VERSION "HNNBNNNYNNNNNNNNNNNNNNNNNNNNNNNNNNNNNNNNNN/4/%%%/4/'%**4NNN///"

NS_ :

BS_:

BU_: _4CL_C6 _6HP_C6 Airbag_C6 CVT_C6 DME_EDC16CP3000 DME_ME7_MED9_C6 DME_SIMOS6_C6 DME_Slave EPB_C6 ESP8_C6 Gateway_C6 LWR_AFS_C6 LWS_C6

BO_ 1160 Motor_6: 8 DME_EDC16CP3000
 SG_ CHK_Motor6 : 0|8@1+ (1.0,0.0) [0.0|255.0] ""  CVT_C6
 SG_ Sollmoment_Getriebe : 8|8@1+ (0.39,0.0) [0.0|99.06] "%MDI"  _6HP_C6,CVT_C6
 SG_ Istmoment_Getriebe : 16|8@1+ (0.39,0.0) [0.0|99.06] "%MDI"  _6HP_C6,CVT_C6
 SG_ Hoeheninfo : 24|8@1+ (0.00781,0.0) [0.0|1.99219] ""  _6HP_C6
 SG_ GRA_Sollbeschleunigung : 32|8@1+ (0.024,-3.984) [-3.984|2.112] "m/s2"  _6HP_C6
 SG_ Rueckmeldung_Momentenintegral : 40|8@1+ (0.3921,0.0) [0.0|99.9855] ""  Vector__XXX
 SG_ Calculated_Load_Value m0  : 48|8@1+ (0.4,0.0) [0.0|101.6] "%"  Vector__XXX
 SG_ Absolute_Throttle_Position m1  : 48|8@1+ (0.4,0.0) [0.0|101.6] "%"  Vector__XXX
 SG_ Engine_Coolant_Temperature m2  : 48|8@1+ (1.0,-40.0) [-40.0|215.0] "°C"  Vector__XXX
 SG_ Absolute_Load_Value m3  : 48|8@1+ (3.14,0.0) [0.0|800.7] "%"  Vector__XXX
 SG_ Accelerator_Pedal_Position m4  : 48|8@1+ (0.4,0.0) [0.0|101.6] "%"  Vector__XXX
 SG_ GRA_Bremseingrifffreigabe : 56|1@1+ (1.0,0.0) [0.0|1.0] ""  Vector__XXX
 SG_ Oeltemperaturschutz : 57|1@1+ (1.0,0.0) [0.0|1.0] ""  _6HP_C6
 SG_ Luftpfad_aktiv : 58|1@1+ (1.0,0.0) [0.0|1.0] ""  Vector__XXX
 SG_ Partikelfilter_Regeneration : 59|1@1+ (1.0,0.0) [0.0|1.0] ""  _6HP_C6
 SG_ BZ_Muxcode_Motor6 M  : 60|4@1+ (1.0,0.0) [0.0|15.0] ""  CVT_C6

BO_ 1416 Motor_7: 8 DME_EDC16CP3000
 SG_ RLS_Stufe1 : 0|1@1+ (1.0,0.0) [0.0|1.0] ""  Gateway_C6
 SG_ V_Begrenz_Aktivierbar : 1|1@1+ (1.0,0.0) [0.0|1.0] ""  Gateway_C6
 SG_ V_Begrenz_Aktiv : 2|1@1+ (1.0,0.0) [0.0|1.0] ""  Gateway_C6
 SG_ FSPE_Motor7 : 3|1@1+ (1.0,0.0) [0.0|1.0] ""  Gateway_C6
 SG_ FStatus_Oeltemp_Motor : 4|1@1+ (1.0,0.0) [0.0|1.0] ""  Gateway_C6
 SG_ PTC_Gluehstifte_ausgeschaltet : 5|3@1+ (1.0,0.0) [0.0|7.0] ""  Gateway_C6
 SG_ Klemme_DFM : 8|8@1+ (0.4,0.0) [0.0|101.6] "%"  Gateway_C6
 SG_ Hoeheninfo : 16|8@1+ (0.00781,0.0) [0.0|1.99219] ""  Gateway_C6
 SG_ MDG : 24|7@1+ (1.0,0.0) [0.0|126.0] "1/min"  Gateway_C6
 SG_ Signum_MDG : 31|1@1+ (1.0,0.0) [0.0|1.0] ""  Gateway_C6
 SG_ Ladedruck : 32|8@1+ (0.01,0.0) [0.0|2.54] "bar"  Gateway_C6
 SG_ GLR_Motor : 40|2@1+ (3.0,0.0) [0.0|9.0] "s"  Gateway_C6
 SG_ Bereitschaft_PTC_Heizung : 42|2@1+ (1.0,0.0) [0.0|3.0] ""  Gateway_C6
 SG_ Zusaetzliche_Kuehlung : 45|1@1+ (1.0,0.0) [0.0|1.0] ""  Gateway_C6
 SG_ SIB_Motor : 46|1@1+ (1.0,0.0) [0.0|1.0] ""  Gateway_C6
 SG_ RLS_Stufe2 : 47|1@1+ (1.0,0.0) [0.0|1.0] ""  Gateway_C6
 SG_ Lastabwurf : 48|2@1+ (1.0,0.0) [0.0|3.0] ""  Gateway_C6
 SG_ Einschalten_Generator : 50|1@1+ (1.0,0.0) [0.0|1.0] ""  Gateway_C6
 SG_ Lastabwurf_Heizsysteme : 51|1@1+ (1.0,0.0) [0.0|1.0] ""  Gateway_C6
 SG_ Gluehkerzen_Brennr : 52|4@1+ (8.0,0.0) [0.0|120.0] "%"  Gateway_C6
 SG_ Oeltemperatur : 56|8@1+ (1.0,-60.0) [-58.0|194.0] "°C"  Gateway_C6

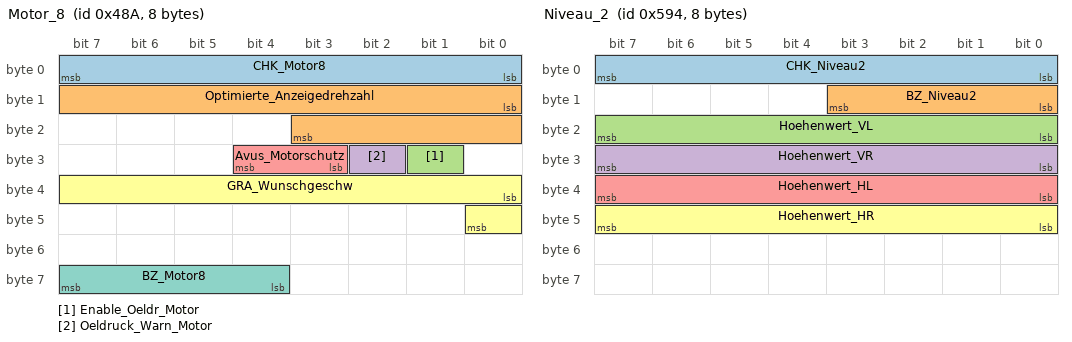
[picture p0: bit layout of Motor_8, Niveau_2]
BO_ 1162 Motor_8: 8 DME_EDC16CP3000
 SG_ CHK_Motor8 : 0|8@1+ (1.0,0.0) [0.0|255.0] ""  Gateway_C6
 SG_ Optimierte_Anzeigedrehzahl : 8|12@1+ (3.0,0.0) [0.0|12282.0] "1/min"  Gateway_C6
 SG_ Enable_Oeldr_Motor : 25|1@1+ (1.0,0.0) [0.0|1.0] ""  Gateway_C6
 SG_ Oeldruck_Warn_Motor : 26|1@1+ (1.0,0.0) [0.0|1.0] ""  Gateway_C6
 SG_ Avus_Motorschutz : 27|2@1+ (1.0,0.0) [0.0|3.0] ""  Gateway_C6
 SG_ GRA_Wunschgeschw : 32|9@1+ (1.0,0.0) [0.0|511.0] "km/h"  Gateway_C6
 SG_ BZ_Motor8 : 60|4@1+ (1.0,0.0) [0.0|15.0] ""  Gateway_C6

BO_ 1408 Motor_Flexia_Neu: 8 DME_EDC16CP3000
 SG_ Mux_Code_MFn M  : 0|2@1+ (1.0,0.0) [0.0|3.0] ""  Gateway_C6
 SG_ BZ_MFn_Rest : 2|2@1+ (1.0,0.0) [0.0|3.0] ""  Gateway_C6
 SG_ Driving_Cycle : 4|1@1+ (1.0,0.0) [0.0|1.0] ""  Gateway_C6
 SG_ Warm_Up_Cycle : 5|1@1+ (1.0,0.0) [0.0|1.0] ""  _6HP_C6,Gateway_C6
 SG_ Normed_Trip : 6|1@1+ (1.0,0.0) [0.0|1.0] ""  Gateway_C6
 SG_ Verbrennungsart : 7|1@1+ (1.0,0.0) [0.0|1.0] ""  ESP8_C6,Gateway_C6
 SG_ Russaequivalent m0  : 8|16@1+ (2.0E-8,0.0) [0.0|0.00131068] ""  Gateway_C6
 SG_ Verschleissequivalent m1  : 8|16@1+ (2.0E-8,0.0) [0.0|0.00131068] ""  Gateway_C6
 SG_ Russaequivalent m2  : 8|16@1+ (2.0E-8,0.0) [0.0|0.00131068] ""  Gateway_C6
 SG_ Verschleissequivalent m3  : 8|16@1+ (2.0E-8,0.0) [0.0|0.00131068] ""  Gateway_C6
 SG_ Drehzahl_MaxMom m0  : 24|8@1+ (100.0,0.0) [0.0|25500.0] "1/min"  Gateway_C6
 SG_ Kurzzeitmittelwert m1  : 24|8@1+ (15.0,-1905.0) [-1890.0|1905.0] "ml"  Gateway_C6
 SG_ Drehzahl_MaxMom m2  : 24|8@1+ (100.0,0.0) [0.0|25500.0] "1/min"  Gateway_C6
 SG_ Intervall_Wmin m3  : 24|7@1+ (1000.0,0.0) [0.0|127000.0] "km"  Gateway_C6
 SG_ Ueberfuellerkennung_aktiv m3  : 31|1@1+ (1.0,0.0) [0.0|1.0] ""  Gateway_C6
 SG_ Max_Drehmoment_2550Nm m0  : 32|8@1+ (10.0,0.0) [0.0|2550.0] "Nm"  Gateway_C6
 SG_ Oelstandszaehler m1  : 32|6@1+ (1.0,0.0) [0.0|63.0] ""  Gateway_C6
 SG_ Max_Drehmoment_2550Nm m2  : 32|8@1+ (10.0,0.0) [0.0|2550.0] "Nm"  Gateway_C6
 SG_ Intervall_Wmax m3  : 32|7@1+ (1000.0,0.0) [0.0|127000.0] "km"  Gateway_C6
 SG_ Oelwarnung m1  : 38|1@1+ (1.0,0.0) [0.0|1.0] ""  Gateway_C6
 SG_ Sensorwarnung m1  : 39|1@1+ (1.0,0.0) [0.0|1.0] ""  Gateway_C6
 SG_ Schwellwert_Max_Oelstand m3  : 39|5@1+ (100.0,0.0) [0.0|3100.0] "ml"  Gateway_C6
 SG_ Motorleistung m0  : 40|9@1+ (1.0,0.0) [0.0|511.0] "kW"  Gateway_C6
 SG_ Anzahl_Mittelung_sO m1  : 40|4@1+ (100.0,0.0) [0.0|1500.0] ""  Gateway_C6
 SG_ Motorleistung m2  : 40|9@1+ (1.0,0.0) [0.0|511.0] "kW"  ESP8_C6,Gateway_C6
 SG_ Maximum_Offset m1  : 44|4@1+ (50.0,0.0) [0.0|750.0] "ml"  Gateway_C6
 SG_ Anzahl_Mittelwert_gO m3  : 44|4@1+ (500.0,0.0) [0.0|7500.0] ""  Gateway_C6
 SG_ Ueberfuell_Hysterese m1  : 48|4@1+ (50.0,0.0) [0.0|750.0] "ml"  Gateway_C6
 SG_ Intervall_tmin m3  : 48|6@1+ (1.0,0.0) [0.0|63.0] "month"  Gateway_C6
 SG_ Anzahl_Ventile m0  : 49|3@1+ (1.0,0.0) [0.0|7.0] ""  Gateway_C6
 SG_ Anzahl_Ventile m2  : 49|3@1+ (1.0,0.0) [0.0|7.0] ""  Gateway_C6
 SG_ Anzahl_Zylinder m0  : 52|4@1+ (1.0,0.0) [0.0|15.0] ""  ESP8_C6,Gateway_C6
 SG_ Oelwarnschwellen_Offset m1  : 52|6@1+ (10.0,0.0) [0.0|630.0] "ml"  Gateway_C6
 SG_ Anzahl_Zylinder m2  : 52|4@1+ (1.0,0.0) [0.0|15.0] ""  Gateway_C6
 SG_ Intervall_tmax m3  : 54|6@1+ (1.0,0.0) [0.0|63.0] "month"  Gateway_C6
 SG_ Hubraum m0  : 56|7@1+ (0.1,0.0) [0.0|12.7] "l"  ESP8_C6,Gateway_C6
 SG_ Hubraum m2  : 56|7@1+ (0.1,0.0) [0.0|12.7] "l"  Gateway_C6
 SG_ Oelwarnschwellen_Toleranz m1  : 58|6@1+ (10.0,0.0) [0.0|630.0] "ml"  Gateway_C6
 SG_ Strecke_Mittelung m3  : 60|4@1+ (25.0,0.0) [0.0|375.0] "km"  Gateway_C6
 SG_ Ansaugsystem m0  : 63|1@1+ (1.0,0.0) [0.0|1.0] ""  ESP8_C6,Gateway_C6
 SG_ Ansaugsystem m2  : 63|1@1+ (1.0,0.0) [0.0|1.0] ""  Gateway_C6

BO_ 1823 Motorslave_Istverbau: 1 DME_Slave
 SG_ FSPE_Motorslave : 0|1@1+ (1.0,0.0) [0.0|1.0] ""  Gateway_C6

BO_ 1424 Niveau_1: 8 _4CL_C6
 SG_ CHK_Niveau1 : 0|8@1+ (1.0,0.0) [0.0|255.0] ""  ESP8_C6,Gateway_C6
 SG_ BZ_Niveau1 : 8|4@1+ (1.0,0.0) [0.0|15.0] ""  ESP8_C6,Gateway_C6
 SG_ Fehlerlampe_Niveau : 12|1@1+ (1.0,0.0) [0.0|1.0] ""  Gateway_C6
 SG_ Warnlampe : 13|1@1+ (1.0,0.0) [0.0|1.0] ""  Gateway_C6
 SG_ ESP_Beeinflussung : 14|1@1+ (1.0,0.0) [0.0|1.0] ""  ESP8_C6,Gateway_C6
 SG_ MSG_Einschraenkung : 15|1@1+ (1.0,0.0) [0.0|1.0] ""  Gateway_C6
 SG_ Niveaustati : 16|4@1+ (1.0,0.0) [0.0|15.0] ""  Gateway_C6
 SG_ Zwischenniveau : 20|1@1+ (1.0,0.0) [0.0|1.0] ""  Gateway_C6
 SG_ Parkniveau : 21|1@1+ (1.0,0.0) [0.0|1.0] ""  Gateway_C6
 SG_ Taster_Niveau : 22|1@1+ (1.0,0.0) [0.0|1.0] ""  Gateway_C6
 SG_ Verstellung_in_Kuerze : 23|1@1+ (1.0,0.0) [0.0|1.0] ""  Gateway_C6
 SG_ Kompressorlauf_in_Kuerze : 24|1@1+ (1.0,0.0) [0.0|1.0] ""  Gateway_C6
 SG_ Verstellung_aktiv : 25|1@1+ (1.0,0.0) [0.0|1.0] ""  Gateway_C6
 SG_ Anhebung_Fahrzeug : 26|1@1+ (1.0,0.0) [0.0|1.0] ""  Gateway_C6,LWR_AFS_C6
 SG_ Absenkung_Fahrzeug : 27|1@1+ (1.0,0.0) [0.0|1.0] ""  Gateway_C6,LWR_AFS_C6
 SG_ Verstellung_VR : 28|1@1+ (1.0,0.0) [0.0|1.0] ""  Gateway_C6
 SG_ Verstellung_VL : 29|1@1+ (1.0,0.0) [0.0|1.0] ""  Gateway_C6
 SG_ Verstellung_HR : 30|1@1+ (1.0,0.0) [0.0|1.0] ""  Gateway_C6
 SG_ Verstellung_HL : 31|1@1+ (1.0,0.0) [0.0|1.0] ""  Gateway_C6
 SG_ Textbits_Niveau : 32|4@1+ (1.0,0.0) [0.0|15.0] ""  Gateway_C6
 SG_ Fahrzeugart_Niveau : 36|1@1+ (1.0,0.0) [0.0|1.0] ""  Gateway_C6
 SG_ SIB_Niveau : 37|1@1+ (1.0,0.0) [0.0|1.0] ""  Gateway_C6
 SG_ Systemstatus : 38|1@1+ (1.0,0.0) [0.0|1.0] ""  Gateway_C6
 SG_ FSPE_Niveau1 : 39|1@1+ (1.0,0.0) [0.0|1.0] ""  Gateway_C6
 SG_ Beladungszustand : 40|8@1+ (1.0,0.0) [0.0|253.0] "%"  Gateway_C6
 SG_ Stromaufnahme : 48|8@1+ (1.0,0.0) [0.0|253.0] "A"  Gateway_C6
 SG_ Aufpruefbit_Warnlampe_Niveau : 56|1@1+ (1.0,0.0) [0.0|1.0] ""  Gateway_C6
 SG_ Tiefniveaulampe : 57|1@1+ (1.0,0.0) [0.0|1.0] ""  Gateway_C6
 SG_ Kompressor_laeuft : 58|1@1+ (1.0,0.0) [0.0|1.0] ""  Gateway_C6

BO_ 1428 Niveau_2: 8 _4CL_C6
 SG_ CHK_Niveau2 : 0|8@1+ (1.0,0.0) [0.0|255.0] ""  Vector__XXX
 SG_ BZ_Niveau2 : 8|4@1+ (1.0,0.0) [0.0|15.0] ""  Vector__XXX
 SG_ Hoehenwert_VL : 16|8@1+ (1.0,-127.0) [-127.0|126.0] "mm"  _6HP_C6,LWR_AFS_C6
 SG_ Hoehenwert_VR : 24|8@1+ (1.0,-127.0) [-127.0|126.0] "mm"  _6HP_C6,LWR_AFS_C6
 SG_ Hoehenwert_HL : 32|8@1+ (1.0,-127.0) [-127.0|126.0] "mm"  _6HP_C6,LWR_AFS_C6
 SG_ Hoehenwert_HR : 40|8@1+ (1.0,-127.0) [-127.0|126.0] "mm"  _6HP_C6,LWR_AFS_C6

BO_ 1434 Niveau_3: 6 _4CL_C6
 SG_ Textbit1 : 0|1@1+ (1.0,0.0) [0.0|1.0] ""  Gateway_C6
 SG_ Textbit2 : 1|1@1+ (1.0,0.0) [0.0|1.0] ""  Gateway_C6
 SG_ Textbit3 : 2|1@1+ (1.0,0.0) [0.0|1.0] ""  Gateway_C6
 SG_ Textbit4 : 3|1@1+ (1.0,0.0) [0.0|1.0] ""  Gateway_C6
 SG_ Verfuegbarkeit_FIS : 14|1@1+ (1.0,0.0) [0.0|1.0] ""  Gateway_C6
 SG_ Priorisierung_FIS : 15|1@1+ (1.0,0.0) [0.0|1.0] ""  Gateway_C6
 SG_ Anzeigebit9 : 16|1@1+ (1.0,0.0) [0.0|1.0] ""  Gateway_C6
 SG_ Anzeigebit10 : 17|1@1+ (1.0,0.0) [0.0|1.0] ""  Gateway_C6
 SG_ Anzeigebit17 : 24|1@1+ (1.0,0.0) [0.0|1.0] ""  Gateway_C6
 SG_ Anzeigebit18 : 25|1@1+ (1.0,0.0) [0.0|1.0] ""  Gateway_C6
 SG_ Anzeigebit19 : 26|1@1+ (1.0,0.0) [0.0|1.0] ""  Gateway_C6
 SG_ Anzeigebit20 : 27|1@1+ (1.0,0.0) [0.0|1.0] ""  Gateway_C6
 SG_ Anzeigebit21 : 28|1@1+ (1.0,0.0) [0.0|1.0] ""  Gateway_C6
 SG_ Anzeigebit22 : 29|1@1+ (1.0,0.0) [0.0|1.0] ""  Gateway_C6
 SG_ Anzeigebit23 : 30|1@1+ (1.0,0.0) [0.0|1.0] ""  Gateway_C6
 SG_ Anzeigebit24 : 31|1@1+ (1.0,0.0) [0.0|1.0] ""  Gateway_C6
 SG_ Anzeigebit25 : 32|1@1+ (1.0,0.0) [0.0|1.0] ""  Gateway_C6
 SG_ Anzeigebit26 : 33|1@1+ (1.0,0.0) [0.0|1.0] ""  Gateway_C6

BO_ 2004 PSD: 8 Gateway_C6
 SG_ Mux_Code_PSD M  : 0|2@1+ (1.0,0.0) [0.0|3.0] ""  Vector__XXX
 SG_ Geschwindigkeitsklasse_1 m0  : 2|4@1+ (1.0,0.0) [0.0|15.0] ""  Vector__XXX
 SG_ Geschwindigkeitsklasse_3 m1  : 2|4@1+ (1.0,0.0) [0.0|15.0] ""  Vector__XXX
 SG_ Geschwindigkeitsklasse_5 m2  : 2|4@1+ (1.0,0.0) [0.0|15.0] ""  Vector__XXX
 SG_ Strassenklasse_1 m0  : 6|2@1+ (1.0,0.0) [0.0|3.0] ""  Vector__XXX
 SG_ Strassenklasse_3 m1  : 6|2@1+ (1.0,0.0) [0.0|3.0] ""  Vector__XXX
 SG_ Strassenklasse_5 m2  : 6|2@1+ (1.0,0.0) [0.0|3.0] ""  Vector__XXX
 SG_ Segmentlaenge_1 m0  : 8|7@1+ (2.0,0.0) [0.0|254.0] "m"  Vector__XXX
 SG_ Segmentlaenge_3 m1  : 8|7@1+ (2.0,0.0) [0.0|254.0] "m"  Vector__XXX
 SG_ Segmentlaenge_5 m2  : 8|7@1+ (2.0,0.0) [0.0|254.0] "m"  Vector__XXX
 SG_ Signum_Endkruemmung_1 m0  : 15|1@1+ (1.0,0.0) [0.0|1.0] ""  Vector__XXX
 SG_ Signum_Endkruemmung_3 m1  : 15|1@1+ (1.0,0.0) [0.0|1.0] ""  Vector__XXX
 SG_ Signum_Endkruemmung_5 m2  : 15|1@1+ (1.0,0.0) [0.0|1.0] ""  Vector__XXX
 SG_ Endkruemmung_1 m0  : 16|8@1+ (1.0,0.0) [0.0|255.0] ""  Vector__XXX
 SG_ Endkruemmung_3 m1  : 16|8@1+ (1.0,0.0) [0.0|255.0] ""  Vector__XXX
 SG_ Endkruemmung_5 m2  : 16|8@1+ (1.0,0.0) [0.0|255.0] ""  Vector__XXX
 SG_ Bes_Geschw_klasse_1 m0  : 24|1@1+ (1.0,0.0) [0.0|1.0] ""  Vector__XXX
 SG_ Bes_Geschw_klasse_3 m1  : 24|1@1+ (1.0,0.0) [0.0|1.0] ""  Vector__XXX
 SG_ Bes_Geschw_klasse_5 m2  : 24|1@1+ (1.0,0.0) [0.0|1.0] ""  Vector__XXX
 SG_ Bes_Geschw_klasse_2 m0  : 25|1@1+ (1.0,0.0) [0.0|1.0] ""  Vector__XXX
 SG_ Bes_Geschw_klasse_4 m1  : 25|1@1+ (1.0,0.0) [0.0|1.0] ""  Vector__XXX
 SG_ Bes_Geschw_klasse_6 m2  : 25|1@1+ (1.0,0.0) [0.0|1.0] ""  Vector__XXX
 SG_ Geschwindigkeitsklasse_2 m0  : 26|4@1+ (1.0,0.0) [0.0|15.0] ""  Vector__XXX
 SG_ Geschwindigkeitsklasse_4 m1  : 26|4@1+ (1.0,0.0) [0.0|15.0] ""  Vector__XXX
 SG_ Geschwindigkeitsklasse_6 m2  : 26|4@1+ (1.0,0.0) [0.0|15.0] ""  Vector__XXX
 SG_ Strassenklasse_2 m0  : 30|2@1+ (1.0,0.0) [0.0|3.0] ""  Vector__XXX
 SG_ Strassenklasse_4 m1  : 30|2@1+ (1.0,0.0) [0.0|3.0] ""  Vector__XXX
 SG_ Strassenklasse_6 m2  : 30|2@1+ (1.0,0.0) [0.0|3.0] ""  Vector__XXX
 SG_ Segmentlaenge_2 m0  : 32|7@1+ (2.0,0.0) [0.0|127.0] "m"  Vector__XXX
 SG_ Segmentlaenge_4 m1  : 32|7@1+ (2.0,0.0) [0.0|127.0] "m"  Vector__XXX
 SG_ Segmentlaenge_6 m2  : 32|7@1+ (2.0,0.0) [0.0|127.0] "m"  Vector__XXX
 SG_ Signum_Endkruemmung_2 m0  : 39|1@1+ (1.0,0.0) [0.0|1.0] ""  Vector__XXX
 SG_ Signum_Endkruemmung_4 m1  : 39|1@1+ (1.0,0.0) [0.0|1.0] ""  Vector__XXX
 SG_ Signum_Endkruemmung_6 m2  : 39|1@1+ (1.0,0.0) [0.0|1.0] ""  Vector__XXX
 SG_ Endkruemmung_2 m0  : 40|8@1+ (1.0,0.0) [0.0|255.0] ""  Vector__XXX
 SG_ Endkruemmung_4 m1  : 40|8@1+ (1.0,0.0) [0.0|255.0] ""  Vector__XXX
 SG_ Endkruemmung_6 m2  : 40|8@1+ (1.0,0.0) [0.0|255.0] ""  Vector__XXX
 SG_ Alter_der_Daten m0  : 48|5@1+ (10.0,0.0) [0.0|310.0] "ms"  Vector__XXX
 SG_ Standort m1  : 48|2@1+ (1.0,0.0) [0.0|3.0] ""  Vector__XXX
 SG_ Status_Innerorts m2  : 48|1@1+ (1.0,0.0) [0.0|1.0] ""  Vector__XXX
 SG_ Status_Unterfuehrung m2  : 49|1@1+ (1.0,0.0) [0.0|1.0] ""  Vector__XXX
 SG_ Laengsfehler m1  : 50|3@1+ (1.0,0.0) [0.0|7.0] ""  Vector__XXX
 SG_ Aenderung_Innerorts m2  : 50|3@1+ (1.0,0.0) [0.0|7.0] ""  Vector__XXX
 SG_ Einheit_Geschw_klasse m0  : 53|1@1+ (1.0,0.0) [0.0|1.0] ""  Vector__XXX
 SG_ Digitalisierung m1  : 53|1@1+ (1.0,0.0) [0.0|1.0] ""  Vector__XXX
 SG_ Aenderung_Unterfuehrung m2  : 53|3@1+ (1.0,0.0) [0.0|7.0] ""  Vector__XXX
 SG_ Qualitaet m0  : 54|1@1+ (1.0,0.0) [0.0|1.0] ""  Vector__XXX
 SG_ Verkehrsrichtung m1  : 54|1@1+ (1.0,0.0) [0.0|1.0] ""  Vector__XXX
 SG_ Signum_Startkruemmung_1 m0  : 55|1@1+ (1.0,0.0) [0.0|1.0] ""  Vector__XXX
 SG_ Einbahnstrasse m1  : 55|1@1+ (1.0,0.0) [0.0|1.0] ""  Vector__XXX
 SG_ Startkruemmung_1 m0  : 56|8@1+ (1.0,0.0) [0.0|255.0] ""  Vector__XXX
 SG_ Fahrspuren_in_Fahrtrichtung m1  : 56|3@1+ (1.0,0.0) [0.0|7.0] ""  Vector__XXX
 SG_ Kreuzung m2  : 56|3@1+ (1.0,0.0) [0.0|7.0] ""  Vector__XXX
 SG_ Typ_besond_Geschw_klasse m1  : 59|3@1+ (1.0,0.0) [0.0|7.0] ""  Vector__XXX

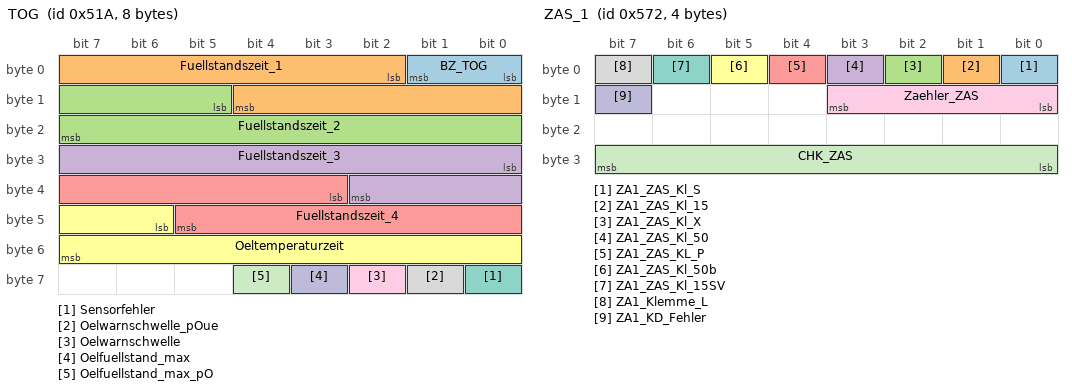
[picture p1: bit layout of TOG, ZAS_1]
BO_ 1306 TOG: 8 Gateway_C6
 SG_ BZ_TOG : 0|2@1+ (1.0,0.0) [0.0|3.0] ""  DME_EDC16CP3000,DME_ME7_MED9_C6,DME_SIMOS6_C6
 SG_ Fuellstandszeit_1 : 2|11@1+ (0.5,100.0) [101.0|1123.0] "ms"  DME_EDC16CP3000,DME_ME7_MED9_C6,DME_SIMOS6_C6
 SG_ Fuellstandszeit_2 : 13|11@1+ (0.5,100.0) [101.0|1123.0] "ms"  DME_EDC16CP3000,DME_ME7_MED9_C6,DME_SIMOS6_C6
 SG_ Fuellstandszeit_3 : 24|11@1+ (0.5,100.0) [101.0|1123.0] "ms"  DME_EDC16CP3000,DME_ME7_MED9_C6,DME_SIMOS6_C6
 SG_ Fuellstandszeit_4 : 35|11@1+ (0.5,100.0) [101.0|1123.0] "ms"  DME_EDC16CP3000,DME_ME7_MED9_C6,DME_SIMOS6_C6
 SG_ Oeltemperaturzeit : 46|10@1+ (0.125,0.0) [0.0|127.0] "ms"  DME_EDC16CP3000,DME_ME7_MED9_C6,DME_SIMOS6_C6
 SG_ Sensorfehler : 56|1@1+ (1.0,0.0) [0.0|1.0] ""  DME_EDC16CP3000,DME_ME7_MED9_C6,DME_SIMOS6_C6
 SG_ Oelwarnschwelle_pOue : 57|1@1+ (1.0,0.0) [0.0|1.0] ""  DME_EDC16CP3000,DME_ME7_MED9_C6,DME_SIMOS6_C6
 SG_ Oelwarnschwelle : 58|1@1+ (1.0,0.0) [0.0|1.0] ""  DME_EDC16CP3000,DME_ME7_MED9_C6,DME_SIMOS6_C6
 SG_ Oelfuellstand_max : 59|1@1+ (1.0,0.0) [0.0|1.0] ""  DME_EDC16CP3000,DME_SIMOS6_C6
 SG_ Oelfuellstand_max_pO : 60|1@1+ (1.0,0.0) [0.0|1.0] ""  DME_EDC16CP3000,DME_SIMOS6_C6

BO_ 1936 TP_dyn_ABS_1: 8 Vector__XXX
 SG_ TP_dyn_Data : 0|64@1+ (1.0,0.0) [0.0|1.8446744073709552E19] ""  Vector__XXX

BO_ 1937 TP_dyn_ABS_2: 8 Vector__XXX
 SG_ TP_dyn_Data : 0|64@1+ (1.0,0.0) [0.0|1.8446744073709552E19] ""  Vector__XXX

BO_ 1904 TP_dyn_ACC_1: 8 Vector__XXX
 SG_ TP_dyn_Data : 0|64@1+ (1.0,0.0) [0.0|1.8446744073709552E19] ""  Vector__XXX

BO_ 1905 TP_dyn_ACC_2: 8 Vector__XXX
 SG_ TP_dyn_Data : 0|64@1+ (1.0,0.0) [0.0|1.8446744073709552E19] ""  Vector__XXX

BO_ 1896 TP_dyn_Airbag_1: 8 Vector__XXX
 SG_ TP_dyn_Data : 0|64@1+ (1.0,0.0) [0.0|1.8446744073709552E19] ""  Airbag_C6

BO_ 1897 TP_dyn_Airbag_2: 8 Vector__XXX
 SG_ TP_dyn_Data : 0|64@1+ (1.0,0.0) [0.0|1.8446744073709552E19] ""  Airbag_C6

BO_ 822 TP_dyn_Anhaenger_1: 8 Vector__XXX
 SG_ TP_dyn_Data : 0|64@1+ (1.0,0.0) [0.0|1.8446744073709552E19] ""  Vector__XXX

BO_ 823 TP_dyn_Anhaenger_2: 8 Vector__XXX
 SG_ TP_dyn_Data : 0|64@1+ (1.0,0.0) [0.0|1.8446744073709552E19] ""  Vector__XXX

BO_ 812 TP_dyn_BEM_1: 8 Vector__XXX
 SG_ TP_dyn_Data : 0|64@1+ (1.0,0.0) [0.0|1.8446744073709552E19] ""  Vector__XXX

BO_ 813 TP_dyn_BEM_2: 8 Vector__XXX
 SG_ TP_dyn_Data : 0|64@1+ (1.0,0.0) [0.0|1.8446744073709552E19] ""  Vector__XXX

BO_ 1232 TP_dyn_Display_Info_1: 8 Vector__XXX
 SG_ TP_dyn_Data : 0|64@1+ (1.0,0.0) [0.0|1.8446744073709552E19] ""  Vector__XXX

BO_ 1233 TP_dyn_Display_Info_2: 8 Vector__XXX
 SG_ TP_dyn_Data : 0|64@1+ (1.0,0.0) [0.0|1.8446744073709552E19] ""  Vector__XXX

BO_ 1234 TP_dyn_Display_Info_3: 8 Vector__XXX
 SG_ TP_dyn_Data : 0|64@1+ (1.0,0.0) [0.0|1.8446744073709552E19] ""  Vector__XXX

BO_ 1235 TP_dyn_Display_Info_4: 8 Vector__XXX
 SG_ TP_dyn_Data : 0|64@1+ (1.0,0.0) [0.0|1.8446744073709552E19] ""  Vector__XXX

BO_ 1924 TP_dyn_Dyn_LWR_1: 8 Vector__XXX
 SG_ TP_dyn_Data : 0|64@1+ (1.0,0.0) [0.0|1.8446744073709552E19] ""  Vector__XXX

BO_ 1925 TP_dyn_Dyn_LWR_2: 8 Vector__XXX
 SG_ TP_dyn_Data : 0|64@1+ (1.0,0.0) [0.0|1.8446744073709552E19] ""  Vector__XXX

BO_ 818 TP_dyn_Einparkhilfe_1: 8 Vector__XXX
 SG_ TP_dyn_Data : 0|64@1+ (1.0,0.0) [0.0|1.8446744073709552E19] ""  Vector__XXX

BO_ 819 TP_dyn_Einparkhilfe_2: 8 Vector__XXX
 SG_ TP_dyn_Data : 0|64@1+ (1.0,0.0) [0.0|1.8446744073709552E19] ""  Vector__XXX

BO_ 1940 TP_dyn_EPB_1: 8 Vector__XXX
 SG_ TP_dyn_Data : 0|64@1+ (1.0,0.0) [0.0|1.8446744073709552E19] ""  Vector__XXX

BO_ 1941 TP_dyn_EPB_2: 8 Vector__XXX
 SG_ TP_dyn_Data : 0|64@1+ (1.0,0.0) [0.0|1.8446744073709552E19] ""  Vector__XXX

BO_ 816 TP_dyn_EZS_1: 8 Vector__XXX
 SG_ TP_dyn_Data : 0|64@1+ (1.0,0.0) [0.0|1.8446744073709552E19] ""  Vector__XXX

BO_ 817 TP_dyn_EZS_2: 8 Vector__XXX
 SG_ TP_dyn_Data : 0|64@1+ (1.0,0.0) [0.0|1.8446744073709552E19] ""  Vector__XXX

BO_ 762 TP_dyn_Fingerprint_1: 8 Vector__XXX
 SG_ TP_dyn_Data : 0|64@1+ (1.0,0.0) [0.0|1.8446744073709552E19] ""  Vector__XXX

BO_ 763 TP_dyn_Fingerprint_2: 8 Vector__XXX
 SG_ TP_dyn_Data : 0|64@1+ (1.0,0.0) [0.0|1.8446744073709552E19] ""  Vector__XXX

BO_ 814 TP_dyn_Gateway_1: 8 Vector__XXX
 SG_ TP_dyn_Data : 0|64@1+ (1.0,0.0) [0.0|1.8446744073709552E19] ""  Vector__XXX

BO_ 815 TP_dyn_Gateway_2: 8 Vector__XXX
 SG_ TP_dyn_Data : 0|64@1+ (1.0,0.0) [0.0|1.8446744073709552E19] ""  Vector__XXX

BO_ 1888 TP_dyn_Getriebe_1: 8 Vector__XXX
 SG_ TP_dyn_Data : 0|64@1+ (1.0,0.0) [0.0|1.8446744073709552E19] ""  _6HP_C6

BO_ 1889 TP_dyn_Getriebe_2: 8 Vector__XXX
 SG_ TP_dyn_Data : 0|64@1+ (1.0,0.0) [0.0|1.8446744073709552E19] ""  _6HP_C6

BO_ 756 TP_dyn_HDSG_1: 8 Vector__XXX
 SG_ TP_dyn_Data : 0|64@1+ (1.0,0.0) [0.0|1.8446744073709552E19] ""  Vector__XXX

BO_ 757 TP_dyn_HDSG_2: 8 Vector__XXX
 SG_ TP_dyn_Data : 0|64@1+ (1.0,0.0) [0.0|1.8446744073709552E19] ""  Vector__XXX

BO_ 808 TP_dyn_ILM_hinten_1: 8 Vector__XXX
 SG_ TP_dyn_Data : 0|64@1+ (1.0,0.0) [0.0|1.8446744073709552E19] ""  Vector__XXX

BO_ 809 TP_dyn_ILM_hinten_2: 8 Vector__XXX
 SG_ TP_dyn_Data : 0|64@1+ (1.0,0.0) [0.0|1.8446744073709552E19] ""  Vector__XXX

BO_ 824 TP_dyn_ILM_vl_1: 8 Vector__XXX
 SG_ TP_dyn_Data : 0|64@1+ (1.0,0.0) [0.0|1.8446744073709552E19] ""  Vector__XXX

BO_ 825 TP_dyn_ILM_vl_2: 8 Vector__XXX
 SG_ TP_dyn_Data : 0|64@1+ (1.0,0.0) [0.0|1.8446744073709552E19] ""  Vector__XXX

BO_ 760 TP_dyn_ILM_vr_1: 8 Vector__XXX
 SG_ TP_dyn_Data : 0|64@1+ (1.0,0.0) [0.0|1.8446744073709552E19] ""  Vector__XXX

BO_ 761 TP_dyn_ILM_vr_2: 8 Vector__XXX
 SG_ TP_dyn_Data : 0|64@1+ (1.0,0.0) [0.0|1.8446744073709552E19] ""  Vector__XXX

BO_ 828 TP_dyn_Klima_1: 8 Vector__XXX
 SG_ TP_dyn_Data : 0|64@1+ (1.0,0.0) [0.0|1.8446744073709552E19] ""  Vector__XXX

BO_ 829 TP_dyn_Klima_2: 8 Vector__XXX
 SG_ TP_dyn_Data : 0|64@1+ (1.0,0.0) [0.0|1.8446744073709552E19] ""  Vector__XXX

BO_ 830 TP_dyn_Klima_hl_1: 8 Vector__XXX
 SG_ TP_dyn_Data : 0|64@1+ (1.0,0.0) [0.0|1.8446744073709552E19] ""  Vector__XXX

BO_ 831 TP_dyn_Klima_hl_2: 8 Vector__XXX
 SG_ TP_dyn_Data : 0|64@1+ (1.0,0.0) [0.0|1.8446744073709552E19] ""  Vector__XXX

BO_ 1872 TP_dyn_Kombi_1: 8 Vector__XXX
 SG_ TP_dyn_Data : 0|64@1+ (1.0,0.0) [0.0|1.8446744073709552E19] ""  Vector__XXX

BO_ 1873 TP_dyn_Kombi_2: 8 Vector__XXX
 SG_ TP_dyn_Data : 0|64@1+ (1.0,0.0) [0.0|1.8446744073709552E19] ""  Vector__XXX

BO_ 1956 TP_dyn_LDW_1: 8 Vector__XXX
 SG_ TP_dyn_Data : 0|64@1+ (1.0,0.0) [0.0|1.8446744073709552E19] ""  Vector__XXX

BO_ 1957 TP_dyn_LDW_2: 8 Vector__XXX
 SG_ TP_dyn_Data : 0|64@1+ (1.0,0.0) [0.0|1.8446744073709552E19] ""  Vector__XXX

BO_ 794 TP_dyn_Mem_BFS_1: 8 Vector__XXX
 SG_ TP_dyn_Data : 0|64@1+ (1.0,0.0) [0.0|1.8446744073709552E19] ""  Vector__XXX

BO_ 795 TP_dyn_Mem_BFS_2: 8 Vector__XXX
 SG_ TP_dyn_Data : 0|64@1+ (1.0,0.0) [0.0|1.8446744073709552E19] ""  Vector__XXX

BO_ 792 TP_dyn_Mem_FS_1: 8 Vector__XXX
 SG_ TP_dyn_Data : 0|64@1+ (1.0,0.0) [0.0|1.8446744073709552E19] ""  Vector__XXX

BO_ 793 TP_dyn_Mem_FS_2: 8 Vector__XXX
 SG_ TP_dyn_Data : 0|64@1+ (1.0,0.0) [0.0|1.8446744073709552E19] ""  Vector__XXX

BO_ 766 TP_dyn_MFG_1: 8 Vector__XXX
 SG_ TP_dyn_Data : 0|64@1+ (1.0,0.0) [0.0|1.8446744073709552E19] ""  Vector__XXX

BO_ 767 TP_dyn_MFG_2: 8 Vector__XXX
 SG_ TP_dyn_Data : 0|64@1+ (1.0,0.0) [0.0|1.8446744073709552E19] ""  Vector__XXX

BO_ 1856 TP_dyn_Motor_1: 8 Vector__XXX
 SG_ TP_dyn_Data : 0|64@1+ (1.0,0.0) [0.0|1.8446744073709552E19] ""  DME_EDC16CP3000,DME_ME7_MED9_C6,DME_SIMOS6_C6

BO_ 1857 TP_dyn_Motor_2: 8 Vector__XXX
 SG_ TP_dyn_Data : 0|64@1+ (1.0,0.0) [0.0|1.8446744073709552E19] ""  DME_EDC16CP3000,DME_ME7_MED9_C6,DME_SIMOS6_C6

BO_ 1858 TP_dyn_Motor_3: 8 Vector__XXX
 SG_ TP_dyn_Data : 0|64@1+ (1.0,0.0) [0.0|1.8446744073709552E19] ""  DME_EDC16CP3000,DME_ME7_MED9_C6,DME_SIMOS6_C6

BO_ 1859 TP_dyn_Motor_4: 8 Vector__XXX
 SG_ TP_dyn_Data : 0|64@1+ (1.0,0.0) [0.0|1.8446744073709552E19] ""  DME_EDC16CP3000,DME_ME7_MED9_C6,DME_SIMOS6_C6

BO_ 1860 TP_dyn_Motor_Slave_1_1: 8 Vector__XXX
 SG_ TP_dyn_Data : 0|64@1+ (1.0,0.0) [0.0|1.8446744073709552E19] ""  DME_Slave

BO_ 1861 TP_dyn_Motor_Slave_1_2: 8 Vector__XXX
 SG_ TP_dyn_Data : 0|64@1+ (1.0,0.0) [0.0|1.8446744073709552E19] ""  DME_Slave

BO_ 1864 TP_dyn_Motor_Slave_2_1: 8 Vector__XXX
 SG_ TP_dyn_Data : 0|64@1+ (1.0,0.0) [0.0|1.8446744073709552E19] ""  Vector__XXX

BO_ 1865 TP_dyn_Motor_Slave_2_2: 8 Vector__XXX
 SG_ TP_dyn_Data : 0|64@1+ (1.0,0.0) [0.0|1.8446744073709552E19] ""  Vector__XXX

BO_ 1240 TP_dyn_Navigation_1: 8 Vector__XXX
 SG_ TP_dyn_Data : 0|64@1+ (1.0,0.0) [0.0|1.8446744073709552E19] ""  Vector__XXX

BO_ 1241 TP_dyn_Navigation_2: 8 Vector__XXX
 SG_ TP_dyn_Data : 0|64@1+ (1.0,0.0) [0.0|1.8446744073709552E19] ""  Vector__XXX

BO_ 1928 TP_dyn_Niveau_1: 8 Vector__XXX
 SG_ TP_dyn_Data : 0|64@1+ (1.0,0.0) [0.0|1.8446744073709552E19] ""  Vector__XXX

BO_ 1929 TP_dyn_Niveau_2: 8 Vector__XXX
 SG_ TP_dyn_Data : 0|64@1+ (1.0,0.0) [0.0|1.8446744073709552E19] ""  Vector__XXX

BO_ 802 TP_dyn_RDK_1: 8 Vector__XXX
 SG_ TP_dyn_Data : 0|64@1+ (1.0,0.0) [0.0|1.8446744073709552E19] ""  Vector__XXX

BO_ 803 TP_dyn_RDK_2: 8 Vector__XXX
 SG_ TP_dyn_Data : 0|64@1+ (1.0,0.0) [0.0|1.8446744073709552E19] ""  Vector__XXX

BO_ 764 TP_dyn_SMLS_1: 8 Vector__XXX
 SG_ TP_dyn_Data : 0|64@1+ (1.0,0.0) [0.0|1.8446744073709552E19] ""  Vector__XXX

BO_ 765 TP_dyn_SMLS_2: 8 Vector__XXX
 SG_ TP_dyn_Data : 0|64@1+ (1.0,0.0) [0.0|1.8446744073709552E19] ""  Vector__XXX

BO_ 804 TP_dyn_Standheizung_1: 8 Vector__XXX
 SG_ TP_dyn_Data : 0|64@1+ (1.0,0.0) [0.0|1.8446744073709552E19] ""  Vector__XXX

BO_ 805 TP_dyn_Standheizung_2: 8 Vector__XXX
 SG_ TP_dyn_Data : 0|64@1+ (1.0,0.0) [0.0|1.8446744073709552E19] ""  Vector__XXX

BO_ 1976 TP_dyn_SWA_1: 8 Vector__XXX
 SG_ TP_dyn_Data : 0|64@1+ (1.0,0.0) [0.0|1.8446744073709552E19] ""  Vector__XXX

BO_ 1977 TP_dyn_SWA_2: 8 Vector__XXX
 SG_ TP_dyn_Data : 0|64@1+ (1.0,0.0) [0.0|1.8446744073709552E19] ""  Vector__XXX

BO_ 1264 TP_dyn_Telefon_1: 8 Vector__XXX
 SG_ TP_dyn_Data : 0|64@1+ (1.0,0.0) [0.0|1.8446744073709552E19] ""  Vector__XXX

BO_ 1265 TP_dyn_Telefon_2: 8 Vector__XXX
 SG_ TP_dyn_Data : 0|64@1+ (1.0,0.0) [0.0|1.8446744073709552E19] ""  Vector__XXX

BO_ 1268 TP_dyn_Telematik_1: 8 Vector__XXX
 SG_ TP_dyn_Data : 0|64@1+ (1.0,0.0) [0.0|1.8446744073709552E19] ""  Vector__XXX

BO_ 1269 TP_dyn_Telematik_2: 8 Vector__XXX
 SG_ TP_dyn_Data : 0|64@1+ (1.0,0.0) [0.0|1.8446744073709552E19] ""  Vector__XXX

BO_ 768 TP_dyn_Tester_1_1: 8 Vector__XXX
 SG_ TP_dyn_Data : 0|64@1+ (1.0,0.0) [0.0|1.8446744073709552E19] ""  Vector__XXX

BO_ 769 TP_dyn_Tester_1_2: 8 Vector__XXX
 SG_ TP_dyn_Data : 0|64@1+ (1.0,0.0) [0.0|1.8446744073709552E19] ""  Vector__XXX

BO_ 786 TP_dyn_TSG_BT_1: 8 Vector__XXX
 SG_ TP_dyn_Data : 0|64@1+ (1.0,0.0) [0.0|1.8446744073709552E19] ""  Vector__XXX

BO_ 787 TP_dyn_TSG_BT_2: 8 Vector__XXX
 SG_ TP_dyn_Data : 0|64@1+ (1.0,0.0) [0.0|1.8446744073709552E19] ""  Vector__XXX

BO_ 784 TP_dyn_TSG_FT_1: 8 Vector__XXX
 SG_ TP_dyn_Data : 0|64@1+ (1.0,0.0) [0.0|1.8446744073709552E19] ""  Vector__XXX

BO_ 785 TP_dyn_TSG_FT_2: 8 Vector__XXX
 SG_ TP_dyn_Data : 0|64@1+ (1.0,0.0) [0.0|1.8446744073709552E19] ""  Vector__XXX

BO_ 788 TP_dyn_TSG_HL_1: 8 Vector__XXX
 SG_ TP_dyn_Data : 0|64@1+ (1.0,0.0) [0.0|1.8446744073709552E19] ""  Vector__XXX

BO_ 789 TP_dyn_TSG_HL_2: 8 Vector__XXX
 SG_ TP_dyn_Data : 0|64@1+ (1.0,0.0) [0.0|1.8446744073709552E19] ""  Vector__XXX

BO_ 790 TP_dyn_TSG_HR_1: 8 Vector__XXX
 SG_ TP_dyn_Data : 0|64@1+ (1.0,0.0) [0.0|1.8446744073709552E19] ""  Vector__XXX

BO_ 791 TP_dyn_TSG_HR_2: 8 Vector__XXX
 SG_ TP_dyn_Data : 0|64@1+ (1.0,0.0) [0.0|1.8446744073709552E19] ""  Vector__XXX

BO_ 515 TP_Er_ABS: 7 Vector__XXX
 SG_ TP_Er_Data : 0|56@1+ (1.0,0.0) [0.0|7.2057594037927936E16] ""  Vector__XXX

BO_ 523 TP_Er_ACC: 7 Vector__XXX
 SG_ TP_Er_Data : 0|56@1+ (1.0,0.0) [0.0|7.2057594037927936E16] ""  Vector__XXX

BO_ 517 TP_Er_Airbag: 7 Airbag_C6
 SG_ TP_Er_Data : 0|56@1+ (1.0,0.0) [0.0|7.2057594037927936E16] ""  Vector__XXX

BO_ 579 TP_Er_Anhaenger: 7 Vector__XXX
 SG_ TP_Er_Data : 0|56@1+ (1.0,0.0) [0.0|7.2057594037927936E16] ""  Vector__XXX

BO_ 563 TP_Er_BEM: 7 Vector__XXX
 SG_ TP_Er_Data : 0|56@1+ (1.0,0.0) [0.0|7.2057594037927936E16] ""  Vector__XXX

BO_ 591 TP_Er_DAB_Tuner: 7 Vector__XXX
 SG_ TP_Er_Data : 0|56@1+ (1.0,0.0) [0.0|7.2057594037927936E16] ""  Vector__XXX

BO_ 595 TP_Er_DSP: 7 Vector__XXX
 SG_ TP_Er_Data : 0|56@1+ (1.0,0.0) [0.0|7.2057594037927936E16] ""  Vector__XXX

BO_ 518 TP_Er_Dyn_LWR: 7 Vector__XXX
 SG_ TP_Er_Data : 0|56@1+ (1.0,0.0) [0.0|7.2057594037927936E16] ""  Vector__XXX

BO_ 557 TP_Er_Einparkhilfe: 7 Vector__XXX
 SG_ TP_Er_Data : 0|56@1+ (1.0,0.0) [0.0|7.2057594037927936E16] ""  Vector__XXX

BO_ 537 TP_Er_EPB: 7 Vector__XXX
 SG_ TP_Er_Data : 0|56@1+ (1.0,0.0) [0.0|7.2057594037927936E16] ""  Vector__XXX

BO_ 561 TP_Er_EZS: 7 Vector__XXX
 SG_ TP_Er_Data : 0|56@1+ (1.0,0.0) [0.0|7.2057594037927936E16] ""  Vector__XXX

BO_ 594 TP_Er_FM_Tuner_Radio: 7 Vector__XXX
 SG_ TP_Er_Data : 0|56@1+ (1.0,0.0) [0.0|7.2057594037927936E16] ""  Vector__XXX

BO_ 514 TP_Er_Getriebe: 7 _6HP_C6
 SG_ TP_Er_Data : 0|56@1+ (1.0,0.0) [0.0|7.2057594037927936E16] ""  Vector__XXX

BO_ 564 TP_Er_HDSG: 7 Vector__XXX
 SG_ TP_Er_Data : 0|56@1+ (1.0,0.0) [0.0|7.2057594037927936E16] ""  Vector__XXX

BO_ 606 TP_Er_Head_Unit_HL: 7 Vector__XXX
 SG_ TP_Er_Data : 0|56@1+ (1.0,0.0) [0.0|7.2057594037927936E16] ""  Vector__XXX

BO_ 605 TP_Er_Head_Unit_HR: 7 Vector__XXX
 SG_ TP_Er_Data : 0|56@1+ (1.0,0.0) [0.0|7.2057594037927936E16] ""  Vector__XXX

BO_ 545 TP_Er_ILM_hinten: 7 Vector__XXX
 SG_ TP_Er_Data : 0|56@1+ (1.0,0.0) [0.0|7.2057594037927936E16] ""  Vector__XXX

BO_ 544 TP_Er_ILM_vl: 7 Vector__XXX
 SG_ TP_Er_Data : 0|56@1+ (1.0,0.0) [0.0|7.2057594037927936E16] ""  Vector__XXX

BO_ 552 TP_Er_ILM_vr: 7 Vector__XXX
 SG_ TP_Er_Data : 0|56@1+ (1.0,0.0) [0.0|7.2057594037927936E16] ""  Vector__XXX

BO_ 556 TP_Er_Klima: 7 Vector__XXX
 SG_ TP_Er_Data : 0|56@1+ (1.0,0.0) [0.0|7.2057594037927936E16] ""  Vector__XXX

BO_ 581 TP_Er_Klimabed_hl: 7 Vector__XXX
 SG_ TP_Er_Data : 0|56@1+ (1.0,0.0) [0.0|7.2057594037927936E16] ""  Vector__XXX

BO_ 519 TP_Er_Kombi: 7 Vector__XXX
 SG_ TP_Er_Data : 0|56@1+ (1.0,0.0) [0.0|7.2057594037927936E16] ""  Vector__XXX

BO_ 584 TP_Er_Kombi_Grafik: 7 Vector__XXX
 SG_ TP_Er_Data : 0|56@1+ (1.0,0.0) [0.0|7.2057594037927936E16] ""  Vector__XXX

BO_ 538 TP_Er_LDW: 7 Vector__XXX
 SG_ TP_Er_Data : 0|56@1+ (1.0,0.0) [0.0|7.2057594037927936E16] ""  Vector__XXX

BO_ 531 TP_Er_LWS: 7 Vector__XXX
 SG_ TP_Er_Data : 0|56@1+ (1.0,0.0) [0.0|7.2057594037927936E16] ""  Vector__XXX

BO_ 600 TP_Er_Media_Player_1: 7 Vector__XXX
 SG_ TP_Er_Data : 0|56@1+ (1.0,0.0) [0.0|7.2057594037927936E16] ""  Vector__XXX

BO_ 592 TP_Er_Media_Player_2: 7 Vector__XXX
 SG_ TP_Er_Data : 0|56@1+ (1.0,0.0) [0.0|7.2057594037927936E16] ""  Vector__XXX

BO_ 596 TP_Er_Media_Player_3: 7 Vector__XXX
 SG_ TP_Er_Data : 0|56@1+ (1.0,0.0) [0.0|7.2057594037927936E16] ""  Vector__XXX

BO_ 610 TP_Er_Media_Player_4: 7 Vector__XXX
 SG_ TP_Er_Data : 0|56@1+ (1.0,0.0) [0.0|7.2057594037927936E16] ""  Vector__XXX

BO_ 565 TP_Er_Memory_BF: 7 Vector__XXX
 SG_ TP_Er_Data : 0|56@1+ (1.0,0.0) [0.0|7.2057594037927936E16] ""  Vector__XXX

BO_ 550 TP_Er_Memory_FS: 7 Vector__XXX
 SG_ TP_Er_Data : 0|56@1+ (1.0,0.0) [0.0|7.2057594037927936E16] ""  Vector__XXX

BO_ 570 TP_Er_MFG: 7 Vector__XXX
 SG_ TP_Er_Data : 0|56@1+ (1.0,0.0) [0.0|7.2057594037927936E16] ""  Vector__XXX

BO_ 575 TP_Er_MMI_Cockpit: 7 Vector__XXX
 SG_ TP_Er_Data : 0|56@1+ (1.0,0.0) [0.0|7.2057594037927936E16] ""  Vector__XXX

BO_ 574 TP_Er_MMI_Fond: 7 Vector__XXX
 SG_ TP_Er_Data : 0|56@1+ (1.0,0.0) [0.0|7.2057594037927936E16] ""  Vector__XXX

BO_ 513 TP_Er_Motor: 7 DME_EDC16CP3000
 SG_ TP_Er_Data : 0|56@1+ (1.0,0.0) [0.0|7.2057594037927936E16] ""  Vector__XXX

BO_ 533 TP_Er_Motor_Slave_1: 7 DME_Slave
 SG_ TP_Er_Data : 0|56@1+ (1.0,0.0) [0.0|7.2057594037927936E16] ""  Vector__XXX

BO_ 534 TP_Er_Motor_Slave_2: 7 Vector__XXX
 SG_ TP_Er_Data : 0|56@1+ (1.0,0.0) [0.0|7.2057594037927936E16] ""  Vector__XXX

BO_ 603 TP_Er_Navigation: 7 Vector__XXX
 SG_ TP_Er_Data : 0|56@1+ (1.0,0.0) [0.0|7.2057594037927936E16] ""  Vector__XXX

BO_ 516 TP_Er_Niveau: 7 Vector__XXX
 SG_ TP_Er_Data : 0|56@1+ (1.0,0.0) [0.0|7.2057594037927936E16] ""  Vector__XXX

BO_ 553 TP_Er_RDK: 7 Vector__XXX
 SG_ TP_Er_Data : 0|56@1+ (1.0,0.0) [0.0|7.2057594037927936E16] ""  Vector__XXX

BO_ 607 TP_Er_Satellite_Radio: 7 Vector__XXX
 SG_ TP_Er_Data : 0|56@1+ (1.0,0.0) [0.0|7.2057594037927936E16] ""  Vector__XXX

BO_ 604 TP_Er_SDS: 7 Vector__XXX
 SG_ TP_Er_Data : 0|56@1+ (1.0,0.0) [0.0|7.2057594037927936E16] ""  Vector__XXX

BO_ 554 TP_Er_SMLS: 7 Vector__XXX
 SG_ TP_Er_Data : 0|56@1+ (1.0,0.0) [0.0|7.2057594037927936E16] ""  Vector__XXX

BO_ 559 TP_Er_Standheizung: 7 Vector__XXX
 SG_ TP_Er_Data : 0|56@1+ (1.0,0.0) [0.0|7.2057594037927936E16] ""  Vector__XXX

BO_ 540 TP_Er_SWA: 7 Vector__XXX
 SG_ TP_Er_Data : 0|56@1+ (1.0,0.0) [0.0|7.2057594037927936E16] ""  Vector__XXX

BO_ 602 TP_Er_Telefon: 7 Vector__XXX
 SG_ TP_Er_Data : 0|56@1+ (1.0,0.0) [0.0|7.2057594037927936E16] ""  Vector__XXX

BO_ 597 TP_Er_Telematik: 7 Vector__XXX
 SG_ TP_Er_Data : 0|56@1+ (1.0,0.0) [0.0|7.2057594037927936E16] ""  Vector__XXX

BO_ 512 TP_Er_Tester_1: 7 Vector__XXX
 SG_ TP_Er_Data : 0|56@1+ (1.0,0.0) [0.0|7.2057594037927936E16] ""  Vector__XXX

BO_ 527 TP_Er_Tester_2: 7 Vector__XXX
 SG_ TP_Er_Data : 0|56@1+ (1.0,0.0) [0.0|7.2057594037927936E16] ""  Vector__XXX

BO_ 547 TP_Er_TSG_Beifahrer: 7 Vector__XXX
 SG_ TP_Er_Data : 0|56@1+ (1.0,0.0) [0.0|7.2057594037927936E16] ""  Vector__XXX

BO_ 546 TP_Er_TSG_Fahrer: 7 Vector__XXX
 SG_ TP_Er_Data : 0|56@1+ (1.0,0.0) [0.0|7.2057594037927936E16] ""  Vector__XXX

BO_ 548 TP_Er_TSG_hl: 7 Vector__XXX
 SG_ TP_Er_Data : 0|56@1+ (1.0,0.0) [0.0|7.2057594037927936E16] ""  Vector__XXX

BO_ 549 TP_Er_TSG_hr: 7 Vector__XXX
 SG_ TP_Er_Data : 0|56@1+ (1.0,0.0) [0.0|7.2057594037927936E16] ""  Vector__XXX

BO_ 599 TP_Er_TV_Tuner_analog: 7 Vector__XXX
 SG_ TP_Er_Data : 0|56@1+ (1.0,0.0) [0.0|7.2057594037927936E16] ""  Vector__XXX

BO_ 588 TP_Er_TV_Tuner_digital: 7 Vector__XXX
 SG_ TP_Er_Data : 0|56@1+ (1.0,0.0) [0.0|7.2057594037927936E16] ""  Vector__XXX

BO_ 1394 ZAS_1: 4 Gateway_C6
 SG_ ZA1_ZAS_Kl_S : 0|1@1+ (1.0,0.0) [0.0|1.0] ""  EPB_C6
 SG_ ZA1_ZAS_Kl_15 : 1|1@1+ (1.0,0.0) [0.0|1.0] ""  _4CL_C6,DME_SIMOS6_C6,EPB_C6
 SG_ ZA1_ZAS_Kl_X : 2|1@1+ (1.0,0.0) [0.0|1.0] ""  _4CL_C6,LWR_AFS_C6
 SG_ ZA1_ZAS_Kl_50 : 3|1@1+ (1.0,0.0) [0.0|1.0] ""  DME_SIMOS6_C6,EPB_C6,LWR_AFS_C6
 SG_ ZA1_ZAS_KL_P : 4|1@1+ (1.0,0.0) [0.0|1.0] ""  Vector__XXX
 SG_ ZA1_ZAS_Kl_50b : 5|1@1+ (1.0,0.0) [0.0|1.0] ""  Vector__XXX
 SG_ ZA1_ZAS_Kl_15SV : 6|1@1+ (1.0,0.0) [0.0|1.0] ""  Vector__XXX
 SG_ ZA1_Klemme_L : 7|1@1+ (1.0,0.0) [0.0|1.0] ""  Vector__XXX
 SG_ Zaehler_ZAS : 8|4@1+ (1.0,0.0) [0.0|15.0] ""  _4CL_C6,DME_SIMOS6_C6,EPB_C6
 SG_ ZA1_KD_Fehler : 15|1@1+ (1.0,0.0) [0.0|1.0] ""  Vector__XXX
 SG_ CHK_ZAS : 24|8@1+ (1.0,0.0) [0.0|255.0] ""  _4CL_C6,DME_SIMOS6_C6,EPB_C6

BO_TX_BU_ 1160 :DME_EDC16CP3000,DME_ME7_MED9_C6,DME_SIMOS6_C6;
BO_TX_BU_ 1416 :DME_EDC16CP3000,DME_ME7_MED9_C6,DME_SIMOS6_C6;
BO_TX_BU_ 1162 :DME_EDC16CP3000,DME_ME7_MED9_C6,DME_SIMOS6_C6;
BO_TX_BU_ 1408 :DME_EDC16CP3000,DME_ME7_MED9_C6,DME_SIMOS6_C6;
BO_TX_BU_ 513 :DME_EDC16CP3000,DME_ME7_MED9_C6,DME_SIMOS6_C6;
CM_ BO_ 822 "dynamischer Transportkanal";
CM_ BO_ 823 "dynamischer Transportkanal";
CM_ BO_ 812 "dynamischer Transportkanal";
CM_ BO_ 813 "dynamischer Transportkanal";
CM_ BO_ 1232 "dynamischer Transportkanal";
CM_ BO_ 1233 "dynamischer Transportkanal";
CM_ BO_ 1234 "dynamischer Transportkanal";
CM_ BO_ 1235 "dynamischer Transportkanal";
CM_ BO_ 818 "dynamischer Transportkanal";
CM_ BO_ 819 "dynamischer Transportkanal";
CM_ BO_ 816 "dynamischer Transportkanal";
CM_ BO_ 817 "dynamischer Transportkanal";
CM_ BO_ 762 "dynamischer Transportkanal";
CM_ BO_ 763 "dynamischer Transportkanal";
CM_ BO_ 814 "dynamischer Transportkanal";
CM_ BO_ 815 "dynamischer Transportkanal";
CM_ BO_ 756 "dynamischer Transportkanal";
CM_ BO_ 757 "dynamischer Transportkanal";
CM_ BO_ 808 "dynamischer Transportkanal";
CM_ BO_ 809 "dynamischer Transportkanal";
CM_ BO_ 824 "dynamischer Transportkanal";
CM_ BO_ 825 "dynamischer Transportkanal";
CM_ BO_ 760 "dynamischer Transportkanal";
CM_ BO_ 761 "dynamischer Transportkanal";
CM_ BO_ 828 "dynamischer Transportkanal";
CM_ BO_ 829 "dynamischer Transportkanal";
CM_ BO_ 830 "dynamischer Transportkanal";
CM_ BO_ 831 "dynamischer Transportkanal";
CM_ BO_ 1872 "dynamischer Transportkanal";
CM_ BO_ 1873 "dynamischer Transportkanal";
CM_ BO_ 1956 "dynamischer Transportkanal";
CM_ BO_ 1957 "dynamischer Transportkanal";
CM_ BO_ 794 "dynamischer Transportkanal";
CM_ BO_ 795 "dynamischer Transportkanal";
CM_ BO_ 792 "dynamischer Transportkanal";
CM_ BO_ 793 "dynamischer Transportkanal";
CM_ BO_ 766 "dynamischer Transportkanal";
CM_ BO_ 767 "dynamischer Transportkanal";
CM_ BO_ 1864 "dynamischer Transportkanal";
CM_ BO_ 1865 "dynamischer Transportkanal";
CM_ BO_ 1240 "dynamischer Transportkanal";
CM_ BO_ 1241 "dynamischer Transportkanal";
CM_ BO_ 802 "dynamischer Transportkanal";
CM_ BO_ 803 "dynamischer Transportkanal";
CM_ BO_ 764 "dynamischer Transportkanal";
CM_ BO_ 765 "dynamischer Transportkanal";
CM_ BO_ 804 "dynamischer Transportkanal";
CM_ BO_ 805 "dynamischer Transportkanal";
CM_ BO_ 1976 "dynamischer Transportkanal";
CM_ BO_ 1977 "dynamischer Transportkanal";
CM_ BO_ 1264 "dynamischer Transportkanal";
CM_ BO_ 1265 "dynamischer Transportkanal";
CM_ BO_ 786 "dynamischer Transportkanal";
CM_ BO_ 787 "dynamischer Transportkanal";
CM_ BO_ 784 "dynamischer Transportkanal";
CM_ BO_ 785 "dynamischer Transportkanal";
CM_ BO_ 788 "dynamischer Transportkanal";
CM_ BO_ 789 "dynamischer Transportkanal";
CM_ BO_ 790 "dynamischer Transportkanal";
CM_ BO_ 791 "dynamischer Transportkanal";
CM_ BO_ 579 "Transportkanal-Eröffnungskennungen";
CM_ BO_ 563 "Transportkanal-Eröffnungskennungen";
CM_ BO_ 591 "Transportkanal-Eröffnungskennungen";
CM_ BO_ 595 "Transportkanal-Eröffnungskennungen";
CM_ BO_ 557 "Transportkanal-Eröffnungskennungen";
CM_ BO_ 561 "Transportkanal-Eröffnungskennungen";
CM_ BO_ 594 "Transportkanal-Eröffnungskennungen";
CM_ BO_ 564 "Transportkanal-Eröffnungskennungen";
CM_ BO_ 606 "Transportkanal-Eröffnungskennungen";
CM_ BO_ 605 "Transportkanal-Eröffnungskennungen";
CM_ BO_ 545 "Transportkanal-Eröffnungskennungen";
CM_ BO_ 544 "Transportkanal-Eröffnungskennungen";
CM_ BO_ 552 "Transportkanal-Eröffnungskennungen";
CM_ BO_ 556 "Transportkanal-Eröffnungskennungen";
CM_ BO_ 581 "Transportkanal-Eröffnungskennungen";
CM_ BO_ 519 "Transportkanal-Eröffnungskennungen";
CM_ BO_ 584 "Transportkanal-Eröffnungskennungen";
CM_ BO_ 538 "Transportkanal-Eröffnungskennungen";
CM_ BO_ 600 "Transportkanal-Eröffnungskennungen";
CM_ BO_ 592 "Transportkanal-Eröffnungskennungen";
CM_ BO_ 596 "Transportkanal-Eröffnungskennungen";
CM_ BO_ 610 "Transportkanal-Eröffnungskennungen";
CM_ BO_ 565 "Transportkanal-Eröffnungskennungen";
CM_ BO_ 550 "Transportkanal-Eröffnungskennungen";
CM_ BO_ 570 "Transportkanal-Eröffnungskennungen";
CM_ BO_ 575 "Transportkanal-Eröffnungskennungen";
CM_ BO_ 574 "Transportkanal-Eröffnungskennungen";
CM_ BO_ 534 "Transportkanal-Eröffnungskennungen";
CM_ BO_ 603 "Transportkanal-Eröffnungskennungen";
CM_ BO_ 553 "Transportkanal-Eröffnungskennungen";
CM_ BO_ 607 "Transportkanal-Eröffnungskennungen";
CM_ BO_ 604 "Transportkanal-Eröffnungskennungen";
CM_ BO_ 554 "Transportkanal-Eröffnungskennungen";
CM_ BO_ 559 "Transportkanal-Eröffnungskennungen";
CM_ BO_ 540 "Transportkanal-Eröffnungskennungen";
CM_ BO_ 602 "Transportkanal-Eröffnungskennungen";
CM_ BO_ 597 "Transportkanal-Eröffnungskennungen";
CM_ BO_ 512 "Transportkanal-Eröffnungskennungen";
CM_ BO_ 527 "Transportkanal-Eröffnungskennungen";
CM_ BO_ 547 "Transportkanal-Eröffnungskennungen; Botschaft mMFS_BR mit dieser ID auf Infotainment-CAN vorhanden";
CM_ BO_ 546 "Transportkanal-Eröffnungskennungen";
CM_ BO_ 548 "Transportkanal-Eröffnungskennungen";
CM_ BO_ 549 "Transportkanal-Eröffnungskennungen";
CM_ BO_ 599 "Transportkanal-Eröffnungskennungen";
CM_ BO_ 588 "Transportkanal-Eröffnungskennungen";

CM_ SG_ 1160 Absolute_Load_Value "Beschreibung siehe Calculated Load Value";
CM_ SG_ 1160 Absolute_Throttle_Position "Beschreibung siehe Calculated Load Value";
CM_ SG_ 1160 BZ_Muxcode_Motor6 "Freilaufender 4Bit-Botschaftszähler; gleichzeitig Mux_Code";
CM_ SG_ 1160 Calculated_Load_Value "Übertragung von Meßgrößen an das Getriebesteuergerät für Freeze Frame Abspeicherung bei Getriebefehlern
siehe Tabelle Freeze Frame Data

0x0 = PID $04 Calculated Load Value; 0 .. 100% mit 100/255 %/bit		
0x1 = PID $11 Absolute Throttle Position; 0 .. ";
CM_ SG_ 1160 Engine_Coolant_Temperature "Beschreibung siehe Calculated Load Value";
CM_ SG_ 1160 GRA_Bremseingrifffreigabe "Sollbeschleunigung bzw. Bremseeingriff in Byte 5 freigegeben

0x0 = nicht freigegeben
0x1 = freigegeben
";
CM_ SG_ 1160 GRA_Sollbeschleunigung "Die im Motor-SG integrierte GRA gibt hier eine gesteuerte Soll-Beschleunigung aus (z. Zt. Nur bei Audi und im PQ46)

0xFF = nicht erlaubt";
CM_ SG_ 1160 Hoeheninfo "Korrekturfaktor Höhe (1 entspricht 1013 mbar)

0xFF = Fehler";
CM_ SG_ 1160 Istmoment_Getriebe "Istmoment ohne P und D Anteil des Leerlaufreglers, ohne Antiruckelfunktion und ohne Getriebeeingriff

0xFF = Fehler";
CM_ SG_ 1160 Luftpfad_aktiv "Getriebeeingriff wird zusätzlich zum Zündungspfad auch über den Luftpfad umgesetzt (nur im VW D1)

0x0 = kein Eingriff oder nur Eingriff über Zündpfad
0x1 = Eingriff über Luftpfad
";
CM_ SG_ 1160 Oeltemperaturschutz "Bei einer Töl > 150°C wird das Übertemperaturschutzbit gesetzt und das Getriebe schaltet vom 4.Gang in den 5.Gang bei Vmax. Bei einer Töl < 125°C wird dieses Bit zurück gesetzt und das Getriebe schaltet dann bei Vmax vom 5.Gang wieder in den 4.Gang zurück";
CM_ SG_ 1160 Partikelfilter_Regeneration "Für die Partikelfilterregeneration wird das Getriebe aufgefordert, ein drehzahlintensiveres Schaltprogramm zu aktivieren (Nur EDC16C Audi D3 / Audi C6!) / VW D1/Colorado)

0x0 = keine Beeinflussung
0x1 = Beeinflussung

";
CM_ SG_ 1160 Rueckmeldung_Momentenintegral "Nur für DQ-Getriebe mit alter Momentenschnittstelle: 100 %  entspricht volle Verfügbarkeit aktuell vorhanden. 0 % entspricht Integral bis Limit gefüllt, erhöhender Eingriff kann aktuell nicht berücksichtigt werden oder erhöhender Eingriff ist in diesem Pr";
CM_ SG_ 1160 Sollmoment_Getriebe "Sollmoment ohne P und D Anteil des Leerlaufreglers, ohne Antiruckelfunktion und ohne Getriebeeingriff

0xFF = Fehler";

CM_ SG_ 1416 Bereitschaft_PTC_Heizung "Bereitschaft dreistufiges PTC, z. Zt nur bei Audi geplant

00 = kein dreistufiges PTC verbaut
0x = 2x 300 W PTC-Stufe soll nicht eingeschaltet werden bzw. ist defekt (Diagnose)
1x = 2x 300 W PTC-Stufe soll eingeschaltet werden und ist bereit
x0 = 400";
CM_ SG_ 1416 Einschalten_Generator "Einschalten des Generators nach Motorstart. Einschalten evtl. mit Load-Response. Anmerkung: Solange der Generator ausgeschaltet ist, bleiben auch die Hochleistungsheizsysteme deaktiviert. Spätestens 5 sec nach Motorstart wird der Generator  zugeschaltet u";
CM_ SG_ 1416 FSPE_Motor7 "Bei gesetztem Bit ist mindestens ein Kundendienstfehler eingetragen

0x0 = kein KD_Fehler eingetragen
0x1 = KD_Fehler eingetragen
";
CM_ SG_ 1416 FStatus_Oeltemp_Motor "n.i.O. steht für Fehlerwert, außerhalb des Meßbereichs (ungenau), nicht verbaut oder noch kein aktueller Wert; Info aus Aufbereitung der TOG-Botschaft

0x0 = iO
0x1 = niO";
CM_ SG_ 1416 GLR_Motor "Dient der Vermeidung der vom Generator erzeugten, mechanischen Lastsprüngen und Leerlauf-schwankungen durch trägere Ausregelung. Diese Massnahme darf nur kurzfristig bzw. als Notlauf wirksam sein.";
CM_ SG_ 1416 Gluehkerzen_Brennr "Einschaltzustand der Gluehkerzenheizung in Prozent, Vorhaltung der Taktung zukuenftiger Keramik-Gluehkerzen

0xF = Fehler";
CM_ SG_ 1416 Hoeheninfo "Korrekturfaktor Höhe (1 entspricht 1013 mbar)

0xFF = Fehler";
CM_ SG_ 1416 Klemme_DFM "Meßwert Tastverhältnis DFM-Signal (Nicht Audi D3 / C6/ AU716)

0xFF = Fehler
";
CM_ SG_ 1416 Ladedruck "Zur Anzeige im Kombi, z.Zt. nur Porsche Colorado

0xFF = Fehler";
CM_ SG_ 1416 Lastabwurf "Anforderung eines Lastabwurfs (für Notlauf):
Stufe 0: Keine Reduktion der Generatorspannung
Stufe 1: Generatorspannung = 13,3V
Stufe 2: Generatorspannung = 12,6V
Stufe 3: Generatorspannung = 11,8V
Anmerkung: Stufe 3 nur für äußersten Notfall!
Schalt";
CM_ SG_ 1416 Lastabwurf_Heizsysteme "Lastabwurf der Hochleistungsheizsysteme, bspw. Abschaltung von Frontscheibenheizung, PTC-Heizung und Heckscheibenheizung nach Motorstart und im Notfall. Anmerkung: Der Lastabwurf der Hochleistungs-Heizsysteme wird auch bei reduzierter Generatorspannung du";
CM_ SG_ 1416 MDG "Differenz der Motordrehzahlen nt nt-20msec aus der CAN-Botschaft Motor 1. 0x7F ist >=127/min
";
CM_ SG_ 1416 Oeltemperatur "realer Meßbereich ca. -40..150 Grad; 0 für nicht verbaut; Info aus Aufbereitung der TOG-Botschaft

0xFF = Fehler
";
CM_ SG_ 1416 PTC_Gluehstifte_ausgeschaltet "Rückmeldung für das Lastmanagement, daß die PTC / Glühstifte ausgeschaltet wurden; z. Zt nur beim Diesel gefordert 

1xx = Stufe 1 ausgeschaltet
x1x = Stufe 2 ausgeschaltet
xx1 = Stufe 3 ausgeschaltet

";
CM_ SG_ 1416 RLS_Stufe1 "Rückmeldung Leerlaufsolldrehzahl für Lastmanagement - Erste Stufe
Leerlauf-Solldrehzahl wurde angehoben, weil BSG_Last, Byte 2, Bit 0 oder Energiemananager 1, Byte 1, Bit 0 gesetzt war oder eine Klimaanforderung vorlag

0x0 = keine Anforderung einer er";
CM_ SG_ 1416 RLS_Stufe2 "Rückmeldung Leerlaufsolldrehzahl für Lastmanagement - Zweite Stufe

Leerlauf-Solldrehzahl wurde aufgrund einer Lastmanagement-Anforderung (BSG_Last Byte 1, Bit 5 oder Energiemanager 1, Byte 1, Bit 1) auf die zweite Stufe angehoben.

0x0 = keine Anford";
CM_ SG_ 1416 SIB_Motor "Die Sleep-Bereitschaft wird nach Klemme 15 aus durch Setzen dieses Bits signalisiert

0x0 = CAN wird benötigt
0x1 = Sleep bereit
";
CM_ SG_ 1416 Signum_MDG "Positiv steht für steigende Drehzahl; Negativ für fallende Drehzahl

0x0 = MDG positiv
0x1 = MDG negativ
";
CM_ SG_ 1416 V_Begrenz_Aktiv "Motor begrenzt aktuell die Geschwindigkeit des Fahrzeugs; Reaktion auf externe oder interne Anforderung

0x0 = inaktiv
0x1 = aktiv
";
CM_ SG_ 1416 V_Begrenz_Aktivierbar "Fehlerbit wird vom Motor-SG gesetzt, wenn dieses nicht in dieGeschwindigkeits-begrenzung gehen kann, ein Fehler während der v-Begrenzung auftritt oder v > v_Begrenzung - v_Delta

0x0 = V-Begrenzung nicht möglich
0x1 = V-Begrenzung möglich
";
CM_ SG_ 1416 Zusaetzliche_Kuehlung "Zur Unterstützung der Motorkühlung fordert Motor von Klima oder Zusatzheizung die Schaltung des Heizwasserkreislauf-Bypasses an,
z.Zt nur im Colorado V10 TDI

0x0 = keine zusätzliche Kühlung notwendig
0x1 = zusätzliche Kühlung angefordert

";

CM_ SG_ 1162 Avus_Motorschutz "Warntextanzeigen zum Kombi für den Fall des AVUS-Notlauf. Priowarnung, kann parallel mit anderen Warnungen im Mittendisplay angezeigt werden.

0x0 = keine Warnung
0x1 = Drehzahlwarnung Stufe 1
0x2 = Drehzahlwarnung Stufe 2
0x3 = Drehzahlwarnung Stufe";
CM_ SG_ 1162 BZ_Motor8 "Freilaufender 4Bit-Botschaftszähler";
CM_ SG_ 1162 CHK_Motor8 "XOR über Summe aller Bytes siehe High-Speed-CAN-Lastenheft";
CM_ SG_ 1162 Enable_Oeldr_Motor "Schaltet die interne Öldruckauswertung im Kombiinstrument ab und aktiviert die Auswertung des Bits 'Oeldr_Warn_Motor'

0x0 = Öldruckauswertung Kombi
0x1 = Öldruckauswertung Motor";
CM_ SG_ 1162 GRA_Wunschgeschw "Wunschgeschwindigkeit GRA vom Motor an Kombi zur Anzeige im Mitteldisplay";
CM_ SG_ 1162 Oeldruck_Warn_Motor "Löst im Kombiinstrument die rote Prio1-Öldruckwarnung (inkl. 3xBeep) aus; die Warnauslösung erfolgt nur bei gleichzeitig gesetztem 'Enable_Oeldr_Motor'

0x0 = Lampe aus
0x1 = Lampe ein";
CM_ SG_ 1162 Optimierte_Anzeigedrehzahl "Optimierte Anzeigedrehzahl wegen sportlicherem Drehzahlmesser im Kombi. 

0xFFF = Fehler";

CM_ SG_ 1424 Absenkung_Fahrzeug "Nächstniedrigeres Niveau wird angefahren (Absenken). Dieses Bit wird immer gesetzt in Verbindung mit einer Auswahl aus den Bits 4..7.

0x0 = inaktiv
0x1 = aktiv
";
CM_ SG_ 1424 Anhebung_Fahrzeug "Nächsthöheres Niveau wird angefahren (Heben). Dieses Bit wird immer gesetzt in Verbindung mit einer Auswahl aus den Bits 4..7.

0x0 = inaktiv
0x1 = aktiv
";
CM_ SG_ 1424 ESP_Beeinflussung "Zwangsweise Aktivierung der ESP-Funktionalität wird angefordert auch bei Passivtastung

0x0 = keine ESP Beeinflussung
0x1 = ESP Zwangszuschaltung angefordert
";
CM_ SG_ 1424 Fahrzeugart_Niveau "Für automatische Fahrzeug-Erkennung zur Absicherung der Einschränkungen, Codierinformation bspw. für Motor. 

0x0 = beliebiges Fahrzeug
0x1 = Fahrzeug mit Niveauregelung, die v-Begrenzung anfordert";
CM_ SG_ 1424 Fehlerlampe_Niveau "Rote Warnlampe, wird im VW D1 bedient, nicht bei Audi D3, C6 und AU716

0x0 = Lampe aus
0x1 = Lampe ein";
CM_ SG_ 1424 FSPE_Niveau1 "Bei gesetztem Bit ist mindestens ein Kundendienstfehler eingetragen

0x0 = kein KD_Fehler eingetragen
0x1 = KD_Fehler eingetragen
";
CM_ SG_ 1424 Kompressorlauf_in_Kuerze "Kompressorlauf steht unmittelbar bevor bspw. Tasteneingabe. Das Bit wird immer gesetzt in Verbindung mit den Bits 2 oder 3.

0x0 = inaktiv
0x1 = aktiv
";
CM_ SG_ 1424 MSG_Einschraenkung "Eingriff im Motor-SG bspw. v-Begrenzung im Hochniveau nur im Colorado, wird mit dem AU716 auch bei Audi eingeführt

0x0 = keine Begrenzung
0x1 = Begrenzung angefordert
";
CM_ SG_ 1424 Niveaustati "Sollniveau, Tiefniveau 2 gilt als Beladungsniveau für Colorado (physikalisch zwischen TN 1 und Untertiefniveau)

0x0 = nicht definiert
0x1 = Untertiefniveau
0x2 = Tiefniveau 1
0x3 = Normalniveau
0x4 = Hochniveau 1
0x5 = Hochniveau 2
0x6 = Überhoch";
CM_ SG_ 1424 Parkniveau "Fahrzeug befindet sich im PN. Das PN ist keine weitere Fahrzeughöhe, sondern eines aus den vor genannten. Wird im Projekt Audi C6 nicht bedient.

0x0 = inaktiv
0x1 = aktiv
";
CM_ SG_ 1424 Systemstatus "Bit wird gesetzt, wenn interne Funktionsprüfung i.O. und System generell funktionsfähig ist.

0x0 = nicht funktionsfähig
0x1 = funktionsfähig";
CM_ SG_ 1424 Taster_Niveau "Nach Betätigung des Tasters wird das Fahrwerk-Menü im ZAB (D1) aktiviert. Das Bit wird nur solange gesetzt, wie der Taster gedrückt ist. Wird in den Projekten Audi D3 und C6 nicht bedient.

0x0 = Taster nicht betätigt
0x1 = Taster betätigt
";
CM_ SG_ 1424 Textbits_Niveau "Die Textbits werden verwendet, um im Kombi Texte oder Bilder für die Niveauregulierung/Luftfederung darzustellen. Bei Audi nicht bedient.";
CM_ SG_ 1424 Verstellung_aktiv "Verstellung ist aktiv. Das Bit wird immer gesetzt in Verbindung mit den Bits 2 oder 3.

0x0 = inaktiv
0x1 = aktiv
";
CM_ SG_ 1424 Verstellung_HL "Fahrzeug wird hinten links verstellt. Dieses Bit kann zusammen mit dem Bit 6 erscheinen, dann erfolgt ein Anheben oder Absenken achsweise (hinten).

0x0 = inaktiv
0x1 = aktiv
";
CM_ SG_ 1424 Verstellung_HR "Fahrzeug wird hinten rechts verstellt. Dieses Bit kann zusammen mit dem Bit 7 erscheinen, dann erfolgt ein Anheben oder Absenken Achsweise (hinten).

0x0 = inaktiv
0x1 = aktiv";
CM_ SG_ 1424 Verstellung_in_Kuerze "Dieses Bit wird gesetzt, wenn eine Verstellung unmittelbar bevorsteht (Nutzer: Leuchtweitenregulierung).

0x0 = keine Verstellung
0x1 = Verstellung erwartet";
CM_ SG_ 1424 Verstellung_VL "Fahrzeug wird vorn links verstellt. Dieses Bit kann zusammen mit dem Bit 4 erscheinen, dann erfolgt ein Anheben oder Absenken achsweise (vorn).

0x0 = inaktiv
0x1 = aktiv
";
CM_ SG_ 1424 Verstellung_VR "Fahrzeug wird vorn rechts verstellt. Dieses Bit kann zusammen mit dem Bit 5 erscheinen, dann erfolgt ein Anheben oder Absenken achsweise (vorn).

0x0 = inaktiv
0x1 = aktiv
";
CM_ SG_ 1424 Warnlampe "Bit wird gesetzt, wenn während des Betriebes ein Fehler erkannt wird. Niveauregulierungs-Warnlampe im Kombi wird dauerleuchtend oder blinkend (alternierend mit 1Hz an und aus) eingeschaltet. Gelbe Warnlampe im Audi D3, C6

0x0 = Warnlampe aus
0x1 = War";
CM_ SG_ 1424 Zwischenniveau "Dieses Bit wird gesetzt, wenn die Fahrzeughöhe zwischen 2 definierten Niveaus liegt bspw. während des Regelvorgangs.

0x0 = kein Zwischenniveau
0x1 = Zwischenniveau";

CM_ SG_ 1428 Hoehenwert_HL "Aktueller Höhenwert Hinten Links

0xFE = nicht initialisiert
0xFF = Fehler";
CM_ SG_ 1428 Hoehenwert_HR "Aktueller Höhenwert Hinten Rechts

0xFE = nicht initialisiert
0xFF = Fehler";
CM_ SG_ 1428 Hoehenwert_VL "Aktueller Höhenwert Vorne Links

0xFE = nicht initialisiert
0xFF = Fehler";
CM_ SG_ 1428 Hoehenwert_VR "Aktueller Höhenwert Vorne Rechts

0xFE = nicht initialisiert
0xFF = Fehler";

CM_ SG_ 1434 Anzeigebit10 "Anzeige = 'Fahrzeug senkt ab' in Verbindung mit aktivem Niveau; Abregelung = für Gesamtdauer des Regelvorgangs gesetzt

0x0 = keine Anzeige
0x1 = Anzeige 'Fahrzeug senkt ab'";
CM_ SG_ 1434 Anzeigebit17 "Anzeige Istniveau Hochniveau 2

0x0 = Grafikblock aus
0x1 = Grafikblock ein";
CM_ SG_ 1434 Anzeigebit18 "Marker Sollniveau Hochniveau 2

0x0 = Marker aus
0x1 = Marker ein";
CM_ SG_ 1434 Anzeigebit19 "Anzeige Istniveau Hochniveau 1

0x0 = Grafikblock aus
0x1 = Grafikblock ein";
CM_ SG_ 1434 Anzeigebit20 "Marker Sollniveau Hochniveau 1

0x0 = Marker aus
0x1 = Marker ein";
CM_ SG_ 1434 Anzeigebit21 "Anzeige Istniveau Normalniveau

0x0 = Grafikblock aus
0x1 = Grafikblock ein";
CM_ SG_ 1434 Anzeigebit22 "Marker Sollniveau Normalniveau

0x0 = Marker aus
0x1 = Marker ein";
CM_ SG_ 1434 Anzeigebit23 "Anzeige Istniveau Tiefniveau 1

0x0 = Grafikblock aus
0x1 = Grafikblock ein";
CM_ SG_ 1434 Anzeigebit24 "Marker Sollniveau Tiefniveau 1

0x0 = Marker aus
0x1 = Marker ein";
CM_ SG_ 1434 Anzeigebit25 "Anzeige Istniveau Tiefniveau 2

0x0 = Grafikblock aus
0x1 = Grafikblock ein";
CM_ SG_ 1434 Anzeigebit26 "Marker Sollniveau Tiefniveau 2

0x0 = Marker aus
0x1 = Marker ein";
CM_ SG_ 1434 Anzeigebit9 "Anzeige = 'Fahrzeug hebt an' in Verbindung mit aktivem Niveau; Aufregelung = für Gesamtdauer des Regelvorgangs gesetzt

0x0 = keine Anzeige
0x1 = Anzeige 'Fahrzeug hebt an'";
CM_ SG_ 1434 Priorisierung_FIS "FIS-Menü Luftfeder im Kombi auf oberste Ebene bringen

0x0 = inaktiv
0x1 = FIS oberste Ebene";
CM_ SG_ 1434 Textbit1 "AU716: Ausgabe Text 'LIMIT 40 km/h aktiviertt'

0x0 = kein Text
0x1 = 'LIMIT 40 km/h aktiviertt'
";
CM_ SG_ 1434 Textbit2 "AU716: Ausgabe Text 'Achtung! LIMIT 40 km/h erreicht'

0x0 = kein Text
0x1 = 'Achtung! LIMIT 40 km/h erreicht'
";
CM_ SG_ 1434 Textbit3 "AU716: Ausgabe Text 'Reifenbefüllung aktiviert'

0x0 = kein Text
0x1 = 'Reifenbefüllung aktiviert'
";
CM_ SG_ 1434 Textbit4 "AU716: Ausgabe Text 'Beladungsniveau nicht möglich'

0x0 = kein Text
0x1 = 'Beladungsniveau nicht möglich'
";
CM_ SG_ 1434 Verfuegbarkeit_FIS "FIS-Menü Luftfeder im Kombi abrufbar schalten

0x0 = nicht verfügbar
0x1 = FIS verfügbar";

CM_ SG_ 2004 Aenderung_Innerorts "Das Signal gibt an ab welchem Segment sich der Status Innerorts ändert. (Innerorts kann sich nur an Segmentgrenzen ändern.) Die Entfernung bis Innerorts/Ausserorts kann durch addieren der  Segmentlängen bis zur Änderung berechnet werden.

0x0 = keine Ve";
CM_ SG_ 2004 Aenderung_Unterfuehrung "Das Signal gibt an ab welchem Segment sich der Status Innerorts ändert. (Innerorts kann sich nur an Segmentgrenzen ändern.) Die Entfernung bis Unterführung/Keine Unterführung kann durch addieren der  Segmentlängen bis zur Änderung berechnet werden.

0x0";
CM_ SG_ 2004 Alter_der_Daten "Navi trägt beim Senden des 1. Paketes hier die Zeitdifferenz ein, die seit dem Berechnen der PSD-Daten vergangen ist. 

0x1F = Daten veraltet";
CM_ SG_ 2004 Bes_Geschw_klasse_1 "Die Art der Besonderen Geschwindigkeits-beschänkung für dieses Segment ist im Signal 'Typ der besonderen Geschwindigkeitsklasse' definiert.

0x0 = normale Geschwindigkeitsklasse
0x1 = besondere Geschwindigkeitsklasse";
CM_ SG_ 2004 Bes_Geschw_klasse_2 "Die Art der Besonderen Geschwindigkeits-beschänkung für dieses Segment ist im Signal 'Typ der besonderen Geschwindigkeitsklasse' definiert.

0x0 = normale Geschwindigkeitsklasse
0x1 = besondere Geschwindigkeitsklasse";
CM_ SG_ 2004 Bes_Geschw_klasse_3 "Die Art der Besonderen Geschwindigkeits-beschänkung für dieses Segment ist im Signal 'Typ der besonderen Geschwindigkeitsklasse' definiert.

0x0 = normale Geschwindigkeitsklasse
0x1 = besondere Geschwindigkeitsklasse";
CM_ SG_ 2004 Bes_Geschw_klasse_4 "Die Art der Besonderen Geschwindigkeits-beschänkung für dieses Segment ist im Signal 'Typ der besonderen Geschwindigkeitsklasse' definiert.

0x0 = normale Geschwindigkeitsklasse
0x1 = besondere Geschwindigkeitsklasse";
CM_ SG_ 2004 Bes_Geschw_klasse_5 "Die Art der Besonderen Geschwindigkeits-beschänkung für dieses Segment ist im Signal 'Typ der besonderen Geschwindigkeitsklasse' definiert.

0x0 = normale Geschwindigkeitsklasse
0x1 = besondere Geschwindigkeitsklasse";
CM_ SG_ 2004 Bes_Geschw_klasse_6 "Die Art der Besonderen Geschwindigkeits-beschänkung für dieses Segment ist im Signal 'Typ der besonderen Geschwindigkeitsklasse' definiert.

0x0 = normale Geschwindigkeitsklasse
0x1 = besondere Geschwindigkeitsklasse";
CM_ SG_ 2004 Digitalisierung "0x0 = Teildigitalisiert
0x1 = Volldigitalisiert";
CM_ SG_ 2004 Einbahnstrasse "Standort bezogen, wird bspw. auch bei Autobahnen gesetzt.

0x0 = keine Einbahnstraße
0x1 = Einbahnstraße";
CM_ SG_ 2004 Einheit_Geschw_klasse "0x0 = km/h
0x1 = mph";
CM_ SG_ 2004 Endkruemmung_1 "Achtung: besondere Umrechungsformel (nicht darstellbar in DBC-Format)

physikalischer Wert = inv( 1+0.155xHexWert²)  [1/m]

0xFF = Krümmung 0
";
CM_ SG_ 2004 Endkruemmung_2 "Achtung: besondere Umrechungsformel (nicht darstellbar in DBC-Format)

physikalischer Wert = inv( 1+0.155xHexWert²)  [1/m]

0xFF = Krümmung 0
";
CM_ SG_ 2004 Endkruemmung_3 "Achtung: besondere Umrechungsformel (nicht darstellbar in DBC-Format)

physikalischer Wert = inv( 1+0.155xHexWert²)  [1/m]

0xFF = Krümmung 0

";
CM_ SG_ 2004 Endkruemmung_4 "Achtung: besondere Umrechungsformel (nicht darstellbar in DBC-Format)

physikalischer Wert = inv( 1+0.155xHexWert²)  [1/m]

0xFF = Krümmung 0
";
CM_ SG_ 2004 Endkruemmung_5 "Achtung: besondere Umrechungsformel (nicht darstellbar in DBC-Format)

physikalischer Wert = inv( 1+0.155xHexWert²)  [1/m]

0xFF = Krümmung 0
";
CM_ SG_ 2004 Endkruemmung_6 "Achtung: besondere Umrechungsformel (nicht darstellbar in DBC-Format)

physikalischer Wert = inv( 1+0.155xHexWert²)  [1/m]

0xFF = Krümmung 0
";
CM_ SG_ 2004 Fahrspuren_in_Fahrtrichtung "Keine Fahrspur bedeutet bspw. falsch in der Einbahnstraße.

0x0 = keine Fahrspur
0x1 ... 0x7 = Anzahl der Fahrspuren";
CM_ SG_ 2004 Geschwindigkeitsklasse_1 "Das Signal ist abhängig von 'Einheit der Geschwindigkeitsklasse'und 'Qualität' (beide in Paket 1)

";
CM_ SG_ 2004 Geschwindigkeitsklasse_3 "Das Signal ist abhängig von 'Einheit der Geschwindigkeitsklasse'und 'Qualität' (beide in Paket 1)";
CM_ SG_ 2004 Geschwindigkeitsklasse_5 "Das Signal ist abhängig von 'Einheit der Geschwindigkeitsklasse'und 'Qualität' (beide in Paket 1)";
CM_ SG_ 2004 Kreuzung "Das Signal gibt an, nach welcher Segmentgrenze sich eine Kreuzung befindet. (Kreuzungen befinden sich nur an Segmentgrenzen.) Die Entfernung bis zur Kreuzung kann durch addieren der  Segmentlängen bis zum Kreuzungspunkt berechnet werden.

0x0 = keine Kr";
CM_ SG_ 2004 Laengsfehler "0x0 = keine Prädiktion(Offroad)
0x1 = <5m
0x2 = <10m
0x3 = <20m
0x4 = <50m
0x5 = >50m
0x6 = nicht erlaubt
0x7 = nicht erlaubt
";
CM_ SG_ 2004 Mux_Code_PSD "Multiplexer für die einzelnen Segmente, definiert die Paketnummer

0x0 = Paket 1
0x1 = Paket 2
0x2 = Paket 3
0x3 = Botschaft verwerfen

0x3 wird bei Naviüberlastung gesendet, Inhalt ist nicht zu verwenden";
CM_ SG_ 2004 Segmentlaenge_1 "0x0 = Segment nicht vorhanden";
CM_ SG_ 2004 Segmentlaenge_2 "0x0 = Segment nicht vorhanden";
CM_ SG_ 2004 Segmentlaenge_3 "0x0 = Segment nicht vorhanden";
CM_ SG_ 2004 Segmentlaenge_4 "0x0 = Segment nicht vorhanden";
CM_ SG_ 2004 Segmentlaenge_6 "0x0 = Segment nicht vorhanden";
CM_ SG_ 2004 Signum_Endkruemmung_1 "0x0 = Krümmung positiv
0x1 = Krümmung negativ";
CM_ SG_ 2004 Signum_Endkruemmung_2 "0x0 = Krümmung positiv
0x1 = Krümmung negativ";
CM_ SG_ 2004 Signum_Endkruemmung_3 "0x0 = Krümmung positiv
0x1 = Krümmung negativ";
CM_ SG_ 2004 Signum_Endkruemmung_4 "0x0 = Krümmung positiv
0x1 = Krümmung negativ";
CM_ SG_ 2004 Signum_Endkruemmung_5 "0x0 = Krümmung positiv
0x1 = Krümmung negativ";
CM_ SG_ 2004 Signum_Endkruemmung_6 "0x0 = Krümmung positiv
0x1 = Krümmung negativ";
CM_ SG_ 2004 Signum_Startkruemmung_1 "0x0 = Krümmung positiv
0x1 = Krümmung negativ";
CM_ SG_ 2004 Standort "0x0 = Mehrdeutiger Standort
0x1 = Eindeutiger Standort
0x2 = Route
0x3 = nicht erlaubt
";
CM_ SG_ 2004 Status_Innerorts "Das Signal bezieht sich auf den aktuellen Standort.

0x0 = Ausserorts
0x1 = Innerorts";
CM_ SG_ 2004 Status_Unterfuehrung "Das Signal bezieht sich auf den aktuellen Standort.

0x0 = keine Unterführung
0x1 = Unterführung";
CM_ SG_ 2004 Strassenklasse_1 "0x0 = Dorfstrasse (Rest)
0x1 = Bundes-,Landstrasse
0x2 = Autobahn
0x3 = Auf- oder Abfahrt, Rampe
";
CM_ SG_ 2004 Strassenklasse_2 "0x0 = Dorfstrasse (Rest)
0x1 = Bundes-,Landstrasse
0x2 = Autobahn
0x3 = Auf- oder Abfahrt, Rampe";
CM_ SG_ 2004 Strassenklasse_3 "0x0 = Dorfstrasse (Rest)
0x1 = Bundes-,Landstrasse
0x2 = Autobahn
0x3 = Auf- oder Abfahrt, Rampe";
CM_ SG_ 2004 Strassenklasse_4 "0x0 = Dorfstrasse (Rest)
0x1 = Bundes-,Landstrasse
0x2 = Autobahn
0x3 = Auf- oder Abfahrt, Rampe";
CM_ SG_ 2004 Strassenklasse_5 "0x0 = Dorfstrasse (Rest)
0x1 = Bundes-,Landstrasse
0x2 = Autobahn
0x3 = Auf- oder Abfahrt, Rampe";
CM_ SG_ 2004 Strassenklasse_6 "0x0 = Dorfstrasse (Rest)
0x1 = Bundes-,Landstrasse
0x2 = Autobahn
0x3 = Auf- oder Abfahrt, Rampe";
CM_ SG_ 2004 Typ_besond_Geschw_klasse "*n bedeutet, daß hier nicht zwingend die Geschwindigkeit eingehalten werden muß, Navi gibt in diesen Fällen die *normale Geschwindigkeitsklasse aus.

*s bedeutet, daß die Geschwindigkeitsklasse wegen der *speziellen Situation einen niedrigeren Wert als ";
CM_ SG_ 2004 Verkehrsrichtung "0x0 = Rechtsverkehr
0x1 = Linksverkehr";

CM_ SG_ 1306 BZ_TOG "Freilaufender 2Bit-Botschaftszähler";
CM_ SG_ 1306 Fuellstandszeit_1 "Füllstand im ersten Zeitfenster

0x0 = kein Wert
0x7FF = ungültiger Wert oder Bereichsüberlauf";
CM_ SG_ 1306 Fuellstandszeit_2 "Füllstand im zweiten Zeitfenster

0x0 = kein Wert
0x7FF = ungültiger Wert oder Bereichsüberlauf";
CM_ SG_ 1306 Fuellstandszeit_3 "Füllstand im dritten Zeitfenster

0x0 = kein Wert
0x7FF = ungültiger Wert oder Bereichsüberlauf";
CM_ SG_ 1306 Fuellstandszeit_4 "Füllstand im vierten Zeitfenster

0x0 = kein Wert
0x7FF = ungültiger Wert oder Bereichsüberlauf";
CM_ SG_ 1306 Oelfuellstand_max "Maximum-Ölfüllstand überschritten. Nur für WIV 3.1 im Audi C6

0x0 = Schwelle nicht überschritten
0x1 = Schwelle überschritten";
CM_ SG_ 1306 Oelfuellstand_max_pO "Maximum-Ölfüllstand plus Offset überschritten. Nur für WIV 3.1 im Audi C6

0x0 = Schwelle nicht überschritten
0x1 = Schwelle überschritten
";
CM_ SG_ 1306 Oeltemperaturzeit "Öltemperaturzeit aus maximal 4 Zeitfenstern

0x0 = kein Wert
0x3FF = Bereichsüberlauf";
CM_ SG_ 1306 Oelwarnschwelle "Nur für WIV 3.1 im Audi C6

0x0 = Schwelle nicht überschritten
0x1 = Schwelle überschritten

";
CM_ SG_ 1306 Oelwarnschwelle_pOue "Ölwarnschwelle plus Offset überschritten (s. TOG1, Byte 8, Bit 1)

0x0 = nein
0x1 = ja

";
CM_ SG_ 1306 Sensorfehler "Fehler kann Kurzschluß nach Plus, Masse oder Unterbrechung sein

0x0 = Sensor iO
0x1 = Fehler";

CM_ SG_ 1394 CHK_ZAS "XOR über Summe aller Bytes
siehe High-Speed-CAN-Lastenheft";
CM_ SG_ 1394 ZA1_ZAS_Kl_15SV "Bei Audi: Zustand der Klemme 15 CAN";
CM_ SG_ 1394 Zaehler_ZAS "Umlaufender Botschaftszaehler";
BA_DEF_ BO_  "GenMsgAutoGenDsp" ENUM "No", "Yes";
BA_DEF_ BO_  "GenMsgAutoGenSnd" ENUM "No", "Yes";
BA_DEF_ BO_  "GenMsgCycleTime" INT 0 65535;
BA_DEF_ BO_  "GenMsgCycleTimeFast" INT 0 65535;
BA_DEF_ BO_  "GenMsgDelayTime" INT 0 100000;
BA_DEF_ BO_  "GenMsgILSupport" ENUM "No", "Yes";
BA_DEF_ BO_  "GenMsgSendType" ENUM "cyclicX", "spontanX", "cyclicIfActiveX", "spontanWithDelay", "cyclicAndSpontanX", "cyclicAndSpontanWithDelay", "spontanWithRepetition", "cyclicIfActiveAndSpontanWD", "cyclicIfActiveFast", "cyclicWithRepeatOnDemand";
BA_DEF_ BO_  "GenMsgStartDelayTime" INT 0 100000;
BA_DEF_ BO_  "NmMessage" ENUM "No", "Yes";
BA_DEF_ BO_  "NWM-Botschaft" ENUM "No", "Yes";
BA_DEF_ BO_  "VAGTP20_API" HEX 0 255;
BA_DEF_ BO_  "VAGTP20_DynConnection" ENUM "No", "Yes";
BA_DEF_ BO_  "VAGTP20_DynSetup" ENUM "No", "Yes";
BA_DEF_ BO_  "VAGTP20_StatConnection" ENUM "No", "Yes";
BA_DEF_ SG_  "GenSigAltSetting" STRING;
BA_DEF_ SG_  "GenSigAssignSetting" STRING;
BA_DEF_ SG_  "GenSigAutoGenDsp" ENUM "No", "Yes";
BA_DEF_ SG_  "GenSigAutoGenSnd" ENUM "No", "Yes";
BA_DEF_ SG_  "GenSigConditionalSend" STRING;
BA_DEF_ SG_  "GenSigEnvVarType" ENUM "int", "float", "undef";
BA_DEF_ SG_  "GenSigEVName" STRING;
BA_DEF_ SG_  "GenSigInactiveValue" INT -2147483648 2147483647;
BA_DEF_ SG_  "GenSigPostIfSetting" STRING;
BA_DEF_ SG_  "GenSigPostSetting" STRING;
BA_DEF_ SG_  "GenSigPreIfSetting" STRING;
BA_DEF_ SG_  "GenSigPreSetting" STRING;
BA_DEF_ SG_  "GenSigSendType" ENUM "Cyclic", "OnWrite", "OnWriteWithRepetition", "OnChange", "OnChangeWithRepetition", "IfActive", "IfActiveWithRepetition", "NoSigSendType";
BA_DEF_ SG_  "GenSigStartValue" INT -2147483648 2147483647;
BA_DEF_ SG_  "NWM-WakeupAllowed" ENUM "No", "Yes";
BA_DEF_ SG_  "GenSigTimeoutMsg_ESP8_C6" HEX 0 2047;
BA_DEF_ SG_  "GenSigTimeoutMsg_DME_EDC16CP3000" HEX 0 2047;
BA_DEF_ SG_  "GenSigTimeoutMsg_DME_ME7_MED9_C6" HEX 0 2047;
BA_DEF_ SG_  "GenSigTimeoutMsg_DME_SIMOS6_C6" HEX 0 2047;
BA_DEF_ SG_  "GenSigTimeoutMsg__6HP_C6" HEX 0 2047;
BA_DEF_ SG_  "GenSigTimeoutMsg_Gateway_C6" HEX 0 2047;
BA_DEF_ SG_  "GenSigTimeoutMsg_EPB_C6" HEX 0 2047;
BA_DEF_ SG_  "GenSigTimeoutMsg__4CL_C6" HEX 0 2047;
BA_DEF_ SG_  "GenSigTimeoutMsg_Airbag_C6" HEX 0 2047;
BA_DEF_ SG_  "GenSigTimeoutMsg_LWR_AFS_C6" HEX 0 2047;
BA_DEF_ SG_  "GenSigTimeoutMsg_LWS_C6" HEX 0 2047;
BA_DEF_ SG_  "GenSigTimeoutMsg_CVT_C6" HEX 0 2047;
BA_DEF_ SG_  "GenSigTimeoutMsg_DME_Slave" HEX 0 2047;
BA_DEF_DEF_  "GenMsgAutoGenDsp" "Yes";
BA_DEF_DEF_  "GenMsgAutoGenSnd" "Yes";
BA_DEF_DEF_  "GenMsgCycleTime" 0;
BA_DEF_DEF_  "GenMsgCycleTimeFast" 0;
BA_DEF_DEF_  "GenMsgDelayTime" 0;
BA_DEF_DEF_  "GenMsgILSupport" "";
BA_DEF_DEF_  "GenMsgSendType" "cyclicX";
BA_DEF_DEF_  "GenMsgStartDelayTime" 0;
BA_DEF_DEF_  "NmMessage" "No";
BA_DEF_DEF_  "NWM-Botschaft" "No";
BA_DEF_DEF_  "VAGTP20_API" 0;
BA_DEF_DEF_  "VAGTP20_DynConnection" "No";
BA_DEF_DEF_  "VAGTP20_DynSetup" "No";
BA_DEF_DEF_  "VAGTP20_StatConnection" "No";
BA_DEF_DEF_  "GenSigAltSetting" "";
BA_DEF_DEF_  "GenSigAssignSetting" "";
BA_DEF_DEF_  "GenSigAutoGenDsp" "";
BA_DEF_DEF_  "GenSigAutoGenSnd" "";
BA_DEF_DEF_  "GenSigConditionalSend" "";
BA_DEF_DEF_  "GenSigEnvVarType" "undef";
BA_DEF_DEF_  "GenSigEVName" "";
BA_DEF_DEF_  "GenSigInactiveValue" 0;
BA_DEF_DEF_  "GenSigPostIfSetting" "";
BA_DEF_DEF_  "GenSigPostSetting" "";
BA_DEF_DEF_  "GenSigPreIfSetting" "";
BA_DEF_DEF_  "GenSigPreSetting" "";
BA_DEF_DEF_  "GenSigSendType" "Cyclic";
BA_DEF_DEF_  "GenSigStartValue" 0;
BA_DEF_DEF_  "NWM-WakeupAllowed" "";
BA_DEF_DEF_  "GenSigTimeoutMsg_ESP8_C6" 0;
BA_DEF_DEF_  "GenSigTimeoutMsg_DME_EDC16CP3000" 0;
BA_DEF_DEF_  "GenSigTimeoutMsg_DME_ME7_MED9_C6" 0;
BA_DEF_DEF_  "GenSigTimeoutMsg_DME_SIMOS6_C6" 0;
BA_DEF_DEF_  "GenSigTimeoutMsg__6HP_C6" 0;
BA_DEF_DEF_  "GenSigTimeoutMsg_Gateway_C6" 0;
BA_DEF_DEF_  "GenSigTimeoutMsg_EPB_C6" 0;
BA_DEF_DEF_  "GenSigTimeoutMsg__4CL_C6" 0;
BA_DEF_DEF_  "GenSigTimeoutMsg_Airbag_C6" 0;
BA_DEF_DEF_  "GenSigTimeoutMsg_LWR_AFS_C6" 0;
BA_DEF_DEF_  "GenSigTimeoutMsg_LWS_C6" 0;
BA_DEF_DEF_  "GenSigTimeoutMsg_CVT_C6" 0;
BA_DEF_DEF_  "GenSigTimeoutMsg_DME_Slave" 0;
BA_ "GenMsgAutoGenSnd" BO_ 1160 0;
BA_ "GenMsgCycleTime" BO_ 1160 20;
BA_ "GenMsgCycleTimeFast" BO_ 1160 10;
BA_ "GenMsgILSupport" BO_ 1160 0;
BA_ "GenMsgAutoGenSnd" BO_ 1416 0;
BA_ "GenMsgCycleTime" BO_ 1416 20;
BA_ "GenMsgILSupport" BO_ 1416 0;
BA_ "GenMsgCycleTime" BO_ 1162 20;
BA_ "GenMsgILSupport" BO_ 1162 0;
BA_ "GenMsgAutoGenSnd" BO_ 1408 0;
BA_ "GenMsgCycleTime" BO_ 1408 1000;
BA_ "GenMsgILSupport" BO_ 1408 0;
BA_ "GenMsgAutoGenSnd" BO_ 1823 0;
BA_ "GenMsgCycleTime" BO_ 1823 100;
BA_ "GenMsgILSupport" BO_ 1823 0;
BA_ "GenMsgAutoGenSnd" BO_ 1424 0;
BA_ "GenMsgCycleTime" BO_ 1424 48;
BA_ "GenMsgILSupport" BO_ 1424 0;
BA_ "GenMsgAutoGenSnd" BO_ 1428 0;
BA_ "GenMsgCycleTime" BO_ 1428 24;
BA_ "GenMsgILSupport" BO_ 1428 0;
BA_ "GenMsgCycleTime" BO_ 1434 48;
BA_ "GenMsgILSupport" BO_ 1434 0;
BA_ "GenMsgAutoGenSnd" BO_ 2004 0;
BA_ "GenMsgCycleTime" BO_ 2004 150;
BA_ "GenMsgILSupport" BO_ 2004 0;
BA_ "GenMsgAutoGenSnd" BO_ 1306 0;
BA_ "GenMsgCycleTime" BO_ 1306 500;
BA_ "GenMsgILSupport" BO_ 1306 0;
BA_ "GenMsgAutoGenSnd" BO_ 1936 0;
BA_ "GenMsgCycleTime" BO_ 1936 1;
BA_ "GenMsgILSupport" BO_ 1936 0;
BA_ "GenMsgSendType" BO_ 1936 2;
BA_ "VAGTP20_DynConnection" BO_ 1936 1;
BA_ "GenMsgAutoGenSnd" BO_ 1937 0;
BA_ "GenMsgCycleTime" BO_ 1937 1;
BA_ "GenMsgILSupport" BO_ 1937 0;
BA_ "GenMsgSendType" BO_ 1937 2;
BA_ "VAGTP20_DynConnection" BO_ 1937 1;
BA_ "GenMsgAutoGenSnd" BO_ 1904 0;
BA_ "GenMsgCycleTime" BO_ 1904 1;
BA_ "GenMsgILSupport" BO_ 1904 0;
BA_ "GenMsgSendType" BO_ 1904 2;
BA_ "VAGTP20_DynConnection" BO_ 1904 1;
BA_ "GenMsgAutoGenSnd" BO_ 1905 0;
BA_ "GenMsgCycleTime" BO_ 1905 1;
BA_ "GenMsgILSupport" BO_ 1905 0;
BA_ "GenMsgSendType" BO_ 1905 2;
BA_ "VAGTP20_DynConnection" BO_ 1905 1;
BA_ "GenMsgAutoGenSnd" BO_ 1896 0;
BA_ "GenMsgCycleTime" BO_ 1896 1;
BA_ "GenMsgILSupport" BO_ 1896 0;
BA_ "GenMsgSendType" BO_ 1896 2;
BA_ "VAGTP20_DynConnection" BO_ 1896 1;
BA_ "GenMsgAutoGenSnd" BO_ 1897 0;
BA_ "GenMsgCycleTime" BO_ 1897 1;
BA_ "GenMsgILSupport" BO_ 1897 0;
BA_ "GenMsgSendType" BO_ 1897 2;
BA_ "VAGTP20_DynConnection" BO_ 1897 1;
BA_ "GenMsgAutoGenSnd" BO_ 822 0;
BA_ "GenMsgCycleTime" BO_ 822 1;
BA_ "GenMsgILSupport" BO_ 822 0;
BA_ "GenMsgSendType" BO_ 822 2;
BA_ "VAGTP20_DynConnection" BO_ 822 1;
BA_ "GenMsgAutoGenSnd" BO_ 823 0;
BA_ "GenMsgCycleTime" BO_ 823 1;
BA_ "GenMsgILSupport" BO_ 823 0;
BA_ "GenMsgSendType" BO_ 823 2;
BA_ "VAGTP20_DynConnection" BO_ 823 1;
BA_ "GenMsgAutoGenSnd" BO_ 812 0;
BA_ "GenMsgCycleTime" BO_ 812 1;
BA_ "GenMsgILSupport" BO_ 812 0;
BA_ "GenMsgSendType" BO_ 812 2;
BA_ "VAGTP20_DynConnection" BO_ 812 1;
BA_ "GenMsgAutoGenSnd" BO_ 813 0;
BA_ "GenMsgCycleTime" BO_ 813 1;
BA_ "GenMsgILSupport" BO_ 813 0;
BA_ "GenMsgSendType" BO_ 813 2;
BA_ "VAGTP20_DynConnection" BO_ 813 1;
BA_ "GenMsgAutoGenSnd" BO_ 1232 0;
BA_ "GenMsgCycleTime" BO_ 1232 1;
BA_ "GenMsgILSupport" BO_ 1232 0;
BA_ "GenMsgSendType" BO_ 1232 2;
BA_ "VAGTP20_DynConnection" BO_ 1232 1;
BA_ "GenMsgAutoGenSnd" BO_ 1233 0;
BA_ "GenMsgCycleTime" BO_ 1233 1;
BA_ "GenMsgILSupport" BO_ 1233 0;
BA_ "GenMsgSendType" BO_ 1233 2;
BA_ "VAGTP20_DynConnection" BO_ 1233 1;
BA_ "GenMsgAutoGenSnd" BO_ 1234 0;
BA_ "GenMsgCycleTime" BO_ 1234 1;
BA_ "GenMsgILSupport" BO_ 1234 0;
BA_ "GenMsgSendType" BO_ 1234 2;
BA_ "VAGTP20_DynConnection" BO_ 1234 1;
BA_ "GenMsgAutoGenSnd" BO_ 1235 0;
BA_ "GenMsgCycleTime" BO_ 1235 1;
BA_ "GenMsgILSupport" BO_ 1235 0;
BA_ "GenMsgSendType" BO_ 1235 2;
BA_ "VAGTP20_DynConnection" BO_ 1235 1;
BA_ "GenMsgAutoGenSnd" BO_ 1924 0;
BA_ "GenMsgCycleTime" BO_ 1924 1;
BA_ "GenMsgILSupport" BO_ 1924 0;
BA_ "GenMsgSendType" BO_ 1924 2;
BA_ "VAGTP20_DynConnection" BO_ 1924 1;
BA_ "GenMsgAutoGenSnd" BO_ 1925 0;
BA_ "GenMsgCycleTime" BO_ 1925 1;
BA_ "GenMsgILSupport" BO_ 1925 0;
BA_ "GenMsgSendType" BO_ 1925 2;
BA_ "VAGTP20_DynConnection" BO_ 1925 1;
BA_ "GenMsgAutoGenSnd" BO_ 818 0;
BA_ "GenMsgCycleTime" BO_ 818 1;
BA_ "GenMsgILSupport" BO_ 818 0;
BA_ "GenMsgSendType" BO_ 818 2;
BA_ "VAGTP20_DynConnection" BO_ 818 1;
BA_ "GenMsgAutoGenSnd" BO_ 819 0;
BA_ "GenMsgCycleTime" BO_ 819 1;
BA_ "GenMsgILSupport" BO_ 819 0;
BA_ "GenMsgSendType" BO_ 819 2;
BA_ "VAGTP20_DynConnection" BO_ 819 1;
BA_ "GenMsgAutoGenSnd" BO_ 1940 0;
BA_ "GenMsgCycleTime" BO_ 1940 1;
BA_ "GenMsgILSupport" BO_ 1940 0;
BA_ "GenMsgSendType" BO_ 1940 2;
BA_ "VAGTP20_DynConnection" BO_ 1940 1;
BA_ "GenMsgAutoGenSnd" BO_ 1941 0;
BA_ "GenMsgCycleTime" BO_ 1941 1;
BA_ "GenMsgILSupport" BO_ 1941 0;
BA_ "GenMsgSendType" BO_ 1941 2;
BA_ "VAGTP20_DynConnection" BO_ 1941 1;
BA_ "GenMsgAutoGenSnd" BO_ 816 0;
BA_ "GenMsgCycleTime" BO_ 816 1;
BA_ "GenMsgILSupport" BO_ 816 0;
BA_ "GenMsgSendType" BO_ 816 2;
BA_ "VAGTP20_DynConnection" BO_ 816 1;
BA_ "GenMsgAutoGenSnd" BO_ 817 0;
BA_ "GenMsgCycleTime" BO_ 817 1;
BA_ "GenMsgILSupport" BO_ 817 0;
BA_ "GenMsgSendType" BO_ 817 2;
BA_ "VAGTP20_DynConnection" BO_ 817 1;
BA_ "GenMsgAutoGenSnd" BO_ 762 0;
BA_ "GenMsgCycleTime" BO_ 762 1;
BA_ "GenMsgILSupport" BO_ 762 0;
BA_ "GenMsgSendType" BO_ 762 2;
BA_ "VAGTP20_DynConnection" BO_ 762 1;
BA_ "GenMsgAutoGenSnd" BO_ 763 0;
BA_ "GenMsgCycleTime" BO_ 763 1;
BA_ "GenMsgILSupport" BO_ 763 0;
BA_ "GenMsgSendType" BO_ 763 2;
BA_ "VAGTP20_DynConnection" BO_ 763 1;
BA_ "GenMsgAutoGenSnd" BO_ 814 0;
BA_ "GenMsgCycleTime" BO_ 814 1;
BA_ "GenMsgILSupport" BO_ 814 0;
BA_ "GenMsgSendType" BO_ 814 2;
BA_ "VAGTP20_DynConnection" BO_ 814 1;
BA_ "GenMsgAutoGenSnd" BO_ 815 0;
BA_ "GenMsgCycleTime" BO_ 815 1;
BA_ "GenMsgILSupport" BO_ 815 0;
BA_ "GenMsgSendType" BO_ 815 2;
BA_ "VAGTP20_DynConnection" BO_ 815 1;
BA_ "GenMsgAutoGenSnd" BO_ 1888 0;
BA_ "GenMsgCycleTime" BO_ 1888 1;
BA_ "GenMsgILSupport" BO_ 1888 0;
BA_ "GenMsgSendType" BO_ 1888 2;
BA_ "VAGTP20_DynConnection" BO_ 1888 1;
BA_ "GenMsgAutoGenSnd" BO_ 1889 0;
BA_ "GenMsgCycleTime" BO_ 1889 1;
BA_ "GenMsgILSupport" BO_ 1889 0;
BA_ "GenMsgSendType" BO_ 1889 2;
BA_ "VAGTP20_DynConnection" BO_ 1889 1;
BA_ "GenMsgAutoGenSnd" BO_ 756 0;
BA_ "GenMsgCycleTime" BO_ 756 1;
BA_ "GenMsgILSupport" BO_ 756 0;
BA_ "GenMsgSendType" BO_ 756 2;
BA_ "VAGTP20_DynConnection" BO_ 756 1;
BA_ "GenMsgAutoGenSnd" BO_ 757 0;
BA_ "GenMsgCycleTime" BO_ 757 1;
BA_ "GenMsgILSupport" BO_ 757 0;
BA_ "GenMsgSendType" BO_ 757 2;
BA_ "VAGTP20_DynConnection" BO_ 757 1;
BA_ "GenMsgAutoGenSnd" BO_ 808 0;
BA_ "GenMsgCycleTime" BO_ 808 1;
BA_ "GenMsgILSupport" BO_ 808 0;
BA_ "GenMsgSendType" BO_ 808 2;
BA_ "VAGTP20_DynConnection" BO_ 808 1;
BA_ "GenMsgAutoGenSnd" BO_ 809 0;
BA_ "GenMsgCycleTime" BO_ 809 1;
BA_ "GenMsgILSupport" BO_ 809 0;
BA_ "GenMsgSendType" BO_ 809 2;
BA_ "VAGTP20_DynConnection" BO_ 809 1;
BA_ "GenMsgAutoGenSnd" BO_ 824 0;
BA_ "GenMsgCycleTime" BO_ 824 1;
BA_ "GenMsgILSupport" BO_ 824 0;
BA_ "GenMsgSendType" BO_ 824 2;
BA_ "VAGTP20_DynConnection" BO_ 824 1;
BA_ "GenMsgAutoGenSnd" BO_ 825 0;
BA_ "GenMsgCycleTime" BO_ 825 1;
BA_ "GenMsgILSupport" BO_ 825 0;
BA_ "GenMsgSendType" BO_ 825 2;
BA_ "VAGTP20_DynConnection" BO_ 825 1;
BA_ "GenMsgAutoGenSnd" BO_ 760 0;
BA_ "GenMsgCycleTime" BO_ 760 1;
BA_ "GenMsgILSupport" BO_ 760 0;
BA_ "GenMsgSendType" BO_ 760 2;
BA_ "VAGTP20_DynConnection" BO_ 760 1;
BA_ "GenMsgAutoGenSnd" BO_ 761 0;
BA_ "GenMsgCycleTime" BO_ 761 1;
BA_ "GenMsgILSupport" BO_ 761 0;
BA_ "GenMsgSendType" BO_ 761 2;
BA_ "VAGTP20_DynConnection" BO_ 761 1;
BA_ "GenMsgAutoGenSnd" BO_ 828 0;
BA_ "GenMsgCycleTime" BO_ 828 1;
BA_ "GenMsgILSupport" BO_ 828 0;
BA_ "GenMsgSendType" BO_ 828 2;
BA_ "VAGTP20_DynConnection" BO_ 828 1;
BA_ "GenMsgAutoGenSnd" BO_ 829 0;
BA_ "GenMsgCycleTime" BO_ 829 1;
BA_ "GenMsgILSupport" BO_ 829 0;
BA_ "GenMsgSendType" BO_ 829 2;
BA_ "VAGTP20_DynConnection" BO_ 829 1;
BA_ "GenMsgAutoGenSnd" BO_ 830 0;
BA_ "GenMsgCycleTime" BO_ 830 1;
BA_ "GenMsgILSupport" BO_ 830 0;
BA_ "GenMsgSendType" BO_ 830 2;
BA_ "VAGTP20_DynConnection" BO_ 830 1;
BA_ "GenMsgAutoGenSnd" BO_ 831 0;
BA_ "GenMsgCycleTime" BO_ 831 1;
BA_ "GenMsgILSupport" BO_ 831 0;
BA_ "GenMsgSendType" BO_ 831 2;
BA_ "VAGTP20_DynConnection" BO_ 831 1;
BA_ "GenMsgAutoGenSnd" BO_ 1872 0;
BA_ "GenMsgCycleTime" BO_ 1872 1;
BA_ "GenMsgILSupport" BO_ 1872 0;
BA_ "GenMsgSendType" BO_ 1872 2;
BA_ "VAGTP20_DynConnection" BO_ 1872 1;
BA_ "GenMsgAutoGenSnd" BO_ 1873 0;
BA_ "GenMsgCycleTime" BO_ 1873 1;
BA_ "GenMsgILSupport" BO_ 1873 0;
BA_ "GenMsgSendType" BO_ 1873 2;
BA_ "VAGTP20_DynConnection" BO_ 1873 1;
BA_ "GenMsgAutoGenSnd" BO_ 1956 0;
BA_ "GenMsgCycleTime" BO_ 1956 1;
BA_ "GenMsgILSupport" BO_ 1956 0;
BA_ "GenMsgSendType" BO_ 1956 2;
BA_ "VAGTP20_DynConnection" BO_ 1956 1;
BA_ "GenMsgAutoGenSnd" BO_ 1957 0;
BA_ "GenMsgCycleTime" BO_ 1957 1;
BA_ "GenMsgILSupport" BO_ 1957 0;
BA_ "GenMsgSendType" BO_ 1957 2;
BA_ "VAGTP20_DynConnection" BO_ 1957 1;
BA_ "GenMsgAutoGenSnd" BO_ 794 0;
BA_ "GenMsgCycleTime" BO_ 794 1;
BA_ "GenMsgILSupport" BO_ 794 0;
BA_ "GenMsgSendType" BO_ 794 2;
BA_ "VAGTP20_DynConnection" BO_ 794 1;
BA_ "GenMsgAutoGenSnd" BO_ 795 0;
BA_ "GenMsgCycleTime" BO_ 795 1;
BA_ "GenMsgILSupport" BO_ 795 0;
BA_ "GenMsgSendType" BO_ 795 2;
BA_ "VAGTP20_DynConnection" BO_ 795 1;
BA_ "GenMsgAutoGenSnd" BO_ 792 0;
BA_ "GenMsgCycleTime" BO_ 792 1;
BA_ "GenMsgILSupport" BO_ 792 0;
BA_ "GenMsgSendType" BO_ 792 2;
BA_ "VAGTP20_DynConnection" BO_ 792 1;
BA_ "GenMsgAutoGenSnd" BO_ 793 0;
BA_ "GenMsgCycleTime" BO_ 793 1;
BA_ "GenMsgILSupport" BO_ 793 0;
BA_ "GenMsgSendType" BO_ 793 2;
BA_ "VAGTP20_DynConnection" BO_ 793 1;
BA_ "GenMsgAutoGenSnd" BO_ 766 0;
BA_ "GenMsgCycleTime" BO_ 766 1;
BA_ "GenMsgILSupport" BO_ 766 0;
BA_ "GenMsgSendType" BO_ 766 2;
BA_ "VAGTP20_DynConnection" BO_ 766 1;
BA_ "GenMsgAutoGenSnd" BO_ 767 0;
BA_ "GenMsgCycleTime" BO_ 767 1;
BA_ "GenMsgILSupport" BO_ 767 0;
BA_ "GenMsgSendType" BO_ 767 2;
BA_ "VAGTP20_DynConnection" BO_ 767 1;
BA_ "GenMsgAutoGenSnd" BO_ 1856 0;
BA_ "GenMsgCycleTime" BO_ 1856 1;
BA_ "GenMsgILSupport" BO_ 1856 0;
BA_ "GenMsgSendType" BO_ 1856 2;
BA_ "VAGTP20_DynConnection" BO_ 1856 1;
BA_ "GenMsgAutoGenSnd" BO_ 1857 0;
BA_ "GenMsgCycleTime" BO_ 1857 1;
BA_ "GenMsgILSupport" BO_ 1857 0;
BA_ "GenMsgSendType" BO_ 1857 2;
BA_ "VAGTP20_DynConnection" BO_ 1857 1;
BA_ "GenMsgAutoGenSnd" BO_ 1858 0;
BA_ "GenMsgCycleTime" BO_ 1858 1;
BA_ "GenMsgILSupport" BO_ 1858 0;
BA_ "GenMsgSendType" BO_ 1858 2;
BA_ "VAGTP20_DynConnection" BO_ 1858 1;
BA_ "GenMsgAutoGenSnd" BO_ 1859 0;
BA_ "GenMsgCycleTime" BO_ 1859 1;
BA_ "GenMsgILSupport" BO_ 1859 0;
BA_ "GenMsgSendType" BO_ 1859 2;
BA_ "VAGTP20_DynConnection" BO_ 1859 1;
BA_ "GenMsgAutoGenSnd" BO_ 1860 0;
BA_ "GenMsgCycleTime" BO_ 1860 1;
BA_ "GenMsgILSupport" BO_ 1860 0;
BA_ "GenMsgSendType" BO_ 1860 2;
BA_ "VAGTP20_DynConnection" BO_ 1860 1;
BA_ "GenMsgAutoGenSnd" BO_ 1861 0;
BA_ "GenMsgCycleTime" BO_ 1861 1;
BA_ "GenMsgILSupport" BO_ 1861 0;
BA_ "GenMsgSendType" BO_ 1861 2;
BA_ "VAGTP20_DynConnection" BO_ 1861 1;
BA_ "GenMsgAutoGenSnd" BO_ 1864 0;
BA_ "GenMsgCycleTime" BO_ 1864 1;
BA_ "GenMsgILSupport" BO_ 1864 0;
BA_ "GenMsgSendType" BO_ 1864 2;
BA_ "VAGTP20_DynConnection" BO_ 1864 1;
BA_ "GenMsgAutoGenSnd" BO_ 1865 0;
BA_ "GenMsgCycleTime" BO_ 1865 1;
BA_ "GenMsgILSupport" BO_ 1865 0;
BA_ "GenMsgSendType" BO_ 1865 2;
BA_ "VAGTP20_DynConnection" BO_ 1865 1;
BA_ "GenMsgAutoGenSnd" BO_ 1240 0;
BA_ "GenMsgCycleTime" BO_ 1240 1;
BA_ "GenMsgILSupport" BO_ 1240 0;
BA_ "GenMsgSendType" BO_ 1240 2;
BA_ "VAGTP20_DynConnection" BO_ 1240 1;
BA_ "GenMsgAutoGenSnd" BO_ 1241 0;
BA_ "GenMsgCycleTime" BO_ 1241 1;
BA_ "GenMsgILSupport" BO_ 1241 0;
BA_ "GenMsgSendType" BO_ 1241 2;
BA_ "VAGTP20_DynConnection" BO_ 1241 1;
BA_ "GenMsgAutoGenSnd" BO_ 1928 0;
BA_ "GenMsgCycleTime" BO_ 1928 1;
BA_ "GenMsgILSupport" BO_ 1928 0;
BA_ "GenMsgSendType" BO_ 1928 2;
BA_ "VAGTP20_DynConnection" BO_ 1928 1;
BA_ "GenMsgAutoGenSnd" BO_ 1929 0;
BA_ "GenMsgCycleTime" BO_ 1929 1;
BA_ "GenMsgILSupport" BO_ 1929 0;
BA_ "GenMsgSendType" BO_ 1929 2;
BA_ "VAGTP20_DynConnection" BO_ 1929 1;
BA_ "GenMsgAutoGenSnd" BO_ 802 0;
BA_ "GenMsgCycleTime" BO_ 802 1;
BA_ "GenMsgILSupport" BO_ 802 0;
BA_ "GenMsgSendType" BO_ 802 2;
BA_ "VAGTP20_DynConnection" BO_ 802 1;
BA_ "GenMsgAutoGenSnd" BO_ 803 0;
BA_ "GenMsgCycleTime" BO_ 803 1;
BA_ "GenMsgILSupport" BO_ 803 0;
BA_ "GenMsgSendType" BO_ 803 2;
BA_ "VAGTP20_DynConnection" BO_ 803 1;
BA_ "GenMsgAutoGenSnd" BO_ 764 0;
BA_ "GenMsgCycleTime" BO_ 764 1;
BA_ "GenMsgILSupport" BO_ 764 0;
BA_ "GenMsgSendType" BO_ 764 2;
BA_ "VAGTP20_DynConnection" BO_ 764 1;
BA_ "GenMsgAutoGenSnd" BO_ 765 0;
BA_ "GenMsgCycleTime" BO_ 765 1;
BA_ "GenMsgILSupport" BO_ 765 0;
BA_ "GenMsgSendType" BO_ 765 2;
BA_ "VAGTP20_DynConnection" BO_ 765 1;
BA_ "GenMsgAutoGenSnd" BO_ 804 0;
BA_ "GenMsgCycleTime" BO_ 804 1;
BA_ "GenMsgILSupport" BO_ 804 0;
BA_ "GenMsgSendType" BO_ 804 2;
BA_ "VAGTP20_DynConnection" BO_ 804 1;
BA_ "GenMsgAutoGenSnd" BO_ 805 0;
BA_ "GenMsgCycleTime" BO_ 805 1;
BA_ "GenMsgILSupport" BO_ 805 0;
BA_ "GenMsgSendType" BO_ 805 2;
BA_ "VAGTP20_DynConnection" BO_ 805 1;
BA_ "GenMsgCycleTime" BO_ 1976 1;
BA_ "GenMsgILSupport" BO_ 1976 0;
BA_ "GenMsgSendType" BO_ 1976 2;
BA_ "VAGTP20_DynConnection" BO_ 1976 1;
BA_ "GenMsgCycleTime" BO_ 1977 1;
BA_ "GenMsgILSupport" BO_ 1977 0;
BA_ "GenMsgSendType" BO_ 1977 2;
BA_ "VAGTP20_DynConnection" BO_ 1977 1;
BA_ "GenMsgAutoGenSnd" BO_ 1264 0;
BA_ "GenMsgCycleTime" BO_ 1264 1;
BA_ "GenMsgILSupport" BO_ 1264 0;
BA_ "GenMsgSendType" BO_ 1264 2;
BA_ "VAGTP20_DynConnection" BO_ 1264 1;
BA_ "GenMsgAutoGenSnd" BO_ 1265 0;
BA_ "GenMsgCycleTime" BO_ 1265 1;
BA_ "GenMsgILSupport" BO_ 1265 0;
BA_ "GenMsgSendType" BO_ 1265 2;
BA_ "VAGTP20_DynConnection" BO_ 1265 1;
BA_ "GenMsgAutoGenSnd" BO_ 1268 0;
BA_ "GenMsgCycleTime" BO_ 1268 1;
BA_ "GenMsgILSupport" BO_ 1268 0;
BA_ "GenMsgSendType" BO_ 1268 2;
BA_ "VAGTP20_DynConnection" BO_ 1268 1;
BA_ "GenMsgAutoGenSnd" BO_ 1269 0;
BA_ "GenMsgCycleTime" BO_ 1269 1;
BA_ "GenMsgILSupport" BO_ 1269 0;
BA_ "GenMsgSendType" BO_ 1269 2;
BA_ "VAGTP20_DynConnection" BO_ 1269 1;
BA_ "GenMsgCycleTime" BO_ 768 1;
BA_ "GenMsgILSupport" BO_ 768 0;
BA_ "GenMsgSendType" BO_ 768 2;
BA_ "VAGTP20_DynConnection" BO_ 768 1;
BA_ "GenMsgCycleTime" BO_ 769 1;
BA_ "GenMsgILSupport" BO_ 769 0;
BA_ "GenMsgSendType" BO_ 769 2;
BA_ "VAGTP20_DynConnection" BO_ 769 1;
BA_ "GenMsgAutoGenSnd" BO_ 786 0;
BA_ "GenMsgCycleTime" BO_ 786 1;
BA_ "GenMsgILSupport" BO_ 786 0;
BA_ "GenMsgSendType" BO_ 786 2;
BA_ "VAGTP20_DynConnection" BO_ 786 1;
BA_ "GenMsgAutoGenSnd" BO_ 787 0;
BA_ "GenMsgCycleTime" BO_ 787 1;
BA_ "GenMsgILSupport" BO_ 787 0;
BA_ "GenMsgSendType" BO_ 787 2;
BA_ "VAGTP20_DynConnection" BO_ 787 1;
BA_ "GenMsgAutoGenSnd" BO_ 784 0;
BA_ "GenMsgCycleTime" BO_ 784 1;
BA_ "GenMsgILSupport" BO_ 784 0;
BA_ "GenMsgSendType" BO_ 784 2;
BA_ "VAGTP20_DynConnection" BO_ 784 1;
BA_ "GenMsgAutoGenSnd" BO_ 785 0;
BA_ "GenMsgCycleTime" BO_ 785 1;
BA_ "GenMsgILSupport" BO_ 785 0;
BA_ "GenMsgSendType" BO_ 785 2;
BA_ "VAGTP20_DynConnection" BO_ 785 1;
BA_ "GenMsgAutoGenSnd" BO_ 788 0;
BA_ "GenMsgCycleTime" BO_ 788 1;
BA_ "GenMsgILSupport" BO_ 788 0;
BA_ "GenMsgSendType" BO_ 788 2;
BA_ "VAGTP20_DynConnection" BO_ 788 1;
BA_ "GenMsgAutoGenSnd" BO_ 789 0;
BA_ "GenMsgCycleTime" BO_ 789 1;
BA_ "GenMsgILSupport" BO_ 789 0;
BA_ "GenMsgSendType" BO_ 789 2;
BA_ "VAGTP20_DynConnection" BO_ 789 1;
BA_ "GenMsgAutoGenSnd" BO_ 790 0;
BA_ "GenMsgCycleTime" BO_ 790 1;
BA_ "GenMsgILSupport" BO_ 790 0;
BA_ "GenMsgSendType" BO_ 790 2;
BA_ "VAGTP20_DynConnection" BO_ 790 1;
BA_ "GenMsgAutoGenSnd" BO_ 791 0;
BA_ "GenMsgCycleTime" BO_ 791 1;
BA_ "GenMsgILSupport" BO_ 791 0;
BA_ "GenMsgSendType" BO_ 791 2;
BA_ "VAGTP20_DynConnection" BO_ 791 1;
BA_ "GenMsgAutoGenSnd" BO_ 515 0;
BA_ "GenMsgILSupport" BO_ 515 0;
BA_ "GenMsgSendType" BO_ 515 7;
BA_ "VAGTP20_DynSetup" BO_ 515 1;
BA_ "GenMsgAutoGenSnd" BO_ 523 0;
BA_ "GenMsgILSupport" BO_ 523 0;
BA_ "GenMsgSendType" BO_ 523 7;
BA_ "VAGTP20_DynSetup" BO_ 523 1;
BA_ "GenMsgAutoGenSnd" BO_ 517 0;
BA_ "GenMsgILSupport" BO_ 517 0;
BA_ "GenMsgSendType" BO_ 517 7;
BA_ "VAGTP20_DynSetup" BO_ 517 1;
BA_ "GenMsgAutoGenSnd" BO_ 579 0;
BA_ "GenMsgILSupport" BO_ 579 0;
BA_ "GenMsgSendType" BO_ 579 7;
BA_ "VAGTP20_DynSetup" BO_ 579 1;
BA_ "GenMsgAutoGenSnd" BO_ 563 0;
BA_ "GenMsgILSupport" BO_ 563 0;
BA_ "GenMsgSendType" BO_ 563 7;
BA_ "VAGTP20_DynSetup" BO_ 563 1;
BA_ "GenMsgAutoGenSnd" BO_ 591 0;
BA_ "GenMsgILSupport" BO_ 591 0;
BA_ "GenMsgSendType" BO_ 591 7;
BA_ "VAGTP20_DynSetup" BO_ 591 1;
BA_ "GenMsgAutoGenSnd" BO_ 595 0;
BA_ "GenMsgILSupport" BO_ 595 0;
BA_ "GenMsgSendType" BO_ 595 7;
BA_ "VAGTP20_DynSetup" BO_ 595 1;
BA_ "GenMsgAutoGenSnd" BO_ 518 0;
BA_ "GenMsgILSupport" BO_ 518 0;
BA_ "GenMsgSendType" BO_ 518 7;
BA_ "VAGTP20_DynSetup" BO_ 518 1;
BA_ "GenMsgAutoGenSnd" BO_ 557 0;
BA_ "GenMsgILSupport" BO_ 557 0;
BA_ "GenMsgSendType" BO_ 557 7;
BA_ "VAGTP20_DynSetup" BO_ 557 1;
BA_ "GenMsgAutoGenSnd" BO_ 537 0;
BA_ "GenMsgILSupport" BO_ 537 0;
BA_ "GenMsgSendType" BO_ 537 7;
BA_ "VAGTP20_DynSetup" BO_ 537 1;
BA_ "GenMsgAutoGenSnd" BO_ 561 0;
BA_ "GenMsgILSupport" BO_ 561 0;
BA_ "GenMsgSendType" BO_ 561 7;
BA_ "VAGTP20_DynSetup" BO_ 561 1;
BA_ "GenMsgAutoGenSnd" BO_ 594 0;
BA_ "GenMsgILSupport" BO_ 594 0;
BA_ "GenMsgSendType" BO_ 594 7;
BA_ "VAGTP20_DynSetup" BO_ 594 1;
BA_ "GenMsgAutoGenSnd" BO_ 514 0;
BA_ "GenMsgILSupport" BO_ 514 0;
BA_ "GenMsgSendType" BO_ 514 7;
BA_ "VAGTP20_DynSetup" BO_ 514 1;
BA_ "GenMsgAutoGenSnd" BO_ 564 0;
BA_ "GenMsgILSupport" BO_ 564 0;
BA_ "GenMsgSendType" BO_ 564 7;
BA_ "VAGTP20_DynSetup" BO_ 564 1;
BA_ "GenMsgAutoGenSnd" BO_ 606 0;
BA_ "GenMsgILSupport" BO_ 606 0;
BA_ "GenMsgSendType" BO_ 606 7;
BA_ "VAGTP20_DynSetup" BO_ 606 1;
BA_ "GenMsgAutoGenSnd" BO_ 605 0;
BA_ "GenMsgILSupport" BO_ 605 0;
BA_ "GenMsgSendType" BO_ 605 7;
BA_ "VAGTP20_DynSetup" BO_ 605 1;
BA_ "GenMsgAutoGenSnd" BO_ 545 0;
BA_ "GenMsgILSupport" BO_ 545 0;
BA_ "GenMsgSendType" BO_ 545 7;
BA_ "VAGTP20_DynSetup" BO_ 545 1;
BA_ "GenMsgAutoGenSnd" BO_ 544 0;
BA_ "GenMsgILSupport" BO_ 544 0;
BA_ "GenMsgSendType" BO_ 544 7;
BA_ "VAGTP20_DynSetup" BO_ 544 1;
BA_ "GenMsgAutoGenSnd" BO_ 552 0;
BA_ "GenMsgILSupport" BO_ 552 0;
BA_ "GenMsgSendType" BO_ 552 7;
BA_ "VAGTP20_DynSetup" BO_ 552 1;
BA_ "GenMsgAutoGenSnd" BO_ 556 0;
BA_ "GenMsgILSupport" BO_ 556 0;
BA_ "GenMsgSendType" BO_ 556 7;
BA_ "VAGTP20_DynSetup" BO_ 556 1;
BA_ "GenMsgAutoGenSnd" BO_ 581 0;
BA_ "GenMsgILSupport" BO_ 581 0;
BA_ "GenMsgSendType" BO_ 581 7;
BA_ "VAGTP20_DynSetup" BO_ 581 1;
BA_ "GenMsgAutoGenSnd" BO_ 519 0;
BA_ "GenMsgILSupport" BO_ 519 0;
BA_ "GenMsgSendType" BO_ 519 7;
BA_ "VAGTP20_DynSetup" BO_ 519 1;
BA_ "GenMsgAutoGenSnd" BO_ 584 0;
BA_ "GenMsgILSupport" BO_ 584 0;
BA_ "GenMsgSendType" BO_ 584 7;
BA_ "VAGTP20_DynSetup" BO_ 584 1;
BA_ "GenMsgAutoGenSnd" BO_ 538 0;
BA_ "GenMsgILSupport" BO_ 538 0;
BA_ "GenMsgSendType" BO_ 538 7;
BA_ "VAGTP20_DynSetup" BO_ 538 1;
BA_ "GenMsgAutoGenSnd" BO_ 531 0;
BA_ "GenMsgILSupport" BO_ 531 0;
BA_ "GenMsgSendType" BO_ 531 7;
BA_ "VAGTP20_DynSetup" BO_ 531 1;
BA_ "GenMsgAutoGenSnd" BO_ 600 0;
BA_ "GenMsgILSupport" BO_ 600 0;
BA_ "GenMsgSendType" BO_ 600 7;
BA_ "VAGTP20_DynSetup" BO_ 600 1;
BA_ "GenMsgAutoGenSnd" BO_ 592 0;
BA_ "GenMsgILSupport" BO_ 592 0;
BA_ "GenMsgSendType" BO_ 592 7;
BA_ "VAGTP20_DynSetup" BO_ 592 1;
BA_ "GenMsgAutoGenSnd" BO_ 596 0;
BA_ "GenMsgILSupport" BO_ 596 0;
BA_ "GenMsgSendType" BO_ 596 7;
BA_ "VAGTP20_DynSetup" BO_ 596 1;
BA_ "GenMsgAutoGenSnd" BO_ 610 0;
BA_ "GenMsgILSupport" BO_ 610 0;
BA_ "GenMsgSendType" BO_ 610 7;
BA_ "VAGTP20_DynSetup" BO_ 610 1;
BA_ "GenMsgAutoGenSnd" BO_ 565 0;
BA_ "GenMsgILSupport" BO_ 565 0;
BA_ "GenMsgSendType" BO_ 565 7;
BA_ "VAGTP20_DynSetup" BO_ 565 1;
BA_ "GenMsgAutoGenSnd" BO_ 550 0;
BA_ "GenMsgILSupport" BO_ 550 0;
BA_ "GenMsgSendType" BO_ 550 7;
BA_ "VAGTP20_DynSetup" BO_ 550 1;
BA_ "GenMsgAutoGenSnd" BO_ 570 0;
BA_ "GenMsgILSupport" BO_ 570 0;
BA_ "GenMsgSendType" BO_ 570 7;
BA_ "VAGTP20_DynSetup" BO_ 570 1;
BA_ "GenMsgAutoGenSnd" BO_ 575 0;
BA_ "GenMsgILSupport" BO_ 575 0;
BA_ "GenMsgSendType" BO_ 575 7;
BA_ "VAGTP20_DynSetup" BO_ 575 1;
BA_ "GenMsgAutoGenSnd" BO_ 574 0;
BA_ "GenMsgILSupport" BO_ 574 0;
BA_ "GenMsgSendType" BO_ 574 7;
BA_ "VAGTP20_DynSetup" BO_ 574 1;
BA_ "GenMsgAutoGenSnd" BO_ 513 0;
BA_ "GenMsgILSupport" BO_ 513 0;
BA_ "GenMsgSendType" BO_ 513 7;
BA_ "VAGTP20_DynSetup" BO_ 513 1;
BA_ "GenMsgAutoGenSnd" BO_ 533 0;
BA_ "GenMsgILSupport" BO_ 533 0;
BA_ "GenMsgSendType" BO_ 533 7;
BA_ "VAGTP20_DynSetup" BO_ 533 1;
BA_ "GenMsgAutoGenSnd" BO_ 534 0;
BA_ "GenMsgILSupport" BO_ 534 0;
BA_ "GenMsgSendType" BO_ 534 7;
BA_ "VAGTP20_DynSetup" BO_ 534 1;
BA_ "GenMsgAutoGenSnd" BO_ 603 0;
BA_ "GenMsgILSupport" BO_ 603 0;
BA_ "GenMsgSendType" BO_ 603 7;
BA_ "VAGTP20_DynSetup" BO_ 603 1;
BA_ "GenMsgAutoGenSnd" BO_ 516 0;
BA_ "GenMsgILSupport" BO_ 516 0;
BA_ "GenMsgSendType" BO_ 516 7;
BA_ "VAGTP20_DynSetup" BO_ 516 1;
BA_ "GenMsgAutoGenSnd" BO_ 553 0;
BA_ "GenMsgILSupport" BO_ 553 0;
BA_ "GenMsgSendType" BO_ 553 7;
BA_ "VAGTP20_DynSetup" BO_ 553 1;
BA_ "GenMsgAutoGenSnd" BO_ 607 0;
BA_ "GenMsgILSupport" BO_ 607 0;
BA_ "GenMsgSendType" BO_ 607 7;
BA_ "VAGTP20_DynSetup" BO_ 607 1;
BA_ "GenMsgAutoGenSnd" BO_ 604 0;
BA_ "GenMsgILSupport" BO_ 604 0;
BA_ "GenMsgSendType" BO_ 604 7;
BA_ "VAGTP20_DynSetup" BO_ 604 1;
BA_ "GenMsgAutoGenSnd" BO_ 554 0;
BA_ "GenMsgILSupport" BO_ 554 0;
BA_ "GenMsgSendType" BO_ 554 7;
BA_ "VAGTP20_DynSetup" BO_ 554 1;
BA_ "GenMsgAutoGenSnd" BO_ 559 0;
BA_ "GenMsgILSupport" BO_ 559 0;
BA_ "GenMsgSendType" BO_ 559 7;
BA_ "VAGTP20_DynSetup" BO_ 559 1;
BA_ "GenMsgAutoGenSnd" BO_ 540 0;
BA_ "GenMsgILSupport" BO_ 540 0;
BA_ "GenMsgSendType" BO_ 540 7;
BA_ "VAGTP20_DynSetup" BO_ 540 1;
BA_ "GenMsgAutoGenSnd" BO_ 602 0;
BA_ "GenMsgILSupport" BO_ 602 0;
BA_ "GenMsgSendType" BO_ 602 7;
BA_ "VAGTP20_DynSetup" BO_ 602 1;
BA_ "GenMsgAutoGenSnd" BO_ 597 0;
BA_ "GenMsgILSupport" BO_ 597 0;
BA_ "GenMsgSendType" BO_ 597 7;
BA_ "VAGTP20_DynSetup" BO_ 597 1;
BA_ "GenMsgAutoGenSnd" BO_ 512 0;
BA_ "GenMsgILSupport" BO_ 512 0;
BA_ "GenMsgSendType" BO_ 512 7;
BA_ "VAGTP20_DynSetup" BO_ 512 1;
BA_ "GenMsgAutoGenSnd" BO_ 527 0;
BA_ "GenMsgILSupport" BO_ 527 0;
BA_ "GenMsgSendType" BO_ 527 7;
BA_ "VAGTP20_DynSetup" BO_ 527 1;
BA_ "GenMsgAutoGenSnd" BO_ 547 0;
BA_ "GenMsgILSupport" BO_ 547 0;
BA_ "GenMsgSendType" BO_ 547 7;
BA_ "VAGTP20_DynSetup" BO_ 547 1;
BA_ "GenMsgAutoGenSnd" BO_ 546 0;
BA_ "GenMsgILSupport" BO_ 546 0;
BA_ "GenMsgSendType" BO_ 546 7;
BA_ "VAGTP20_DynSetup" BO_ 546 1;
BA_ "GenMsgAutoGenSnd" BO_ 548 0;
BA_ "GenMsgILSupport" BO_ 548 0;
BA_ "GenMsgSendType" BO_ 548 7;
BA_ "VAGTP20_DynSetup" BO_ 548 1;
BA_ "GenMsgAutoGenSnd" BO_ 549 0;
BA_ "GenMsgILSupport" BO_ 549 0;
BA_ "GenMsgSendType" BO_ 549 7;
BA_ "VAGTP20_DynSetup" BO_ 549 1;
BA_ "GenMsgAutoGenSnd" BO_ 599 0;
BA_ "GenMsgILSupport" BO_ 599 0;
BA_ "GenMsgSendType" BO_ 599 7;
BA_ "VAGTP20_DynSetup" BO_ 599 1;
BA_ "GenMsgAutoGenSnd" BO_ 588 0;
BA_ "GenMsgILSupport" BO_ 588 0;
BA_ "GenMsgSendType" BO_ 588 7;
BA_ "VAGTP20_DynSetup" BO_ 588 1;
BA_ "GenMsgAutoGenSnd" BO_ 1394 0;
BA_ "GenMsgCycleTime" BO_ 1394 100;
BA_ "GenMsgILSupport" BO_ 1394 0;
BA_ "GenMsgSendType" BO_ 1394 5;
BA_ "GenSigAutoGenDsp" SG_ 1160 Absolute_Load_Value 1;
BA_ "GenSigAutoGenSnd" SG_ 1160 Absolute_Load_Value 1;
BA_ "GenSigSendType" SG_ 1160 Absolute_Load_Value 7;
BA_ "NWM-WakeupAllowed" SG_ 1160 Absolute_Load_Value 0;
BA_ "GenSigAutoGenDsp" SG_ 1160 Absolute_Throttle_Position 1;
BA_ "GenSigAutoGenSnd" SG_ 1160 Absolute_Throttle_Position 1;
BA_ "GenSigSendType" SG_ 1160 Absolute_Throttle_Position 7;
BA_ "NWM-WakeupAllowed" SG_ 1160 Absolute_Throttle_Position 0;
BA_ "GenSigAutoGenDsp" SG_ 1160 Accelerator_Pedal_Position 1;
BA_ "GenSigAutoGenSnd" SG_ 1160 Accelerator_Pedal_Position 1;
BA_ "GenSigSendType" SG_ 1160 Accelerator_Pedal_Position 7;
BA_ "NWM-WakeupAllowed" SG_ 1160 Accelerator_Pedal_Position 0;
BA_ "GenSigAutoGenDsp" SG_ 1160 BZ_Muxcode_Motor6 0;
BA_ "GenSigAutoGenSnd" SG_ 1160 BZ_Muxcode_Motor6 0;
BA_ "GenSigSendType" SG_ 1160 BZ_Muxcode_Motor6 7;
BA_ "NWM-WakeupAllowed" SG_ 1160 BZ_Muxcode_Motor6 0;
BA_ "GenSigTimeoutMsg_CVT_C6" SG_ 1160 BZ_Muxcode_Motor6 1160;
BA_ "GenSigAutoGenDsp" SG_ 1160 Calculated_Load_Value 1;
BA_ "GenSigAutoGenSnd" SG_ 1160 Calculated_Load_Value 1;
BA_ "GenSigSendType" SG_ 1160 Calculated_Load_Value 7;
BA_ "NWM-WakeupAllowed" SG_ 1160 Calculated_Load_Value 0;
BA_ "GenSigAutoGenDsp" SG_ 1160 CHK_Motor6 0;
BA_ "GenSigAutoGenSnd" SG_ 1160 CHK_Motor6 0;
BA_ "GenSigSendType" SG_ 1160 CHK_Motor6 7;
BA_ "NWM-WakeupAllowed" SG_ 1160 CHK_Motor6 0;
BA_ "GenSigTimeoutMsg_CVT_C6" SG_ 1160 CHK_Motor6 1160;
BA_ "GenSigAutoGenDsp" SG_ 1160 Engine_Coolant_Temperature 1;
BA_ "GenSigAutoGenSnd" SG_ 1160 Engine_Coolant_Temperature 1;
BA_ "GenSigSendType" SG_ 1160 Engine_Coolant_Temperature 7;
BA_ "NWM-WakeupAllowed" SG_ 1160 Engine_Coolant_Temperature 0;
BA_ "GenSigAutoGenDsp" SG_ 1160 GRA_Bremseingrifffreigabe 0;
BA_ "GenSigAutoGenSnd" SG_ 1160 GRA_Bremseingrifffreigabe 0;
BA_ "GenSigSendType" SG_ 1160 GRA_Bremseingrifffreigabe 7;
BA_ "NWM-WakeupAllowed" SG_ 1160 GRA_Bremseingrifffreigabe 0;
BA_ "GenSigAutoGenDsp" SG_ 1160 GRA_Sollbeschleunigung 0;
BA_ "GenSigAutoGenSnd" SG_ 1160 GRA_Sollbeschleunigung 0;
BA_ "GenSigSendType" SG_ 1160 GRA_Sollbeschleunigung 7;
BA_ "GenSigStartValue" SG_ 1160 GRA_Sollbeschleunigung 166;
BA_ "NWM-WakeupAllowed" SG_ 1160 GRA_Sollbeschleunigung 0;
BA_ "GenSigTimeoutMsg__6HP_C6" SG_ 1160 GRA_Sollbeschleunigung 1160;
BA_ "GenSigAutoGenDsp" SG_ 1160 Hoeheninfo 0;
BA_ "GenSigAutoGenSnd" SG_ 1160 Hoeheninfo 0;
BA_ "GenSigSendType" SG_ 1160 Hoeheninfo 7;
BA_ "NWM-WakeupAllowed" SG_ 1160 Hoeheninfo 0;
BA_ "GenSigTimeoutMsg__6HP_C6" SG_ 1160 Hoeheninfo 1160;
BA_ "GenSigAutoGenDsp" SG_ 1160 Istmoment_Getriebe 0;
BA_ "GenSigAutoGenSnd" SG_ 1160 Istmoment_Getriebe 0;
BA_ "GenSigSendType" SG_ 1160 Istmoment_Getriebe 7;
BA_ "NWM-WakeupAllowed" SG_ 1160 Istmoment_Getriebe 0;
BA_ "GenSigTimeoutMsg__6HP_C6" SG_ 1160 Istmoment_Getriebe 1160;
BA_ "GenSigTimeoutMsg_CVT_C6" SG_ 1160 Istmoment_Getriebe 1160;
BA_ "GenSigAutoGenDsp" SG_ 1160 Luftpfad_aktiv 1;
BA_ "GenSigAutoGenSnd" SG_ 1160 Luftpfad_aktiv 1;
BA_ "GenSigSendType" SG_ 1160 Luftpfad_aktiv 7;
BA_ "NWM-WakeupAllowed" SG_ 1160 Luftpfad_aktiv 0;
BA_ "GenSigAutoGenDsp" SG_ 1160 Oeltemperaturschutz 0;
BA_ "GenSigAutoGenSnd" SG_ 1160 Oeltemperaturschutz 0;
BA_ "GenSigSendType" SG_ 1160 Oeltemperaturschutz 7;
BA_ "NWM-WakeupAllowed" SG_ 1160 Oeltemperaturschutz 0;
BA_ "GenSigTimeoutMsg__6HP_C6" SG_ 1160 Oeltemperaturschutz 1160;
BA_ "GenSigAutoGenDsp" SG_ 1160 Partikelfilter_Regeneration 0;
BA_ "GenSigAutoGenSnd" SG_ 1160 Partikelfilter_Regeneration 0;
BA_ "GenSigSendType" SG_ 1160 Partikelfilter_Regeneration 7;
BA_ "NWM-WakeupAllowed" SG_ 1160 Partikelfilter_Regeneration 0;
BA_ "GenSigTimeoutMsg__6HP_C6" SG_ 1160 Partikelfilter_Regeneration 1160;
BA_ "GenSigAutoGenDsp" SG_ 1160 Rueckmeldung_Momentenintegral 0;
BA_ "GenSigAutoGenSnd" SG_ 1160 Rueckmeldung_Momentenintegral 0;
BA_ "GenSigSendType" SG_ 1160 Rueckmeldung_Momentenintegral 7;
BA_ "NWM-WakeupAllowed" SG_ 1160 Rueckmeldung_Momentenintegral 0;
BA_ "GenSigAutoGenDsp" SG_ 1160 Sollmoment_Getriebe 0;
BA_ "GenSigAutoGenSnd" SG_ 1160 Sollmoment_Getriebe 0;
BA_ "GenSigSendType" SG_ 1160 Sollmoment_Getriebe 7;
BA_ "NWM-WakeupAllowed" SG_ 1160 Sollmoment_Getriebe 0;
BA_ "GenSigTimeoutMsg__6HP_C6" SG_ 1160 Sollmoment_Getriebe 1160;
BA_ "GenSigTimeoutMsg_CVT_C6" SG_ 1160 Sollmoment_Getriebe 1160;
BA_ "GenSigAutoGenDsp" SG_ 1416 Bereitschaft_PTC_Heizung 0;
BA_ "GenSigAutoGenSnd" SG_ 1416 Bereitschaft_PTC_Heizung 0;
BA_ "GenSigSendType" SG_ 1416 Bereitschaft_PTC_Heizung 7;
BA_ "NWM-WakeupAllowed" SG_ 1416 Bereitschaft_PTC_Heizung 0;
BA_ "GenSigTimeoutMsg_Gateway_C6" SG_ 1416 Bereitschaft_PTC_Heizung 1416;
BA_ "GenSigAutoGenDsp" SG_ 1416 Einschalten_Generator 0;
BA_ "GenSigAutoGenSnd" SG_ 1416 Einschalten_Generator 0;
BA_ "GenSigSendType" SG_ 1416 Einschalten_Generator 7;
BA_ "NWM-WakeupAllowed" SG_ 1416 Einschalten_Generator 0;
BA_ "GenSigTimeoutMsg_Gateway_C6" SG_ 1416 Einschalten_Generator 1416;
BA_ "GenSigAutoGenDsp" SG_ 1416 FSPE_Motor7 0;
BA_ "GenSigAutoGenSnd" SG_ 1416 FSPE_Motor7 0;
BA_ "GenSigSendType" SG_ 1416 FSPE_Motor7 7;
BA_ "NWM-WakeupAllowed" SG_ 1416 FSPE_Motor7 0;
BA_ "GenSigTimeoutMsg_Gateway_C6" SG_ 1416 FSPE_Motor7 1416;
BA_ "GenSigAutoGenDsp" SG_ 1416 FStatus_Oeltemp_Motor 0;
BA_ "GenSigAutoGenSnd" SG_ 1416 FStatus_Oeltemp_Motor 0;
BA_ "GenSigSendType" SG_ 1416 FStatus_Oeltemp_Motor 7;
BA_ "NWM-WakeupAllowed" SG_ 1416 FStatus_Oeltemp_Motor 0;
BA_ "GenSigTimeoutMsg_Gateway_C6" SG_ 1416 FStatus_Oeltemp_Motor 1416;
BA_ "GenSigAutoGenDsp" SG_ 1416 GLR_Motor 0;
BA_ "GenSigAutoGenSnd" SG_ 1416 GLR_Motor 0;
BA_ "GenSigSendType" SG_ 1416 GLR_Motor 7;
BA_ "NWM-WakeupAllowed" SG_ 1416 GLR_Motor 0;
BA_ "GenSigTimeoutMsg_Gateway_C6" SG_ 1416 GLR_Motor 1416;
BA_ "GenSigAutoGenDsp" SG_ 1416 Gluehkerzen_Brennr 0;
BA_ "GenSigAutoGenSnd" SG_ 1416 Gluehkerzen_Brennr 0;
BA_ "GenSigSendType" SG_ 1416 Gluehkerzen_Brennr 7;
BA_ "NWM-WakeupAllowed" SG_ 1416 Gluehkerzen_Brennr 0;
BA_ "GenSigTimeoutMsg_Gateway_C6" SG_ 1416 Gluehkerzen_Brennr 1416;
BA_ "GenSigAutoGenDsp" SG_ 1416 Hoeheninfo 0;
BA_ "GenSigAutoGenSnd" SG_ 1416 Hoeheninfo 0;
BA_ "GenSigSendType" SG_ 1416 Hoeheninfo 7;
BA_ "NWM-WakeupAllowed" SG_ 1416 Hoeheninfo 0;
BA_ "GenSigTimeoutMsg_Gateway_C6" SG_ 1416 Hoeheninfo 1416;
BA_ "GenSigAutoGenDsp" SG_ 1416 Klemme_DFM 0;
BA_ "GenSigAutoGenSnd" SG_ 1416 Klemme_DFM 0;
BA_ "GenSigSendType" SG_ 1416 Klemme_DFM 7;
BA_ "NWM-WakeupAllowed" SG_ 1416 Klemme_DFM 0;
BA_ "GenSigTimeoutMsg_Gateway_C6" SG_ 1416 Klemme_DFM 1416;
BA_ "GenSigAutoGenDsp" SG_ 1416 Ladedruck 0;
BA_ "GenSigAutoGenSnd" SG_ 1416 Ladedruck 0;
BA_ "GenSigSendType" SG_ 1416 Ladedruck 7;
BA_ "NWM-WakeupAllowed" SG_ 1416 Ladedruck 0;
BA_ "GenSigTimeoutMsg_Gateway_C6" SG_ 1416 Ladedruck 1416;
BA_ "GenSigAutoGenDsp" SG_ 1416 Lastabwurf 0;
BA_ "GenSigAutoGenSnd" SG_ 1416 Lastabwurf 0;
BA_ "GenSigSendType" SG_ 1416 Lastabwurf 7;
BA_ "NWM-WakeupAllowed" SG_ 1416 Lastabwurf 0;
BA_ "GenSigTimeoutMsg_Gateway_C6" SG_ 1416 Lastabwurf 1416;
BA_ "GenSigAutoGenDsp" SG_ 1416 Lastabwurf_Heizsysteme 0;
BA_ "GenSigAutoGenSnd" SG_ 1416 Lastabwurf_Heizsysteme 0;
BA_ "GenSigSendType" SG_ 1416 Lastabwurf_Heizsysteme 7;
BA_ "NWM-WakeupAllowed" SG_ 1416 Lastabwurf_Heizsysteme 0;
BA_ "GenSigTimeoutMsg_Gateway_C6" SG_ 1416 Lastabwurf_Heizsysteme 1416;
BA_ "GenSigAutoGenDsp" SG_ 1416 MDG 0;
BA_ "GenSigAutoGenSnd" SG_ 1416 MDG 0;
BA_ "GenSigSendType" SG_ 1416 MDG 7;
BA_ "NWM-WakeupAllowed" SG_ 1416 MDG 0;
BA_ "GenSigTimeoutMsg_Gateway_C6" SG_ 1416 MDG 1416;
BA_ "GenSigAutoGenDsp" SG_ 1416 Oeltemperatur 0;
BA_ "GenSigAutoGenSnd" SG_ 1416 Oeltemperatur 0;
BA_ "GenSigSendType" SG_ 1416 Oeltemperatur 7;
BA_ "GenSigStartValue" SG_ 1416 Oeltemperatur 1;
BA_ "NWM-WakeupAllowed" SG_ 1416 Oeltemperatur 0;
BA_ "GenSigTimeoutMsg_Gateway_C6" SG_ 1416 Oeltemperatur 1416;
BA_ "GenSigAutoGenDsp" SG_ 1416 PTC_Gluehstifte_ausgeschaltet 0;
BA_ "GenSigAutoGenSnd" SG_ 1416 PTC_Gluehstifte_ausgeschaltet 0;
BA_ "GenSigSendType" SG_ 1416 PTC_Gluehstifte_ausgeschaltet 7;
BA_ "GenSigStartValue" SG_ 1416 PTC_Gluehstifte_ausgeschaltet 7;
BA_ "NWM-WakeupAllowed" SG_ 1416 PTC_Gluehstifte_ausgeschaltet 0;
BA_ "GenSigTimeoutMsg_Gateway_C6" SG_ 1416 PTC_Gluehstifte_ausgeschaltet 1416;
BA_ "GenSigAutoGenDsp" SG_ 1416 RLS_Stufe1 0;
BA_ "GenSigAutoGenSnd" SG_ 1416 RLS_Stufe1 0;
BA_ "GenSigSendType" SG_ 1416 RLS_Stufe1 7;
BA_ "NWM-WakeupAllowed" SG_ 1416 RLS_Stufe1 0;
BA_ "GenSigTimeoutMsg_Gateway_C6" SG_ 1416 RLS_Stufe1 1416;
BA_ "GenSigAutoGenDsp" SG_ 1416 RLS_Stufe2 0;
BA_ "GenSigAutoGenSnd" SG_ 1416 RLS_Stufe2 0;
BA_ "GenSigSendType" SG_ 1416 RLS_Stufe2 7;
BA_ "NWM-WakeupAllowed" SG_ 1416 RLS_Stufe2 0;
BA_ "GenSigTimeoutMsg_Gateway_C6" SG_ 1416 RLS_Stufe2 1416;
BA_ "GenSigAutoGenDsp" SG_ 1416 SIB_Motor 0;
BA_ "GenSigAutoGenSnd" SG_ 1416 SIB_Motor 0;
BA_ "GenSigSendType" SG_ 1416 SIB_Motor 7;
BA_ "NWM-WakeupAllowed" SG_ 1416 SIB_Motor 0;
BA_ "GenSigTimeoutMsg_Gateway_C6" SG_ 1416 SIB_Motor 1416;
BA_ "GenSigAutoGenDsp" SG_ 1416 Signum_MDG 0;
BA_ "GenSigAutoGenSnd" SG_ 1416 Signum_MDG 0;
BA_ "GenSigSendType" SG_ 1416 Signum_MDG 7;
BA_ "NWM-WakeupAllowed" SG_ 1416 Signum_MDG 0;
BA_ "GenSigTimeoutMsg_Gateway_C6" SG_ 1416 Signum_MDG 1416;
BA_ "GenSigAutoGenDsp" SG_ 1416 V_Begrenz_Aktiv 0;
BA_ "GenSigAutoGenSnd" SG_ 1416 V_Begrenz_Aktiv 0;
BA_ "GenSigSendType" SG_ 1416 V_Begrenz_Aktiv 7;
BA_ "NWM-WakeupAllowed" SG_ 1416 V_Begrenz_Aktiv 0;
BA_ "GenSigTimeoutMsg_Gateway_C6" SG_ 1416 V_Begrenz_Aktiv 1416;
BA_ "GenSigAutoGenDsp" SG_ 1416 V_Begrenz_Aktivierbar 0;
BA_ "GenSigAutoGenSnd" SG_ 1416 V_Begrenz_Aktivierbar 0;
BA_ "GenSigSendType" SG_ 1416 V_Begrenz_Aktivierbar 7;
BA_ "NWM-WakeupAllowed" SG_ 1416 V_Begrenz_Aktivierbar 0;
BA_ "GenSigTimeoutMsg_Gateway_C6" SG_ 1416 V_Begrenz_Aktivierbar 1416;
BA_ "GenSigAutoGenDsp" SG_ 1416 Zusaetzliche_Kuehlung 0;
BA_ "GenSigAutoGenSnd" SG_ 1416 Zusaetzliche_Kuehlung 0;
BA_ "GenSigSendType" SG_ 1416 Zusaetzliche_Kuehlung 7;
BA_ "NWM-WakeupAllowed" SG_ 1416 Zusaetzliche_Kuehlung 0;
BA_ "GenSigTimeoutMsg_Gateway_C6" SG_ 1416 Zusaetzliche_Kuehlung 1416;
BA_ "GenSigAutoGenDsp" SG_ 1162 Avus_Motorschutz 1;
BA_ "GenSigAutoGenSnd" SG_ 1162 Avus_Motorschutz 1;
BA_ "GenSigSendType" SG_ 1162 Avus_Motorschutz 7;
BA_ "NWM-WakeupAllowed" SG_ 1162 Avus_Motorschutz 0;
BA_ "GenSigTimeoutMsg_Gateway_C6" SG_ 1162 Avus_Motorschutz 1162;
BA_ "GenSigAutoGenDsp" SG_ 1162 BZ_Motor8 0;
BA_ "GenSigAutoGenSnd" SG_ 1162 BZ_Motor8 0;
BA_ "GenSigSendType" SG_ 1162 BZ_Motor8 7;
BA_ "NWM-WakeupAllowed" SG_ 1162 BZ_Motor8 0;
BA_ "GenSigTimeoutMsg_Gateway_C6" SG_ 1162 BZ_Motor8 1162;
BA_ "GenSigAutoGenDsp" SG_ 1162 CHK_Motor8 0;
BA_ "GenSigAutoGenSnd" SG_ 1162 CHK_Motor8 0;
BA_ "GenSigSendType" SG_ 1162 CHK_Motor8 7;
BA_ "NWM-WakeupAllowed" SG_ 1162 CHK_Motor8 0;
BA_ "GenSigTimeoutMsg_Gateway_C6" SG_ 1162 CHK_Motor8 1162;
BA_ "GenSigAutoGenDsp" SG_ 1162 Enable_Oeldr_Motor 1;
BA_ "GenSigAutoGenSnd" SG_ 1162 Enable_Oeldr_Motor 1;
BA_ "GenSigSendType" SG_ 1162 Enable_Oeldr_Motor 7;
BA_ "NWM-WakeupAllowed" SG_ 1162 Enable_Oeldr_Motor 0;
BA_ "GenSigTimeoutMsg_Gateway_C6" SG_ 1162 Enable_Oeldr_Motor 1162;
BA_ "GenSigAutoGenDsp" SG_ 1162 GRA_Wunschgeschw 1;
BA_ "GenSigAutoGenSnd" SG_ 1162 GRA_Wunschgeschw 1;
BA_ "GenSigSendType" SG_ 1162 GRA_Wunschgeschw 7;
BA_ "NWM-WakeupAllowed" SG_ 1162 GRA_Wunschgeschw 0;
BA_ "GenSigTimeoutMsg_Gateway_C6" SG_ 1162 GRA_Wunschgeschw 1162;
BA_ "GenSigAutoGenDsp" SG_ 1162 Oeldruck_Warn_Motor 1;
BA_ "GenSigAutoGenSnd" SG_ 1162 Oeldruck_Warn_Motor 1;
BA_ "GenSigSendType" SG_ 1162 Oeldruck_Warn_Motor 7;
BA_ "NWM-WakeupAllowed" SG_ 1162 Oeldruck_Warn_Motor 0;
BA_ "GenSigTimeoutMsg_Gateway_C6" SG_ 1162 Oeldruck_Warn_Motor 1162;
BA_ "GenSigAutoGenDsp" SG_ 1162 Optimierte_Anzeigedrehzahl 1;
BA_ "GenSigAutoGenSnd" SG_ 1162 Optimierte_Anzeigedrehzahl 1;
BA_ "GenSigSendType" SG_ 1162 Optimierte_Anzeigedrehzahl 7;
BA_ "NWM-WakeupAllowed" SG_ 1162 Optimierte_Anzeigedrehzahl 0;
BA_ "GenSigTimeoutMsg_Gateway_C6" SG_ 1162 Optimierte_Anzeigedrehzahl 1162;
BA_ "GenSigAutoGenDsp" SG_ 1408 Ansaugsystem 0;
BA_ "GenSigAutoGenSnd" SG_ 1408 Ansaugsystem 0;
BA_ "GenSigSendType" SG_ 1408 Ansaugsystem 7;
BA_ "NWM-WakeupAllowed" SG_ 1408 Ansaugsystem 0;
BA_ "GenSigTimeoutMsg_ESP8_C6" SG_ 1408 Ansaugsystem 1408;
BA_ "GenSigTimeoutMsg_Gateway_C6" SG_ 1408 Ansaugsystem 1408;
BA_ "GenSigTimeoutMsg_Gateway_C6" SG_ 1408 Ansaugsystem 1408;
BA_ "GenSigAutoGenDsp" SG_ 1408 Anzahl_Mittelung_sO 0;
BA_ "GenSigAutoGenSnd" SG_ 1408 Anzahl_Mittelung_sO 0;
BA_ "GenSigSendType" SG_ 1408 Anzahl_Mittelung_sO 7;
BA_ "NWM-WakeupAllowed" SG_ 1408 Anzahl_Mittelung_sO 0;
BA_ "GenSigTimeoutMsg_Gateway_C6" SG_ 1408 Anzahl_Mittelung_sO 1408;
BA_ "GenSigAutoGenDsp" SG_ 1408 Anzahl_Mittelwert_gO 0;
BA_ "GenSigAutoGenSnd" SG_ 1408 Anzahl_Mittelwert_gO 0;
BA_ "GenSigSendType" SG_ 1408 Anzahl_Mittelwert_gO 7;
BA_ "NWM-WakeupAllowed" SG_ 1408 Anzahl_Mittelwert_gO 0;
BA_ "GenSigTimeoutMsg_Gateway_C6" SG_ 1408 Anzahl_Mittelwert_gO 1408;
BA_ "GenSigAutoGenDsp" SG_ 1408 Anzahl_Ventile 0;
BA_ "GenSigAutoGenSnd" SG_ 1408 Anzahl_Ventile 0;
BA_ "GenSigSendType" SG_ 1408 Anzahl_Ventile 7;
BA_ "NWM-WakeupAllowed" SG_ 1408 Anzahl_Ventile 0;
BA_ "GenSigTimeoutMsg_Gateway_C6" SG_ 1408 Anzahl_Ventile 1408;
BA_ "GenSigTimeoutMsg_Gateway_C6" SG_ 1408 Anzahl_Ventile 1408;
BA_ "GenSigAutoGenDsp" SG_ 1408 Anzahl_Zylinder 0;
BA_ "GenSigAutoGenSnd" SG_ 1408 Anzahl_Zylinder 0;
BA_ "GenSigSendType" SG_ 1408 Anzahl_Zylinder 7;
BA_ "NWM-WakeupAllowed" SG_ 1408 Anzahl_Zylinder 0;
BA_ "GenSigTimeoutMsg_Gateway_C6" SG_ 1408 Anzahl_Zylinder 1408;
BA_ "GenSigTimeoutMsg_ESP8_C6" SG_ 1408 Anzahl_Zylinder 1408;
BA_ "GenSigTimeoutMsg_Gateway_C6" SG_ 1408 Anzahl_Zylinder 1408;
BA_ "GenSigAutoGenDsp" SG_ 1408 BZ_MFn_Rest 0;
BA_ "GenSigAutoGenSnd" SG_ 1408 BZ_MFn_Rest 0;
BA_ "GenSigSendType" SG_ 1408 BZ_MFn_Rest 7;
BA_ "NWM-WakeupAllowed" SG_ 1408 BZ_MFn_Rest 0;
BA_ "GenSigTimeoutMsg_Gateway_C6" SG_ 1408 BZ_MFn_Rest 1408;
BA_ "GenSigAutoGenDsp" SG_ 1408 Drehzahl_MaxMom 0;
BA_ "GenSigAutoGenSnd" SG_ 1408 Drehzahl_MaxMom 0;
BA_ "GenSigSendType" SG_ 1408 Drehzahl_MaxMom 7;
BA_ "NWM-WakeupAllowed" SG_ 1408 Drehzahl_MaxMom 0;
BA_ "GenSigTimeoutMsg_Gateway_C6" SG_ 1408 Drehzahl_MaxMom 1408;
BA_ "GenSigTimeoutMsg_Gateway_C6" SG_ 1408 Drehzahl_MaxMom 1408;
BA_ "GenSigAutoGenDsp" SG_ 1408 Driving_Cycle 0;
BA_ "GenSigAutoGenSnd" SG_ 1408 Driving_Cycle 0;
BA_ "GenSigSendType" SG_ 1408 Driving_Cycle 7;
BA_ "NWM-WakeupAllowed" SG_ 1408 Driving_Cycle 0;
BA_ "GenSigTimeoutMsg_Gateway_C6" SG_ 1408 Driving_Cycle 1408;
BA_ "GenSigAutoGenDsp" SG_ 1408 Hubraum 0;
BA_ "GenSigAutoGenSnd" SG_ 1408 Hubraum 0;
BA_ "GenSigSendType" SG_ 1408 Hubraum 7;
BA_ "NWM-WakeupAllowed" SG_ 1408 Hubraum 0;
BA_ "GenSigTimeoutMsg_ESP8_C6" SG_ 1408 Hubraum 1408;
BA_ "GenSigTimeoutMsg_Gateway_C6" SG_ 1408 Hubraum 1408;
BA_ "GenSigTimeoutMsg_Gateway_C6" SG_ 1408 Hubraum 1408;
BA_ "GenSigAutoGenDsp" SG_ 1408 Intervall_tmax 0;
BA_ "GenSigAutoGenSnd" SG_ 1408 Intervall_tmax 0;
BA_ "GenSigSendType" SG_ 1408 Intervall_tmax 7;
BA_ "NWM-WakeupAllowed" SG_ 1408 Intervall_tmax 0;
BA_ "GenSigTimeoutMsg_Gateway_C6" SG_ 1408 Intervall_tmax 1408;
BA_ "GenSigAutoGenDsp" SG_ 1408 Intervall_tmin 0;
BA_ "GenSigAutoGenSnd" SG_ 1408 Intervall_tmin 0;
BA_ "GenSigSendType" SG_ 1408 Intervall_tmin 7;
BA_ "NWM-WakeupAllowed" SG_ 1408 Intervall_tmin 0;
BA_ "GenSigTimeoutMsg_Gateway_C6" SG_ 1408 Intervall_tmin 1408;
BA_ "GenSigAutoGenDsp" SG_ 1408 Intervall_Wmax 0;
BA_ "GenSigAutoGenSnd" SG_ 1408 Intervall_Wmax 0;
BA_ "GenSigSendType" SG_ 1408 Intervall_Wmax 7;
BA_ "NWM-WakeupAllowed" SG_ 1408 Intervall_Wmax 0;
BA_ "GenSigTimeoutMsg_Gateway_C6" SG_ 1408 Intervall_Wmax 1408;
BA_ "GenSigAutoGenDsp" SG_ 1408 Intervall_Wmin 0;
BA_ "GenSigAutoGenSnd" SG_ 1408 Intervall_Wmin 0;
BA_ "GenSigSendType" SG_ 1408 Intervall_Wmin 7;
BA_ "NWM-WakeupAllowed" SG_ 1408 Intervall_Wmin 0;
BA_ "GenSigTimeoutMsg_Gateway_C6" SG_ 1408 Intervall_Wmin 1408;
BA_ "GenSigAutoGenDsp" SG_ 1408 Kurzzeitmittelwert 0;
BA_ "GenSigAutoGenSnd" SG_ 1408 Kurzzeitmittelwert 0;
BA_ "GenSigSendType" SG_ 1408 Kurzzeitmittelwert 7;
BA_ "NWM-WakeupAllowed" SG_ 1408 Kurzzeitmittelwert 0;
BA_ "GenSigTimeoutMsg_Gateway_C6" SG_ 1408 Kurzzeitmittelwert 1408;
BA_ "GenSigAutoGenDsp" SG_ 1408 Max_Drehmoment_2550Nm 0;
BA_ "GenSigAutoGenSnd" SG_ 1408 Max_Drehmoment_2550Nm 0;
BA_ "GenSigSendType" SG_ 1408 Max_Drehmoment_2550Nm 7;
BA_ "NWM-WakeupAllowed" SG_ 1408 Max_Drehmoment_2550Nm 0;
BA_ "GenSigTimeoutMsg_Gateway_C6" SG_ 1408 Max_Drehmoment_2550Nm 1408;
BA_ "GenSigTimeoutMsg_Gateway_C6" SG_ 1408 Max_Drehmoment_2550Nm 1408;
BA_ "GenSigAutoGenDsp" SG_ 1408 Maximum_Offset 0;
BA_ "GenSigAutoGenSnd" SG_ 1408 Maximum_Offset 0;
BA_ "GenSigSendType" SG_ 1408 Maximum_Offset 7;
BA_ "NWM-WakeupAllowed" SG_ 1408 Maximum_Offset 0;
BA_ "GenSigTimeoutMsg_Gateway_C6" SG_ 1408 Maximum_Offset 1408;
BA_ "GenSigAutoGenDsp" SG_ 1408 Motorleistung 0;
BA_ "GenSigAutoGenSnd" SG_ 1408 Motorleistung 0;
BA_ "GenSigSendType" SG_ 1408 Motorleistung 7;
BA_ "NWM-WakeupAllowed" SG_ 1408 Motorleistung 0;
BA_ "GenSigTimeoutMsg_ESP8_C6" SG_ 1408 Motorleistung 1408;
BA_ "GenSigTimeoutMsg_Gateway_C6" SG_ 1408 Motorleistung 1408;
BA_ "GenSigTimeoutMsg_Gateway_C6" SG_ 1408 Motorleistung 1408;
BA_ "GenSigAutoGenDsp" SG_ 1408 Mux_Code_MFn 0;
BA_ "GenSigAutoGenSnd" SG_ 1408 Mux_Code_MFn 0;
BA_ "GenSigSendType" SG_ 1408 Mux_Code_MFn 7;
BA_ "NWM-WakeupAllowed" SG_ 1408 Mux_Code_MFn 0;
BA_ "GenSigTimeoutMsg_Gateway_C6" SG_ 1408 Mux_Code_MFn 1408;
BA_ "GenSigAutoGenDsp" SG_ 1408 Normed_Trip 1;
BA_ "GenSigAutoGenSnd" SG_ 1408 Normed_Trip 1;
BA_ "GenSigSendType" SG_ 1408 Normed_Trip 7;
BA_ "NWM-WakeupAllowed" SG_ 1408 Normed_Trip 0;
BA_ "GenSigTimeoutMsg_Gateway_C6" SG_ 1408 Normed_Trip 1408;
BA_ "GenSigAutoGenDsp" SG_ 1408 Oelstandszaehler 0;
BA_ "GenSigAutoGenSnd" SG_ 1408 Oelstandszaehler 0;
BA_ "GenSigSendType" SG_ 1408 Oelstandszaehler 7;
BA_ "NWM-WakeupAllowed" SG_ 1408 Oelstandszaehler 0;
BA_ "GenSigTimeoutMsg_Gateway_C6" SG_ 1408 Oelstandszaehler 1408;
BA_ "GenSigAutoGenDsp" SG_ 1408 Oelwarnschwellen_Offset 0;
BA_ "GenSigAutoGenSnd" SG_ 1408 Oelwarnschwellen_Offset 0;
BA_ "GenSigSendType" SG_ 1408 Oelwarnschwellen_Offset 7;
BA_ "NWM-WakeupAllowed" SG_ 1408 Oelwarnschwellen_Offset 0;
BA_ "GenSigTimeoutMsg_Gateway_C6" SG_ 1408 Oelwarnschwellen_Offset 1408;
BA_ "GenSigAutoGenDsp" SG_ 1408 Oelwarnschwellen_Toleranz 0;
BA_ "GenSigAutoGenSnd" SG_ 1408 Oelwarnschwellen_Toleranz 0;
BA_ "GenSigSendType" SG_ 1408 Oelwarnschwellen_Toleranz 7;
BA_ "NWM-WakeupAllowed" SG_ 1408 Oelwarnschwellen_Toleranz 0;
BA_ "GenSigTimeoutMsg_Gateway_C6" SG_ 1408 Oelwarnschwellen_Toleranz 1408;
BA_ "GenSigAutoGenDsp" SG_ 1408 Oelwarnung 0;
BA_ "GenSigAutoGenSnd" SG_ 1408 Oelwarnung 0;
BA_ "GenSigSendType" SG_ 1408 Oelwarnung 7;
BA_ "NWM-WakeupAllowed" SG_ 1408 Oelwarnung 0;
BA_ "GenSigTimeoutMsg_Gateway_C6" SG_ 1408 Oelwarnung 1408;
BA_ "GenSigAutoGenDsp" SG_ 1408 Russaequivalent 0;
BA_ "GenSigAutoGenSnd" SG_ 1408 Russaequivalent 0;
BA_ "GenSigSendType" SG_ 1408 Russaequivalent 7;
BA_ "NWM-WakeupAllowed" SG_ 1408 Russaequivalent 0;
BA_ "GenSigTimeoutMsg_Gateway_C6" SG_ 1408 Russaequivalent 1408;
BA_ "GenSigTimeoutMsg_Gateway_C6" SG_ 1408 Russaequivalent 1408;
BA_ "GenSigAutoGenDsp" SG_ 1408 Schwellwert_Max_Oelstand 0;
BA_ "GenSigAutoGenSnd" SG_ 1408 Schwellwert_Max_Oelstand 0;
BA_ "GenSigSendType" SG_ 1408 Schwellwert_Max_Oelstand 7;
BA_ "NWM-WakeupAllowed" SG_ 1408 Schwellwert_Max_Oelstand 0;
BA_ "GenSigTimeoutMsg_Gateway_C6" SG_ 1408 Schwellwert_Max_Oelstand 1408;
BA_ "GenSigAutoGenDsp" SG_ 1408 Sensorwarnung 0;
BA_ "GenSigAutoGenSnd" SG_ 1408 Sensorwarnung 0;
BA_ "GenSigSendType" SG_ 1408 Sensorwarnung 7;
BA_ "NWM-WakeupAllowed" SG_ 1408 Sensorwarnung 0;
BA_ "GenSigTimeoutMsg_Gateway_C6" SG_ 1408 Sensorwarnung 1408;
BA_ "GenSigAutoGenDsp" SG_ 1408 Strecke_Mittelung 0;
BA_ "GenSigAutoGenSnd" SG_ 1408 Strecke_Mittelung 0;
BA_ "GenSigSendType" SG_ 1408 Strecke_Mittelung 7;
BA_ "NWM-WakeupAllowed" SG_ 1408 Strecke_Mittelung 0;
BA_ "GenSigTimeoutMsg_Gateway_C6" SG_ 1408 Strecke_Mittelung 1408;
BA_ "GenSigAutoGenDsp" SG_ 1408 Ueberfuell_Hysterese 0;
BA_ "GenSigAutoGenSnd" SG_ 1408 Ueberfuell_Hysterese 0;
BA_ "GenSigSendType" SG_ 1408 Ueberfuell_Hysterese 7;
BA_ "NWM-WakeupAllowed" SG_ 1408 Ueberfuell_Hysterese 0;
BA_ "GenSigTimeoutMsg_Gateway_C6" SG_ 1408 Ueberfuell_Hysterese 1408;
BA_ "GenSigAutoGenDsp" SG_ 1408 Ueberfuellerkennung_aktiv 0;
BA_ "GenSigAutoGenSnd" SG_ 1408 Ueberfuellerkennung_aktiv 0;
BA_ "GenSigSendType" SG_ 1408 Ueberfuellerkennung_aktiv 7;
BA_ "NWM-WakeupAllowed" SG_ 1408 Ueberfuellerkennung_aktiv 0;
BA_ "GenSigTimeoutMsg_Gateway_C6" SG_ 1408 Ueberfuellerkennung_aktiv 1408;
BA_ "GenSigAutoGenDsp" SG_ 1408 Verbrennungsart 0;
BA_ "GenSigAutoGenSnd" SG_ 1408 Verbrennungsart 0;
BA_ "GenSigSendType" SG_ 1408 Verbrennungsart 7;
BA_ "NWM-WakeupAllowed" SG_ 1408 Verbrennungsart 0;
BA_ "GenSigTimeoutMsg_ESP8_C6" SG_ 1408 Verbrennungsart 1408;
BA_ "GenSigTimeoutMsg_Gateway_C6" SG_ 1408 Verbrennungsart 1408;
BA_ "GenSigAutoGenDsp" SG_ 1408 Verschleissequivalent 0;
BA_ "GenSigAutoGenSnd" SG_ 1408 Verschleissequivalent 0;
BA_ "GenSigSendType" SG_ 1408 Verschleissequivalent 7;
BA_ "NWM-WakeupAllowed" SG_ 1408 Verschleissequivalent 0;
BA_ "GenSigTimeoutMsg_Gateway_C6" SG_ 1408 Verschleissequivalent 1408;
BA_ "GenSigTimeoutMsg_Gateway_C6" SG_ 1408 Verschleissequivalent 1408;
BA_ "GenSigAutoGenDsp" SG_ 1408 Warm_Up_Cycle 0;
BA_ "GenSigAutoGenSnd" SG_ 1408 Warm_Up_Cycle 0;
BA_ "GenSigSendType" SG_ 1408 Warm_Up_Cycle 7;
BA_ "NWM-WakeupAllowed" SG_ 1408 Warm_Up_Cycle 0;
BA_ "GenSigTimeoutMsg__6HP_C6" SG_ 1408 Warm_Up_Cycle 1408;
BA_ "GenSigTimeoutMsg_Gateway_C6" SG_ 1408 Warm_Up_Cycle 1408;
BA_ "GenSigAutoGenDsp" SG_ 1823 FSPE_Motorslave 0;
BA_ "GenSigAutoGenSnd" SG_ 1823 FSPE_Motorslave 0;
BA_ "GenSigSendType" SG_ 1823 FSPE_Motorslave 7;
BA_ "NWM-WakeupAllowed" SG_ 1823 FSPE_Motorslave 0;
BA_ "GenSigTimeoutMsg_Gateway_C6" SG_ 1823 FSPE_Motorslave 1823;
BA_ "GenSigAutoGenDsp" SG_ 1424 Absenkung_Fahrzeug 0;
BA_ "GenSigAutoGenSnd" SG_ 1424 Absenkung_Fahrzeug 0;
BA_ "GenSigSendType" SG_ 1424 Absenkung_Fahrzeug 7;
BA_ "NWM-WakeupAllowed" SG_ 1424 Absenkung_Fahrzeug 0;
BA_ "GenSigTimeoutMsg_Gateway_C6" SG_ 1424 Absenkung_Fahrzeug 1424;
BA_ "GenSigTimeoutMsg_LWR_AFS_C6" SG_ 1424 Absenkung_Fahrzeug 1424;
BA_ "GenSigAutoGenDsp" SG_ 1424 Anhebung_Fahrzeug 0;
BA_ "GenSigAutoGenSnd" SG_ 1424 Anhebung_Fahrzeug 0;
BA_ "GenSigSendType" SG_ 1424 Anhebung_Fahrzeug 7;
BA_ "NWM-WakeupAllowed" SG_ 1424 Anhebung_Fahrzeug 0;
BA_ "GenSigTimeoutMsg_Gateway_C6" SG_ 1424 Anhebung_Fahrzeug 1424;
BA_ "GenSigTimeoutMsg_LWR_AFS_C6" SG_ 1424 Anhebung_Fahrzeug 1424;
BA_ "GenSigAutoGenDsp" SG_ 1424 Aufpruefbit_Warnlampe_Niveau 0;
BA_ "GenSigAutoGenSnd" SG_ 1424 Aufpruefbit_Warnlampe_Niveau 0;
BA_ "GenSigSendType" SG_ 1424 Aufpruefbit_Warnlampe_Niveau 7;
BA_ "NWM-WakeupAllowed" SG_ 1424 Aufpruefbit_Warnlampe_Niveau 0;
BA_ "GenSigTimeoutMsg_Gateway_C6" SG_ 1424 Aufpruefbit_Warnlampe_Niveau 1424;
BA_ "GenSigAutoGenDsp" SG_ 1424 Beladungszustand 0;
BA_ "GenSigAutoGenSnd" SG_ 1424 Beladungszustand 0;
BA_ "GenSigSendType" SG_ 1424 Beladungszustand 7;
BA_ "GenSigStartValue" SG_ 1424 Beladungszustand 254;
BA_ "NWM-WakeupAllowed" SG_ 1424 Beladungszustand 0;
BA_ "GenSigTimeoutMsg_Gateway_C6" SG_ 1424 Beladungszustand 1424;
BA_ "GenSigAutoGenDsp" SG_ 1424 BZ_Niveau1 0;
BA_ "GenSigAutoGenSnd" SG_ 1424 BZ_Niveau1 0;
BA_ "GenSigSendType" SG_ 1424 BZ_Niveau1 7;
BA_ "NWM-WakeupAllowed" SG_ 1424 BZ_Niveau1 0;
BA_ "GenSigTimeoutMsg_ESP8_C6" SG_ 1424 BZ_Niveau1 1424;
BA_ "GenSigTimeoutMsg_Gateway_C6" SG_ 1424 BZ_Niveau1 1424;
BA_ "GenSigAutoGenDsp" SG_ 1424 CHK_Niveau1 0;
BA_ "GenSigAutoGenSnd" SG_ 1424 CHK_Niveau1 0;
BA_ "GenSigSendType" SG_ 1424 CHK_Niveau1 7;
BA_ "NWM-WakeupAllowed" SG_ 1424 CHK_Niveau1 0;
BA_ "GenSigTimeoutMsg_ESP8_C6" SG_ 1424 CHK_Niveau1 1424;
BA_ "GenSigTimeoutMsg_Gateway_C6" SG_ 1424 CHK_Niveau1 1424;
BA_ "GenSigAutoGenDsp" SG_ 1424 ESP_Beeinflussung 0;
BA_ "GenSigAutoGenSnd" SG_ 1424 ESP_Beeinflussung 0;
BA_ "GenSigSendType" SG_ 1424 ESP_Beeinflussung 7;
BA_ "NWM-WakeupAllowed" SG_ 1424 ESP_Beeinflussung 0;
BA_ "GenSigTimeoutMsg_ESP8_C6" SG_ 1424 ESP_Beeinflussung 1424;
BA_ "GenSigTimeoutMsg_Gateway_C6" SG_ 1424 ESP_Beeinflussung 1424;
BA_ "GenSigAutoGenDsp" SG_ 1424 Fahrzeugart_Niveau 0;
BA_ "GenSigAutoGenSnd" SG_ 1424 Fahrzeugart_Niveau 0;
BA_ "GenSigSendType" SG_ 1424 Fahrzeugart_Niveau 7;
BA_ "NWM-WakeupAllowed" SG_ 1424 Fahrzeugart_Niveau 0;
BA_ "GenSigTimeoutMsg_Gateway_C6" SG_ 1424 Fahrzeugart_Niveau 1424;
BA_ "GenSigAutoGenDsp" SG_ 1424 Fehlerlampe_Niveau 0;
BA_ "GenSigAutoGenSnd" SG_ 1424 Fehlerlampe_Niveau 0;
BA_ "GenSigSendType" SG_ 1424 Fehlerlampe_Niveau 7;
BA_ "NWM-WakeupAllowed" SG_ 1424 Fehlerlampe_Niveau 0;
BA_ "GenSigTimeoutMsg_Gateway_C6" SG_ 1424 Fehlerlampe_Niveau 1424;
BA_ "GenSigAutoGenDsp" SG_ 1424 FSPE_Niveau1 0;
BA_ "GenSigAutoGenSnd" SG_ 1424 FSPE_Niveau1 0;
BA_ "GenSigSendType" SG_ 1424 FSPE_Niveau1 7;
BA_ "NWM-WakeupAllowed" SG_ 1424 FSPE_Niveau1 0;
BA_ "GenSigTimeoutMsg_Gateway_C6" SG_ 1424 FSPE_Niveau1 1424;
BA_ "GenSigAutoGenDsp" SG_ 1424 Kompressor_laeuft 0;
BA_ "GenSigAutoGenSnd" SG_ 1424 Kompressor_laeuft 0;
BA_ "GenSigSendType" SG_ 1424 Kompressor_laeuft 7;
BA_ "NWM-WakeupAllowed" SG_ 1424 Kompressor_laeuft 0;
BA_ "GenSigTimeoutMsg_Gateway_C6" SG_ 1424 Kompressor_laeuft 1424;
BA_ "GenSigAutoGenDsp" SG_ 1424 Kompressorlauf_in_Kuerze 0;
BA_ "GenSigAutoGenSnd" SG_ 1424 Kompressorlauf_in_Kuerze 0;
BA_ "GenSigSendType" SG_ 1424 Kompressorlauf_in_Kuerze 7;
BA_ "NWM-WakeupAllowed" SG_ 1424 Kompressorlauf_in_Kuerze 0;
BA_ "GenSigTimeoutMsg_Gateway_C6" SG_ 1424 Kompressorlauf_in_Kuerze 1424;
BA_ "GenSigAutoGenDsp" SG_ 1424 MSG_Einschraenkung 0;
BA_ "GenSigAutoGenSnd" SG_ 1424 MSG_Einschraenkung 0;
BA_ "GenSigSendType" SG_ 1424 MSG_Einschraenkung 7;
BA_ "NWM-WakeupAllowed" SG_ 1424 MSG_Einschraenkung 0;
BA_ "GenSigTimeoutMsg_Gateway_C6" SG_ 1424 MSG_Einschraenkung 1424;
BA_ "GenSigAutoGenDsp" SG_ 1424 Niveaustati 0;
BA_ "GenSigAutoGenSnd" SG_ 1424 Niveaustati 0;
BA_ "GenSigSendType" SG_ 1424 Niveaustati 7;
BA_ "NWM-WakeupAllowed" SG_ 1424 Niveaustati 0;
BA_ "GenSigTimeoutMsg_Gateway_C6" SG_ 1424 Niveaustati 1424;
BA_ "GenSigAutoGenDsp" SG_ 1424 Parkniveau 0;
BA_ "GenSigAutoGenSnd" SG_ 1424 Parkniveau 0;
BA_ "GenSigSendType" SG_ 1424 Parkniveau 7;
BA_ "NWM-WakeupAllowed" SG_ 1424 Parkniveau 0;
BA_ "GenSigTimeoutMsg_Gateway_C6" SG_ 1424 Parkniveau 1424;
BA_ "GenSigAutoGenDsp" SG_ 1424 SIB_Niveau 0;
BA_ "GenSigAutoGenSnd" SG_ 1424 SIB_Niveau 0;
BA_ "GenSigSendType" SG_ 1424 SIB_Niveau 7;
BA_ "NWM-WakeupAllowed" SG_ 1424 SIB_Niveau 0;
BA_ "GenSigTimeoutMsg_Gateway_C6" SG_ 1424 SIB_Niveau 1424;
BA_ "GenSigAutoGenDsp" SG_ 1424 Stromaufnahme 0;
BA_ "GenSigAutoGenSnd" SG_ 1424 Stromaufnahme 0;
BA_ "GenSigSendType" SG_ 1424 Stromaufnahme 7;
BA_ "GenSigStartValue" SG_ 1424 Stromaufnahme 254;
BA_ "NWM-WakeupAllowed" SG_ 1424 Stromaufnahme 0;
BA_ "GenSigTimeoutMsg_Gateway_C6" SG_ 1424 Stromaufnahme 1424;
BA_ "GenSigAutoGenDsp" SG_ 1424 Systemstatus 0;
BA_ "GenSigAutoGenSnd" SG_ 1424 Systemstatus 0;
BA_ "GenSigSendType" SG_ 1424 Systemstatus 7;
BA_ "NWM-WakeupAllowed" SG_ 1424 Systemstatus 0;
BA_ "GenSigTimeoutMsg_Gateway_C6" SG_ 1424 Systemstatus 1424;
BA_ "GenSigAutoGenDsp" SG_ 1424 Taster_Niveau 0;
BA_ "GenSigAutoGenSnd" SG_ 1424 Taster_Niveau 0;
BA_ "GenSigSendType" SG_ 1424 Taster_Niveau 7;
BA_ "NWM-WakeupAllowed" SG_ 1424 Taster_Niveau 0;
BA_ "GenSigTimeoutMsg_Gateway_C6" SG_ 1424 Taster_Niveau 1424;
BA_ "GenSigAutoGenDsp" SG_ 1424 Textbits_Niveau 0;
BA_ "GenSigAutoGenSnd" SG_ 1424 Textbits_Niveau 0;
BA_ "GenSigSendType" SG_ 1424 Textbits_Niveau 7;
BA_ "NWM-WakeupAllowed" SG_ 1424 Textbits_Niveau 0;
BA_ "GenSigTimeoutMsg_Gateway_C6" SG_ 1424 Textbits_Niveau 1424;
BA_ "GenSigAutoGenDsp" SG_ 1424 Tiefniveaulampe 0;
BA_ "GenSigAutoGenSnd" SG_ 1424 Tiefniveaulampe 0;
BA_ "GenSigSendType" SG_ 1424 Tiefniveaulampe 7;
BA_ "NWM-WakeupAllowed" SG_ 1424 Tiefniveaulampe 0;
BA_ "GenSigTimeoutMsg_Gateway_C6" SG_ 1424 Tiefniveaulampe 1424;
BA_ "GenSigAutoGenDsp" SG_ 1424 Verstellung_aktiv 0;
BA_ "GenSigAutoGenSnd" SG_ 1424 Verstellung_aktiv 0;
BA_ "GenSigSendType" SG_ 1424 Verstellung_aktiv 7;
BA_ "NWM-WakeupAllowed" SG_ 1424 Verstellung_aktiv 0;
BA_ "GenSigTimeoutMsg_Gateway_C6" SG_ 1424 Verstellung_aktiv 1424;
BA_ "GenSigAutoGenDsp" SG_ 1424 Verstellung_HL 0;
BA_ "GenSigAutoGenSnd" SG_ 1424 Verstellung_HL 0;
BA_ "GenSigSendType" SG_ 1424 Verstellung_HL 7;
BA_ "NWM-WakeupAllowed" SG_ 1424 Verstellung_HL 0;
BA_ "GenSigTimeoutMsg_Gateway_C6" SG_ 1424 Verstellung_HL 1424;
BA_ "GenSigAutoGenDsp" SG_ 1424 Verstellung_HR 0;
BA_ "GenSigAutoGenSnd" SG_ 1424 Verstellung_HR 0;
BA_ "GenSigSendType" SG_ 1424 Verstellung_HR 7;
BA_ "NWM-WakeupAllowed" SG_ 1424 Verstellung_HR 0;
BA_ "GenSigTimeoutMsg_Gateway_C6" SG_ 1424 Verstellung_HR 1424;
BA_ "GenSigAutoGenDsp" SG_ 1424 Verstellung_in_Kuerze 0;
BA_ "GenSigAutoGenSnd" SG_ 1424 Verstellung_in_Kuerze 0;
BA_ "GenSigSendType" SG_ 1424 Verstellung_in_Kuerze 7;
BA_ "NWM-WakeupAllowed" SG_ 1424 Verstellung_in_Kuerze 0;
BA_ "GenSigTimeoutMsg_Gateway_C6" SG_ 1424 Verstellung_in_Kuerze 1424;
BA_ "GenSigAutoGenDsp" SG_ 1424 Verstellung_VL 0;
BA_ "GenSigAutoGenSnd" SG_ 1424 Verstellung_VL 0;
BA_ "GenSigSendType" SG_ 1424 Verstellung_VL 7;
BA_ "NWM-WakeupAllowed" SG_ 1424 Verstellung_VL 0;
BA_ "GenSigTimeoutMsg_Gateway_C6" SG_ 1424 Verstellung_VL 1424;
BA_ "GenSigAutoGenDsp" SG_ 1424 Verstellung_VR 0;
BA_ "GenSigAutoGenSnd" SG_ 1424 Verstellung_VR 0;
BA_ "GenSigSendType" SG_ 1424 Verstellung_VR 7;
BA_ "NWM-WakeupAllowed" SG_ 1424 Verstellung_VR 0;
BA_ "GenSigTimeoutMsg_Gateway_C6" SG_ 1424 Verstellung_VR 1424;
BA_ "GenSigAutoGenDsp" SG_ 1424 Warnlampe 0;
BA_ "GenSigAutoGenSnd" SG_ 1424 Warnlampe 0;
BA_ "GenSigSendType" SG_ 1424 Warnlampe 7;
BA_ "NWM-WakeupAllowed" SG_ 1424 Warnlampe 0;
BA_ "GenSigTimeoutMsg_Gateway_C6" SG_ 1424 Warnlampe 1424;
BA_ "GenSigAutoGenDsp" SG_ 1424 Zwischenniveau 0;
BA_ "GenSigAutoGenSnd" SG_ 1424 Zwischenniveau 0;
BA_ "GenSigSendType" SG_ 1424 Zwischenniveau 7;
BA_ "NWM-WakeupAllowed" SG_ 1424 Zwischenniveau 0;
BA_ "GenSigTimeoutMsg_Gateway_C6" SG_ 1424 Zwischenniveau 1424;
BA_ "GenSigAutoGenDsp" SG_ 1428 BZ_Niveau2 0;
BA_ "GenSigAutoGenSnd" SG_ 1428 BZ_Niveau2 0;
BA_ "GenSigSendType" SG_ 1428 BZ_Niveau2 7;
BA_ "NWM-WakeupAllowed" SG_ 1428 BZ_Niveau2 0;
BA_ "GenSigAutoGenDsp" SG_ 1428 CHK_Niveau2 0;
BA_ "GenSigAutoGenSnd" SG_ 1428 CHK_Niveau2 0;
BA_ "GenSigSendType" SG_ 1428 CHK_Niveau2 7;
BA_ "NWM-WakeupAllowed" SG_ 1428 CHK_Niveau2 0;
BA_ "GenSigAutoGenDsp" SG_ 1428 Hoehenwert_HL 0;
BA_ "GenSigAutoGenSnd" SG_ 1428 Hoehenwert_HL 0;
BA_ "GenSigSendType" SG_ 1428 Hoehenwert_HL 7;
BA_ "GenSigStartValue" SG_ 1428 Hoehenwert_HL 254;
BA_ "NWM-WakeupAllowed" SG_ 1428 Hoehenwert_HL 0;
BA_ "GenSigTimeoutMsg__6HP_C6" SG_ 1428 Hoehenwert_HL 1428;
BA_ "GenSigTimeoutMsg_LWR_AFS_C6" SG_ 1428 Hoehenwert_HL 1428;
BA_ "GenSigAutoGenDsp" SG_ 1428 Hoehenwert_HR 0;
BA_ "GenSigAutoGenSnd" SG_ 1428 Hoehenwert_HR 0;
BA_ "GenSigSendType" SG_ 1428 Hoehenwert_HR 7;
BA_ "GenSigStartValue" SG_ 1428 Hoehenwert_HR 254;
BA_ "NWM-WakeupAllowed" SG_ 1428 Hoehenwert_HR 0;
BA_ "GenSigTimeoutMsg__6HP_C6" SG_ 1428 Hoehenwert_HR 1428;
BA_ "GenSigTimeoutMsg_LWR_AFS_C6" SG_ 1428 Hoehenwert_HR 1428;
BA_ "GenSigAutoGenDsp" SG_ 1428 Hoehenwert_VL 0;
BA_ "GenSigAutoGenSnd" SG_ 1428 Hoehenwert_VL 0;
BA_ "GenSigSendType" SG_ 1428 Hoehenwert_VL 7;
BA_ "GenSigStartValue" SG_ 1428 Hoehenwert_VL 254;
BA_ "NWM-WakeupAllowed" SG_ 1428 Hoehenwert_VL 0;
BA_ "GenSigTimeoutMsg__6HP_C6" SG_ 1428 Hoehenwert_VL 1428;
BA_ "GenSigTimeoutMsg_LWR_AFS_C6" SG_ 1428 Hoehenwert_VL 1428;
BA_ "GenSigAutoGenDsp" SG_ 1428 Hoehenwert_VR 0;
BA_ "GenSigAutoGenSnd" SG_ 1428 Hoehenwert_VR 0;
BA_ "GenSigSendType" SG_ 1428 Hoehenwert_VR 7;
BA_ "GenSigStartValue" SG_ 1428 Hoehenwert_VR 254;
BA_ "NWM-WakeupAllowed" SG_ 1428 Hoehenwert_VR 0;
BA_ "GenSigTimeoutMsg__6HP_C6" SG_ 1428 Hoehenwert_VR 1428;
BA_ "GenSigTimeoutMsg_LWR_AFS_C6" SG_ 1428 Hoehenwert_VR 1428;
BA_ "GenSigAutoGenDsp" SG_ 1434 Anzeigebit10 1;
BA_ "GenSigAutoGenSnd" SG_ 1434 Anzeigebit10 1;
BA_ "GenSigSendType" SG_ 1434 Anzeigebit10 7;
BA_ "NWM-WakeupAllowed" SG_ 1434 Anzeigebit10 0;
BA_ "GenSigTimeoutMsg_Gateway_C6" SG_ 1434 Anzeigebit10 1434;
BA_ "GenSigAutoGenDsp" SG_ 1434 Anzeigebit17 1;
BA_ "GenSigAutoGenSnd" SG_ 1434 Anzeigebit17 1;
BA_ "GenSigSendType" SG_ 1434 Anzeigebit17 7;
BA_ "NWM-WakeupAllowed" SG_ 1434 Anzeigebit17 0;
BA_ "GenSigTimeoutMsg_Gateway_C6" SG_ 1434 Anzeigebit17 1434;
BA_ "GenSigAutoGenDsp" SG_ 1434 Anzeigebit18 1;
BA_ "GenSigAutoGenSnd" SG_ 1434 Anzeigebit18 1;
BA_ "GenSigSendType" SG_ 1434 Anzeigebit18 7;
BA_ "NWM-WakeupAllowed" SG_ 1434 Anzeigebit18 0;
BA_ "GenSigTimeoutMsg_Gateway_C6" SG_ 1434 Anzeigebit18 1434;
BA_ "GenSigAutoGenDsp" SG_ 1434 Anzeigebit19 1;
BA_ "GenSigAutoGenSnd" SG_ 1434 Anzeigebit19 1;
BA_ "GenSigSendType" SG_ 1434 Anzeigebit19 7;
BA_ "NWM-WakeupAllowed" SG_ 1434 Anzeigebit19 0;
BA_ "GenSigTimeoutMsg_Gateway_C6" SG_ 1434 Anzeigebit19 1434;
BA_ "GenSigAutoGenDsp" SG_ 1434 Anzeigebit20 1;
BA_ "GenSigAutoGenSnd" SG_ 1434 Anzeigebit20 1;
BA_ "GenSigSendType" SG_ 1434 Anzeigebit20 7;
BA_ "NWM-WakeupAllowed" SG_ 1434 Anzeigebit20 0;
BA_ "GenSigTimeoutMsg_Gateway_C6" SG_ 1434 Anzeigebit20 1434;
BA_ "GenSigAutoGenDsp" SG_ 1434 Anzeigebit21 1;
BA_ "GenSigAutoGenSnd" SG_ 1434 Anzeigebit21 1;
BA_ "GenSigSendType" SG_ 1434 Anzeigebit21 7;
BA_ "NWM-WakeupAllowed" SG_ 1434 Anzeigebit21 0;
BA_ "GenSigTimeoutMsg_Gateway_C6" SG_ 1434 Anzeigebit21 1434;
BA_ "GenSigAutoGenDsp" SG_ 1434 Anzeigebit22 1;
BA_ "GenSigAutoGenSnd" SG_ 1434 Anzeigebit22 1;
BA_ "GenSigSendType" SG_ 1434 Anzeigebit22 7;
BA_ "NWM-WakeupAllowed" SG_ 1434 Anzeigebit22 0;
BA_ "GenSigTimeoutMsg_Gateway_C6" SG_ 1434 Anzeigebit22 1434;
BA_ "GenSigAutoGenDsp" SG_ 1434 Anzeigebit23 1;
BA_ "GenSigAutoGenSnd" SG_ 1434 Anzeigebit23 1;
BA_ "GenSigSendType" SG_ 1434 Anzeigebit23 7;
BA_ "NWM-WakeupAllowed" SG_ 1434 Anzeigebit23 0;
BA_ "GenSigTimeoutMsg_Gateway_C6" SG_ 1434 Anzeigebit23 1434;
BA_ "GenSigAutoGenDsp" SG_ 1434 Anzeigebit24 1;
BA_ "GenSigAutoGenSnd" SG_ 1434 Anzeigebit24 1;
BA_ "GenSigSendType" SG_ 1434 Anzeigebit24 7;
BA_ "NWM-WakeupAllowed" SG_ 1434 Anzeigebit24 0;
BA_ "GenSigTimeoutMsg_Gateway_C6" SG_ 1434 Anzeigebit24 1434;
BA_ "GenSigAutoGenDsp" SG_ 1434 Anzeigebit25 1;
BA_ "GenSigAutoGenSnd" SG_ 1434 Anzeigebit25 1;
BA_ "GenSigSendType" SG_ 1434 Anzeigebit25 7;
BA_ "NWM-WakeupAllowed" SG_ 1434 Anzeigebit25 0;
BA_ "GenSigTimeoutMsg_Gateway_C6" SG_ 1434 Anzeigebit25 1434;
BA_ "GenSigAutoGenDsp" SG_ 1434 Anzeigebit26 1;
BA_ "GenSigAutoGenSnd" SG_ 1434 Anzeigebit26 1;
BA_ "GenSigSendType" SG_ 1434 Anzeigebit26 7;
BA_ "NWM-WakeupAllowed" SG_ 1434 Anzeigebit26 0;
BA_ "GenSigTimeoutMsg_Gateway_C6" SG_ 1434 Anzeigebit26 1434;
BA_ "GenSigAutoGenDsp" SG_ 1434 Anzeigebit9 1;
BA_ "GenSigAutoGenSnd" SG_ 1434 Anzeigebit9 1;
BA_ "GenSigSendType" SG_ 1434 Anzeigebit9 7;
BA_ "NWM-WakeupAllowed" SG_ 1434 Anzeigebit9 0;
BA_ "GenSigTimeoutMsg_Gateway_C6" SG_ 1434 Anzeigebit9 1434;
BA_ "GenSigAutoGenDsp" SG_ 1434 Priorisierung_FIS 1;
BA_ "GenSigAutoGenSnd" SG_ 1434 Priorisierung_FIS 1;
BA_ "GenSigSendType" SG_ 1434 Priorisierung_FIS 7;
BA_ "NWM-WakeupAllowed" SG_ 1434 Priorisierung_FIS 0;
BA_ "GenSigTimeoutMsg_Gateway_C6" SG_ 1434 Priorisierung_FIS 1434;
BA_ "GenSigAutoGenDsp" SG_ 1434 Textbit1 1;
BA_ "GenSigAutoGenSnd" SG_ 1434 Textbit1 1;
BA_ "GenSigSendType" SG_ 1434 Textbit1 7;
BA_ "NWM-WakeupAllowed" SG_ 1434 Textbit1 0;
BA_ "GenSigTimeoutMsg_Gateway_C6" SG_ 1434 Textbit1 1434;
BA_ "GenSigAutoGenDsp" SG_ 1434 Textbit2 1;
BA_ "GenSigAutoGenSnd" SG_ 1434 Textbit2 1;
BA_ "GenSigSendType" SG_ 1434 Textbit2 7;
BA_ "NWM-WakeupAllowed" SG_ 1434 Textbit2 0;
BA_ "GenSigTimeoutMsg_Gateway_C6" SG_ 1434 Textbit2 1434;
BA_ "GenSigAutoGenDsp" SG_ 1434 Textbit3 1;
BA_ "GenSigAutoGenSnd" SG_ 1434 Textbit3 1;
BA_ "GenSigSendType" SG_ 1434 Textbit3 7;
BA_ "NWM-WakeupAllowed" SG_ 1434 Textbit3 0;
BA_ "GenSigTimeoutMsg_Gateway_C6" SG_ 1434 Textbit3 1434;
BA_ "GenSigAutoGenDsp" SG_ 1434 Textbit4 1;
BA_ "GenSigAutoGenSnd" SG_ 1434 Textbit4 1;
BA_ "GenSigSendType" SG_ 1434 Textbit4 7;
BA_ "NWM-WakeupAllowed" SG_ 1434 Textbit4 0;
BA_ "GenSigTimeoutMsg_Gateway_C6" SG_ 1434 Textbit4 1434;
BA_ "GenSigAutoGenDsp" SG_ 1434 Verfuegbarkeit_FIS 1;
BA_ "GenSigAutoGenSnd" SG_ 1434 Verfuegbarkeit_FIS 1;
BA_ "GenSigSendType" SG_ 1434 Verfuegbarkeit_FIS 7;
BA_ "NWM-WakeupAllowed" SG_ 1434 Verfuegbarkeit_FIS 0;
BA_ "GenSigTimeoutMsg_Gateway_C6" SG_ 1434 Verfuegbarkeit_FIS 1434;
BA_ "GenSigAutoGenDsp" SG_ 2004 Aenderung_Innerorts 0;
BA_ "GenSigAutoGenSnd" SG_ 2004 Aenderung_Innerorts 0;
BA_ "GenSigSendType" SG_ 2004 Aenderung_Innerorts 7;
BA_ "NWM-WakeupAllowed" SG_ 2004 Aenderung_Innerorts 0;
BA_ "GenSigAutoGenDsp" SG_ 2004 Aenderung_Unterfuehrung 0;
BA_ "GenSigAutoGenSnd" SG_ 2004 Aenderung_Unterfuehrung 0;
BA_ "GenSigSendType" SG_ 2004 Aenderung_Unterfuehrung 7;
BA_ "NWM-WakeupAllowed" SG_ 2004 Aenderung_Unterfuehrung 0;
BA_ "GenSigAutoGenDsp" SG_ 2004 Alter_der_Daten 0;
BA_ "GenSigAutoGenSnd" SG_ 2004 Alter_der_Daten 0;
BA_ "GenSigSendType" SG_ 2004 Alter_der_Daten 7;
BA_ "GenSigStartValue" SG_ 2004 Alter_der_Daten 31;
BA_ "NWM-WakeupAllowed" SG_ 2004 Alter_der_Daten 0;
BA_ "GenSigAutoGenDsp" SG_ 2004 Bes_Geschw_klasse_1 0;
BA_ "GenSigAutoGenSnd" SG_ 2004 Bes_Geschw_klasse_1 0;
BA_ "GenSigSendType" SG_ 2004 Bes_Geschw_klasse_1 7;
BA_ "NWM-WakeupAllowed" SG_ 2004 Bes_Geschw_klasse_1 0;
BA_ "GenSigAutoGenDsp" SG_ 2004 Bes_Geschw_klasse_2 0;
BA_ "GenSigAutoGenSnd" SG_ 2004 Bes_Geschw_klasse_2 0;
BA_ "GenSigSendType" SG_ 2004 Bes_Geschw_klasse_2 7;
BA_ "NWM-WakeupAllowed" SG_ 2004 Bes_Geschw_klasse_2 0;
BA_ "GenSigAutoGenDsp" SG_ 2004 Bes_Geschw_klasse_3 0;
BA_ "GenSigAutoGenSnd" SG_ 2004 Bes_Geschw_klasse_3 0;
BA_ "GenSigSendType" SG_ 2004 Bes_Geschw_klasse_3 7;
BA_ "NWM-WakeupAllowed" SG_ 2004 Bes_Geschw_klasse_3 0;
BA_ "GenSigAutoGenDsp" SG_ 2004 Bes_Geschw_klasse_4 0;
BA_ "GenSigAutoGenSnd" SG_ 2004 Bes_Geschw_klasse_4 0;
BA_ "GenSigSendType" SG_ 2004 Bes_Geschw_klasse_4 7;
BA_ "NWM-WakeupAllowed" SG_ 2004 Bes_Geschw_klasse_4 0;
BA_ "GenSigAutoGenDsp" SG_ 2004 Bes_Geschw_klasse_5 0;
BA_ "GenSigAutoGenSnd" SG_ 2004 Bes_Geschw_klasse_5 0;
BA_ "GenSigSendType" SG_ 2004 Bes_Geschw_klasse_5 7;
BA_ "NWM-WakeupAllowed" SG_ 2004 Bes_Geschw_klasse_5 0;
BA_ "GenSigAutoGenDsp" SG_ 2004 Bes_Geschw_klasse_6 0;
BA_ "GenSigAutoGenSnd" SG_ 2004 Bes_Geschw_klasse_6 0;
BA_ "GenSigSendType" SG_ 2004 Bes_Geschw_klasse_6 7;
BA_ "NWM-WakeupAllowed" SG_ 2004 Bes_Geschw_klasse_6 0;
BA_ "GenSigAutoGenDsp" SG_ 2004 Digitalisierung 0;
BA_ "GenSigAutoGenSnd" SG_ 2004 Digitalisierung 0;
BA_ "GenSigSendType" SG_ 2004 Digitalisierung 7;
BA_ "NWM-WakeupAllowed" SG_ 2004 Digitalisierung 0;
BA_ "GenSigAutoGenDsp" SG_ 2004 Einbahnstrasse 0;
BA_ "GenSigAutoGenSnd" SG_ 2004 Einbahnstrasse 0;
BA_ "GenSigSendType" SG_ 2004 Einbahnstrasse 7;
BA_ "NWM-WakeupAllowed" SG_ 2004 Einbahnstrasse 0;
BA_ "GenSigAutoGenDsp" SG_ 2004 Einheit_Geschw_klasse 0;
BA_ "GenSigAutoGenSnd" SG_ 2004 Einheit_Geschw_klasse 0;
BA_ "GenSigSendType" SG_ 2004 Einheit_Geschw_klasse 7;
BA_ "NWM-WakeupAllowed" SG_ 2004 Einheit_Geschw_klasse 0;
BA_ "GenSigAutoGenDsp" SG_ 2004 Endkruemmung_1 0;
BA_ "GenSigAutoGenSnd" SG_ 2004 Endkruemmung_1 0;
BA_ "GenSigSendType" SG_ 2004 Endkruemmung_1 7;
BA_ "NWM-WakeupAllowed" SG_ 2004 Endkruemmung_1 0;
BA_ "GenSigAutoGenDsp" SG_ 2004 Endkruemmung_2 0;
BA_ "GenSigAutoGenSnd" SG_ 2004 Endkruemmung_2 0;
BA_ "GenSigSendType" SG_ 2004 Endkruemmung_2 7;
BA_ "NWM-WakeupAllowed" SG_ 2004 Endkruemmung_2 0;
BA_ "GenSigAutoGenDsp" SG_ 2004 Endkruemmung_3 0;
BA_ "GenSigAutoGenSnd" SG_ 2004 Endkruemmung_3 0;
BA_ "GenSigSendType" SG_ 2004 Endkruemmung_3 7;
BA_ "NWM-WakeupAllowed" SG_ 2004 Endkruemmung_3 0;
BA_ "GenSigAutoGenDsp" SG_ 2004 Endkruemmung_4 0;
BA_ "GenSigAutoGenSnd" SG_ 2004 Endkruemmung_4 0;
BA_ "GenSigSendType" SG_ 2004 Endkruemmung_4 7;
BA_ "NWM-WakeupAllowed" SG_ 2004 Endkruemmung_4 0;
BA_ "GenSigAutoGenDsp" SG_ 2004 Endkruemmung_5 0;
BA_ "GenSigAutoGenSnd" SG_ 2004 Endkruemmung_5 0;
BA_ "GenSigSendType" SG_ 2004 Endkruemmung_5 7;
BA_ "NWM-WakeupAllowed" SG_ 2004 Endkruemmung_5 0;
BA_ "GenSigAutoGenDsp" SG_ 2004 Endkruemmung_6 0;
BA_ "GenSigAutoGenSnd" SG_ 2004 Endkruemmung_6 0;
BA_ "GenSigSendType" SG_ 2004 Endkruemmung_6 7;
BA_ "NWM-WakeupAllowed" SG_ 2004 Endkruemmung_6 0;
BA_ "GenSigAutoGenDsp" SG_ 2004 Fahrspuren_in_Fahrtrichtung 0;
BA_ "GenSigAutoGenSnd" SG_ 2004 Fahrspuren_in_Fahrtrichtung 0;
BA_ "GenSigSendType" SG_ 2004 Fahrspuren_in_Fahrtrichtung 7;
BA_ "NWM-WakeupAllowed" SG_ 2004 Fahrspuren_in_Fahrtrichtung 0;
BA_ "GenSigAutoGenDsp" SG_ 2004 Geschwindigkeitsklasse_1 0;
BA_ "GenSigAutoGenSnd" SG_ 2004 Geschwindigkeitsklasse_1 0;
BA_ "GenSigSendType" SG_ 2004 Geschwindigkeitsklasse_1 7;
BA_ "NWM-WakeupAllowed" SG_ 2004 Geschwindigkeitsklasse_1 0;
BA_ "GenSigAutoGenDsp" SG_ 2004 Geschwindigkeitsklasse_2 0;
BA_ "GenSigAutoGenSnd" SG_ 2004 Geschwindigkeitsklasse_2 0;
BA_ "GenSigSendType" SG_ 2004 Geschwindigkeitsklasse_2 7;
BA_ "NWM-WakeupAllowed" SG_ 2004 Geschwindigkeitsklasse_2 0;
BA_ "GenSigAutoGenDsp" SG_ 2004 Geschwindigkeitsklasse_3 0;
BA_ "GenSigAutoGenSnd" SG_ 2004 Geschwindigkeitsklasse_3 0;
BA_ "GenSigSendType" SG_ 2004 Geschwindigkeitsklasse_3 7;
BA_ "NWM-WakeupAllowed" SG_ 2004 Geschwindigkeitsklasse_3 0;
BA_ "GenSigAutoGenDsp" SG_ 2004 Geschwindigkeitsklasse_4 0;
BA_ "GenSigAutoGenSnd" SG_ 2004 Geschwindigkeitsklasse_4 0;
BA_ "GenSigSendType" SG_ 2004 Geschwindigkeitsklasse_4 7;
BA_ "NWM-WakeupAllowed" SG_ 2004 Geschwindigkeitsklasse_4 0;
BA_ "GenSigAutoGenDsp" SG_ 2004 Geschwindigkeitsklasse_5 0;
BA_ "GenSigAutoGenSnd" SG_ 2004 Geschwindigkeitsklasse_5 0;
BA_ "GenSigSendType" SG_ 2004 Geschwindigkeitsklasse_5 7;
BA_ "NWM-WakeupAllowed" SG_ 2004 Geschwindigkeitsklasse_5 0;
BA_ "GenSigAutoGenDsp" SG_ 2004 Geschwindigkeitsklasse_6 0;
BA_ "GenSigAutoGenSnd" SG_ 2004 Geschwindigkeitsklasse_6 0;
BA_ "GenSigSendType" SG_ 2004 Geschwindigkeitsklasse_6 7;
BA_ "NWM-WakeupAllowed" SG_ 2004 Geschwindigkeitsklasse_6 0;
BA_ "GenSigAutoGenDsp" SG_ 2004 Kreuzung 0;
BA_ "GenSigAutoGenSnd" SG_ 2004 Kreuzung 0;
BA_ "GenSigSendType" SG_ 2004 Kreuzung 7;
BA_ "NWM-WakeupAllowed" SG_ 2004 Kreuzung 0;
BA_ "GenSigAutoGenDsp" SG_ 2004 Laengsfehler 0;
BA_ "GenSigAutoGenSnd" SG_ 2004 Laengsfehler 0;
BA_ "GenSigSendType" SG_ 2004 Laengsfehler 7;
BA_ "NWM-WakeupAllowed" SG_ 2004 Laengsfehler 0;
BA_ "GenSigAutoGenDsp" SG_ 2004 Mux_Code_PSD 0;
BA_ "GenSigAutoGenSnd" SG_ 2004 Mux_Code_PSD 0;
BA_ "GenSigSendType" SG_ 2004 Mux_Code_PSD 7;
BA_ "NWM-WakeupAllowed" SG_ 2004 Mux_Code_PSD 0;
BA_ "GenSigAutoGenDsp" SG_ 2004 Qualitaet 0;
BA_ "GenSigAutoGenSnd" SG_ 2004 Qualitaet 0;
BA_ "GenSigSendType" SG_ 2004 Qualitaet 7;
BA_ "NWM-WakeupAllowed" SG_ 2004 Qualitaet 0;
BA_ "GenSigAutoGenDsp" SG_ 2004 Segmentlaenge_1 0;
BA_ "GenSigAutoGenSnd" SG_ 2004 Segmentlaenge_1 0;
BA_ "GenSigSendType" SG_ 2004 Segmentlaenge_1 7;
BA_ "NWM-WakeupAllowed" SG_ 2004 Segmentlaenge_1 0;
BA_ "GenSigAutoGenDsp" SG_ 2004 Segmentlaenge_2 0;
BA_ "GenSigAutoGenSnd" SG_ 2004 Segmentlaenge_2 0;
BA_ "GenSigSendType" SG_ 2004 Segmentlaenge_2 7;
BA_ "NWM-WakeupAllowed" SG_ 2004 Segmentlaenge_2 0;
BA_ "GenSigAutoGenDsp" SG_ 2004 Segmentlaenge_3 0;
BA_ "GenSigAutoGenSnd" SG_ 2004 Segmentlaenge_3 0;
BA_ "GenSigSendType" SG_ 2004 Segmentlaenge_3 7;
BA_ "NWM-WakeupAllowed" SG_ 2004 Segmentlaenge_3 0;
BA_ "GenSigAutoGenDsp" SG_ 2004 Segmentlaenge_4 0;
BA_ "GenSigAutoGenSnd" SG_ 2004 Segmentlaenge_4 0;
BA_ "GenSigSendType" SG_ 2004 Segmentlaenge_4 7;
BA_ "NWM-WakeupAllowed" SG_ 2004 Segmentlaenge_4 0;
BA_ "GenSigAutoGenDsp" SG_ 2004 Segmentlaenge_5 0;
BA_ "GenSigAutoGenSnd" SG_ 2004 Segmentlaenge_5 0;
BA_ "GenSigSendType" SG_ 2004 Segmentlaenge_5 7;
BA_ "NWM-WakeupAllowed" SG_ 2004 Segmentlaenge_5 0;
BA_ "GenSigAutoGenDsp" SG_ 2004 Segmentlaenge_6 0;
BA_ "GenSigAutoGenSnd" SG_ 2004 Segmentlaenge_6 0;
BA_ "GenSigSendType" SG_ 2004 Segmentlaenge_6 7;
BA_ "NWM-WakeupAllowed" SG_ 2004 Segmentlaenge_6 0;
BA_ "GenSigAutoGenDsp" SG_ 2004 Signum_Endkruemmung_1 0;
BA_ "GenSigAutoGenSnd" SG_ 2004 Signum_Endkruemmung_1 0;
BA_ "GenSigSendType" SG_ 2004 Signum_Endkruemmung_1 7;
BA_ "NWM-WakeupAllowed" SG_ 2004 Signum_Endkruemmung_1 0;
BA_ "GenSigAutoGenDsp" SG_ 2004 Signum_Endkruemmung_2 0;
BA_ "GenSigAutoGenSnd" SG_ 2004 Signum_Endkruemmung_2 0;
BA_ "GenSigSendType" SG_ 2004 Signum_Endkruemmung_2 7;
BA_ "NWM-WakeupAllowed" SG_ 2004 Signum_Endkruemmung_2 0;
BA_ "GenSigAutoGenDsp" SG_ 2004 Signum_Endkruemmung_3 0;
BA_ "GenSigAutoGenSnd" SG_ 2004 Signum_Endkruemmung_3 0;
BA_ "GenSigSendType" SG_ 2004 Signum_Endkruemmung_3 7;
BA_ "NWM-WakeupAllowed" SG_ 2004 Signum_Endkruemmung_3 0;
BA_ "GenSigAutoGenDsp" SG_ 2004 Signum_Endkruemmung_4 0;
BA_ "GenSigAutoGenSnd" SG_ 2004 Signum_Endkruemmung_4 0;
BA_ "GenSigSendType" SG_ 2004 Signum_Endkruemmung_4 7;
BA_ "NWM-WakeupAllowed" SG_ 2004 Signum_Endkruemmung_4 0;
BA_ "GenSigAutoGenDsp" SG_ 2004 Signum_Endkruemmung_5 0;
BA_ "GenSigAutoGenSnd" SG_ 2004 Signum_Endkruemmung_5 0;
BA_ "GenSigSendType" SG_ 2004 Signum_Endkruemmung_5 7;
BA_ "NWM-WakeupAllowed" SG_ 2004 Signum_Endkruemmung_5 0;
BA_ "GenSigAutoGenDsp" SG_ 2004 Signum_Endkruemmung_6 0;
BA_ "GenSigAutoGenSnd" SG_ 2004 Signum_Endkruemmung_6 0;
BA_ "GenSigSendType" SG_ 2004 Signum_Endkruemmung_6 7;
BA_ "NWM-WakeupAllowed" SG_ 2004 Signum_Endkruemmung_6 0;
BA_ "GenSigAutoGenDsp" SG_ 2004 Signum_Startkruemmung_1 0;
BA_ "GenSigAutoGenSnd" SG_ 2004 Signum_Startkruemmung_1 0;
BA_ "GenSigSendType" SG_ 2004 Signum_Startkruemmung_1 7;
BA_ "NWM-WakeupAllowed" SG_ 2004 Signum_Startkruemmung_1 0;
BA_ "GenSigAutoGenDsp" SG_ 2004 Standort 0;
BA_ "GenSigAutoGenSnd" SG_ 2004 Standort 0;
BA_ "GenSigSendType" SG_ 2004 Standort 7;
BA_ "NWM-WakeupAllowed" SG_ 2004 Standort 0;
BA_ "GenSigAutoGenDsp" SG_ 2004 Startkruemmung_1 0;
BA_ "GenSigAutoGenSnd" SG_ 2004 Startkruemmung_1 0;
BA_ "GenSigSendType" SG_ 2004 Startkruemmung_1 7;
BA_ "NWM-WakeupAllowed" SG_ 2004 Startkruemmung_1 0;
BA_ "GenSigAutoGenDsp" SG_ 2004 Status_Innerorts 0;
BA_ "GenSigAutoGenSnd" SG_ 2004 Status_Innerorts 0;
BA_ "GenSigSendType" SG_ 2004 Status_Innerorts 7;
BA_ "NWM-WakeupAllowed" SG_ 2004 Status_Innerorts 0;
BA_ "GenSigAutoGenDsp" SG_ 2004 Status_Unterfuehrung 0;
BA_ "GenSigAutoGenSnd" SG_ 2004 Status_Unterfuehrung 0;
BA_ "GenSigSendType" SG_ 2004 Status_Unterfuehrung 7;
BA_ "NWM-WakeupAllowed" SG_ 2004 Status_Unterfuehrung 0;
BA_ "GenSigAutoGenDsp" SG_ 2004 Strassenklasse_1 0;
BA_ "GenSigAutoGenSnd" SG_ 2004 Strassenklasse_1 0;
BA_ "GenSigSendType" SG_ 2004 Strassenklasse_1 7;
BA_ "NWM-WakeupAllowed" SG_ 2004 Strassenklasse_1 0;
BA_ "GenSigAutoGenDsp" SG_ 2004 Strassenklasse_2 0;
BA_ "GenSigAutoGenSnd" SG_ 2004 Strassenklasse_2 0;
BA_ "GenSigSendType" SG_ 2004 Strassenklasse_2 7;
BA_ "NWM-WakeupAllowed" SG_ 2004 Strassenklasse_2 0;
BA_ "GenSigAutoGenDsp" SG_ 2004 Strassenklasse_3 0;
BA_ "GenSigAutoGenSnd" SG_ 2004 Strassenklasse_3 0;
BA_ "GenSigSendType" SG_ 2004 Strassenklasse_3 7;
BA_ "NWM-WakeupAllowed" SG_ 2004 Strassenklasse_3 0;
BA_ "GenSigAutoGenDsp" SG_ 2004 Strassenklasse_4 0;
BA_ "GenSigAutoGenSnd" SG_ 2004 Strassenklasse_4 0;
BA_ "GenSigSendType" SG_ 2004 Strassenklasse_4 7;
BA_ "NWM-WakeupAllowed" SG_ 2004 Strassenklasse_4 0;
BA_ "GenSigAutoGenDsp" SG_ 2004 Strassenklasse_5 0;
BA_ "GenSigAutoGenSnd" SG_ 2004 Strassenklasse_5 0;
BA_ "GenSigSendType" SG_ 2004 Strassenklasse_5 7;
BA_ "NWM-WakeupAllowed" SG_ 2004 Strassenklasse_5 0;
BA_ "GenSigAutoGenDsp" SG_ 2004 Strassenklasse_6 0;
BA_ "GenSigAutoGenSnd" SG_ 2004 Strassenklasse_6 0;
BA_ "GenSigSendType" SG_ 2004 Strassenklasse_6 7;
BA_ "NWM-WakeupAllowed" SG_ 2004 Strassenklasse_6 0;
BA_ "GenSigAutoGenDsp" SG_ 2004 Typ_besond_Geschw_klasse 0;
BA_ "GenSigAutoGenSnd" SG_ 2004 Typ_besond_Geschw_klasse 0;
BA_ "GenSigSendType" SG_ 2004 Typ_besond_Geschw_klasse 7;
BA_ "NWM-WakeupAllowed" SG_ 2004 Typ_besond_Geschw_klasse 0;
BA_ "GenSigAutoGenDsp" SG_ 2004 Verkehrsrichtung 0;
BA_ "GenSigAutoGenSnd" SG_ 2004 Verkehrsrichtung 0;
BA_ "GenSigSendType" SG_ 2004 Verkehrsrichtung 7;
BA_ "NWM-WakeupAllowed" SG_ 2004 Verkehrsrichtung 0;
BA_ "GenSigAutoGenDsp" SG_ 1306 BZ_TOG 0;
BA_ "GenSigAutoGenSnd" SG_ 1306 BZ_TOG 0;
BA_ "GenSigSendType" SG_ 1306 BZ_TOG 7;
BA_ "NWM-WakeupAllowed" SG_ 1306 BZ_TOG 0;
BA_ "GenSigTimeoutMsg_DME_EDC16CP3000" SG_ 1306 BZ_TOG 1306;
BA_ "GenSigTimeoutMsg_DME_ME7_MED9_C6" SG_ 1306 BZ_TOG 1306;
BA_ "GenSigTimeoutMsg_DME_SIMOS6_C6" SG_ 1306 BZ_TOG 1306;
BA_ "GenSigAutoGenDsp" SG_ 1306 Fuellstandszeit_1 0;
BA_ "GenSigAutoGenSnd" SG_ 1306 Fuellstandszeit_1 0;
BA_ "GenSigSendType" SG_ 1306 Fuellstandszeit_1 7;
BA_ "GenSigStartValue" SG_ 1306 Fuellstandszeit_1 1;
BA_ "NWM-WakeupAllowed" SG_ 1306 Fuellstandszeit_1 0;
BA_ "GenSigTimeoutMsg_DME_EDC16CP3000" SG_ 1306 Fuellstandszeit_1 1306;
BA_ "GenSigTimeoutMsg_DME_ME7_MED9_C6" SG_ 1306 Fuellstandszeit_1 1306;
BA_ "GenSigTimeoutMsg_DME_SIMOS6_C6" SG_ 1306 Fuellstandszeit_1 1306;
BA_ "GenSigAutoGenDsp" SG_ 1306 Fuellstandszeit_2 0;
BA_ "GenSigAutoGenSnd" SG_ 1306 Fuellstandszeit_2 0;
BA_ "GenSigSendType" SG_ 1306 Fuellstandszeit_2 7;
BA_ "GenSigStartValue" SG_ 1306 Fuellstandszeit_2 1;
BA_ "NWM-WakeupAllowed" SG_ 1306 Fuellstandszeit_2 0;
BA_ "GenSigTimeoutMsg_DME_EDC16CP3000" SG_ 1306 Fuellstandszeit_2 1306;
BA_ "GenSigTimeoutMsg_DME_ME7_MED9_C6" SG_ 1306 Fuellstandszeit_2 1306;
BA_ "GenSigTimeoutMsg_DME_SIMOS6_C6" SG_ 1306 Fuellstandszeit_2 1306;
BA_ "GenSigAutoGenDsp" SG_ 1306 Fuellstandszeit_3 0;
BA_ "GenSigAutoGenSnd" SG_ 1306 Fuellstandszeit_3 0;
BA_ "GenSigSendType" SG_ 1306 Fuellstandszeit_3 7;
BA_ "GenSigStartValue" SG_ 1306 Fuellstandszeit_3 1;
BA_ "NWM-WakeupAllowed" SG_ 1306 Fuellstandszeit_3 0;
BA_ "GenSigTimeoutMsg_DME_EDC16CP3000" SG_ 1306 Fuellstandszeit_3 1306;
BA_ "GenSigTimeoutMsg_DME_ME7_MED9_C6" SG_ 1306 Fuellstandszeit_3 1306;
BA_ "GenSigTimeoutMsg_DME_SIMOS6_C6" SG_ 1306 Fuellstandszeit_3 1306;
BA_ "GenSigAutoGenDsp" SG_ 1306 Fuellstandszeit_4 0;
BA_ "GenSigAutoGenSnd" SG_ 1306 Fuellstandszeit_4 0;
BA_ "GenSigSendType" SG_ 1306 Fuellstandszeit_4 7;
BA_ "GenSigStartValue" SG_ 1306 Fuellstandszeit_4 1;
BA_ "NWM-WakeupAllowed" SG_ 1306 Fuellstandszeit_4 0;
BA_ "GenSigTimeoutMsg_DME_EDC16CP3000" SG_ 1306 Fuellstandszeit_4 1306;
BA_ "GenSigTimeoutMsg_DME_ME7_MED9_C6" SG_ 1306 Fuellstandszeit_4 1306;
BA_ "GenSigTimeoutMsg_DME_SIMOS6_C6" SG_ 1306 Fuellstandszeit_4 1306;
BA_ "GenSigAutoGenDsp" SG_ 1306 Oelfuellstand_max 0;
BA_ "GenSigAutoGenSnd" SG_ 1306 Oelfuellstand_max 0;
BA_ "GenSigSendType" SG_ 1306 Oelfuellstand_max 7;
BA_ "NWM-WakeupAllowed" SG_ 1306 Oelfuellstand_max 0;
BA_ "GenSigTimeoutMsg_DME_EDC16CP3000" SG_ 1306 Oelfuellstand_max 1306;
BA_ "GenSigTimeoutMsg_DME_SIMOS6_C6" SG_ 1306 Oelfuellstand_max 1306;
BA_ "GenSigAutoGenDsp" SG_ 1306 Oelfuellstand_max_pO 0;
BA_ "GenSigAutoGenSnd" SG_ 1306 Oelfuellstand_max_pO 0;
BA_ "GenSigSendType" SG_ 1306 Oelfuellstand_max_pO 7;
BA_ "NWM-WakeupAllowed" SG_ 1306 Oelfuellstand_max_pO 0;
BA_ "GenSigTimeoutMsg_DME_EDC16CP3000" SG_ 1306 Oelfuellstand_max_pO 1306;
BA_ "GenSigTimeoutMsg_DME_SIMOS6_C6" SG_ 1306 Oelfuellstand_max_pO 1306;
BA_ "GenSigAutoGenDsp" SG_ 1306 Oeltemperaturzeit 0;
BA_ "GenSigAutoGenSnd" SG_ 1306 Oeltemperaturzeit 0;
BA_ "GenSigSendType" SG_ 1306 Oeltemperaturzeit 7;
BA_ "GenSigStartValue" SG_ 1306 Oeltemperaturzeit 1;
BA_ "NWM-WakeupAllowed" SG_ 1306 Oeltemperaturzeit 0;
BA_ "GenSigTimeoutMsg_DME_EDC16CP3000" SG_ 1306 Oeltemperaturzeit 1306;
BA_ "GenSigTimeoutMsg_DME_ME7_MED9_C6" SG_ 1306 Oeltemperaturzeit 1306;
BA_ "GenSigTimeoutMsg_DME_SIMOS6_C6" SG_ 1306 Oeltemperaturzeit 1306;
BA_ "GenSigAutoGenDsp" SG_ 1306 Oelwarnschwelle 0;
BA_ "GenSigAutoGenSnd" SG_ 1306 Oelwarnschwelle 0;
BA_ "GenSigSendType" SG_ 1306 Oelwarnschwelle 7;
BA_ "NWM-WakeupAllowed" SG_ 1306 Oelwarnschwelle 0;
BA_ "GenSigTimeoutMsg_DME_EDC16CP3000" SG_ 1306 Oelwarnschwelle 1306;
BA_ "GenSigTimeoutMsg_DME_ME7_MED9_C6" SG_ 1306 Oelwarnschwelle 1306;
BA_ "GenSigTimeoutMsg_DME_SIMOS6_C6" SG_ 1306 Oelwarnschwelle 1306;
BA_ "GenSigAutoGenDsp" SG_ 1306 Oelwarnschwelle_pOue 0;
BA_ "GenSigAutoGenSnd" SG_ 1306 Oelwarnschwelle_pOue 0;
BA_ "GenSigSendType" SG_ 1306 Oelwarnschwelle_pOue 7;
BA_ "NWM-WakeupAllowed" SG_ 1306 Oelwarnschwelle_pOue 0;
BA_ "GenSigTimeoutMsg_DME_EDC16CP3000" SG_ 1306 Oelwarnschwelle_pOue 1306;
BA_ "GenSigTimeoutMsg_DME_ME7_MED9_C6" SG_ 1306 Oelwarnschwelle_pOue 1306;
BA_ "GenSigTimeoutMsg_DME_SIMOS6_C6" SG_ 1306 Oelwarnschwelle_pOue 1306;
BA_ "GenSigAutoGenDsp" SG_ 1306 Sensorfehler 0;
BA_ "GenSigAutoGenSnd" SG_ 1306 Sensorfehler 0;
BA_ "GenSigSendType" SG_ 1306 Sensorfehler 7;
BA_ "NWM-WakeupAllowed" SG_ 1306 Sensorfehler 0;
BA_ "GenSigTimeoutMsg_DME_EDC16CP3000" SG_ 1306 Sensorfehler 1306;
BA_ "GenSigTimeoutMsg_DME_ME7_MED9_C6" SG_ 1306 Sensorfehler 1306;
BA_ "GenSigTimeoutMsg_DME_SIMOS6_C6" SG_ 1306 Sensorfehler 1306;
BA_ "GenSigAutoGenDsp" SG_ 1936 TP_dyn_Data 0;
BA_ "GenSigAutoGenSnd" SG_ 1936 TP_dyn_Data 0;
BA_ "GenSigSendType" SG_ 1936 TP_dyn_Data 7;
BA_ "NWM-WakeupAllowed" SG_ 1936 TP_dyn_Data 0;
BA_ "GenSigAutoGenDsp" SG_ 1937 TP_dyn_Data 0;
BA_ "GenSigAutoGenSnd" SG_ 1937 TP_dyn_Data 0;
BA_ "GenSigSendType" SG_ 1937 TP_dyn_Data 7;
BA_ "NWM-WakeupAllowed" SG_ 1937 TP_dyn_Data 0;
BA_ "GenSigAutoGenDsp" SG_ 1904 TP_dyn_Data 0;
BA_ "GenSigAutoGenSnd" SG_ 1904 TP_dyn_Data 0;
BA_ "GenSigSendType" SG_ 1904 TP_dyn_Data 7;
BA_ "NWM-WakeupAllowed" SG_ 1904 TP_dyn_Data 0;
BA_ "GenSigAutoGenDsp" SG_ 1905 TP_dyn_Data 0;
BA_ "GenSigAutoGenSnd" SG_ 1905 TP_dyn_Data 0;
BA_ "GenSigSendType" SG_ 1905 TP_dyn_Data 7;
BA_ "NWM-WakeupAllowed" SG_ 1905 TP_dyn_Data 0;
BA_ "GenSigAutoGenDsp" SG_ 1896 TP_dyn_Data 0;
BA_ "GenSigAutoGenSnd" SG_ 1896 TP_dyn_Data 0;
BA_ "GenSigSendType" SG_ 1896 TP_dyn_Data 7;
BA_ "NWM-WakeupAllowed" SG_ 1896 TP_dyn_Data 0;
BA_ "GenSigTimeoutMsg_Airbag_C6" SG_ 1896 TP_dyn_Data 1896;
BA_ "GenSigAutoGenDsp" SG_ 1897 TP_dyn_Data 0;
BA_ "GenSigAutoGenSnd" SG_ 1897 TP_dyn_Data 0;
BA_ "GenSigSendType" SG_ 1897 TP_dyn_Data 7;
BA_ "NWM-WakeupAllowed" SG_ 1897 TP_dyn_Data 0;
BA_ "GenSigTimeoutMsg_Airbag_C6" SG_ 1897 TP_dyn_Data 1897;
BA_ "GenSigAutoGenDsp" SG_ 822 TP_dyn_Data 0;
BA_ "GenSigAutoGenSnd" SG_ 822 TP_dyn_Data 0;
BA_ "GenSigSendType" SG_ 822 TP_dyn_Data 7;
BA_ "NWM-WakeupAllowed" SG_ 822 TP_dyn_Data 0;
BA_ "GenSigAutoGenDsp" SG_ 823 TP_dyn_Data 0;
BA_ "GenSigAutoGenSnd" SG_ 823 TP_dyn_Data 0;
BA_ "GenSigSendType" SG_ 823 TP_dyn_Data 7;
BA_ "NWM-WakeupAllowed" SG_ 823 TP_dyn_Data 0;
BA_ "GenSigAutoGenDsp" SG_ 812 TP_dyn_Data 0;
BA_ "GenSigAutoGenSnd" SG_ 812 TP_dyn_Data 0;
BA_ "GenSigSendType" SG_ 812 TP_dyn_Data 7;
BA_ "NWM-WakeupAllowed" SG_ 812 TP_dyn_Data 0;
BA_ "GenSigAutoGenDsp" SG_ 813 TP_dyn_Data 0;
BA_ "GenSigAutoGenSnd" SG_ 813 TP_dyn_Data 0;
BA_ "GenSigSendType" SG_ 813 TP_dyn_Data 7;
BA_ "NWM-WakeupAllowed" SG_ 813 TP_dyn_Data 0;
BA_ "GenSigAutoGenDsp" SG_ 1232 TP_dyn_Data 0;
BA_ "GenSigAutoGenSnd" SG_ 1232 TP_dyn_Data 0;
BA_ "GenSigSendType" SG_ 1232 TP_dyn_Data 7;
BA_ "NWM-WakeupAllowed" SG_ 1232 TP_dyn_Data 0;
BA_ "GenSigAutoGenDsp" SG_ 1233 TP_dyn_Data 0;
BA_ "GenSigAutoGenSnd" SG_ 1233 TP_dyn_Data 0;
BA_ "GenSigSendType" SG_ 1233 TP_dyn_Data 7;
BA_ "NWM-WakeupAllowed" SG_ 1233 TP_dyn_Data 0;
BA_ "GenSigAutoGenDsp" SG_ 1234 TP_dyn_Data 0;
BA_ "GenSigAutoGenSnd" SG_ 1234 TP_dyn_Data 0;
BA_ "GenSigSendType" SG_ 1234 TP_dyn_Data 7;
BA_ "NWM-WakeupAllowed" SG_ 1234 TP_dyn_Data 0;
BA_ "GenSigAutoGenDsp" SG_ 1235 TP_dyn_Data 0;
BA_ "GenSigAutoGenSnd" SG_ 1235 TP_dyn_Data 0;
BA_ "GenSigSendType" SG_ 1235 TP_dyn_Data 7;
BA_ "NWM-WakeupAllowed" SG_ 1235 TP_dyn_Data 0;
BA_ "GenSigAutoGenDsp" SG_ 1924 TP_dyn_Data 0;
BA_ "GenSigAutoGenSnd" SG_ 1924 TP_dyn_Data 0;
BA_ "GenSigSendType" SG_ 1924 TP_dyn_Data 7;
BA_ "NWM-WakeupAllowed" SG_ 1924 TP_dyn_Data 0;
BA_ "GenSigAutoGenDsp" SG_ 1925 TP_dyn_Data 0;
BA_ "GenSigAutoGenSnd" SG_ 1925 TP_dyn_Data 0;
BA_ "GenSigSendType" SG_ 1925 TP_dyn_Data 7;
BA_ "NWM-WakeupAllowed" SG_ 1925 TP_dyn_Data 0;
BA_ "GenSigAutoGenDsp" SG_ 818 TP_dyn_Data 0;
BA_ "GenSigAutoGenSnd" SG_ 818 TP_dyn_Data 0;
BA_ "GenSigSendType" SG_ 818 TP_dyn_Data 7;
BA_ "NWM-WakeupAllowed" SG_ 818 TP_dyn_Data 0;
BA_ "GenSigAutoGenDsp" SG_ 819 TP_dyn_Data 0;
BA_ "GenSigAutoGenSnd" SG_ 819 TP_dyn_Data 0;
BA_ "GenSigSendType" SG_ 819 TP_dyn_Data 7;
BA_ "NWM-WakeupAllowed" SG_ 819 TP_dyn_Data 0;
BA_ "GenSigAutoGenDsp" SG_ 1940 TP_dyn_Data 0;
BA_ "GenSigAutoGenSnd" SG_ 1940 TP_dyn_Data 0;
BA_ "GenSigSendType" SG_ 1940 TP_dyn_Data 7;
BA_ "NWM-WakeupAllowed" SG_ 1940 TP_dyn_Data 0;
BA_ "GenSigAutoGenDsp" SG_ 1941 TP_dyn_Data 0;
BA_ "GenSigAutoGenSnd" SG_ 1941 TP_dyn_Data 0;
BA_ "GenSigSendType" SG_ 1941 TP_dyn_Data 7;
BA_ "NWM-WakeupAllowed" SG_ 1941 TP_dyn_Data 0;
BA_ "GenSigAutoGenDsp" SG_ 816 TP_dyn_Data 0;
BA_ "GenSigAutoGenSnd" SG_ 816 TP_dyn_Data 0;
BA_ "GenSigSendType" SG_ 816 TP_dyn_Data 7;
BA_ "NWM-WakeupAllowed" SG_ 816 TP_dyn_Data 0;
BA_ "GenSigAutoGenDsp" SG_ 817 TP_dyn_Data 0;
BA_ "GenSigAutoGenSnd" SG_ 817 TP_dyn_Data 0;
BA_ "GenSigSendType" SG_ 817 TP_dyn_Data 7;
BA_ "NWM-WakeupAllowed" SG_ 817 TP_dyn_Data 0;
BA_ "GenSigAutoGenDsp" SG_ 762 TP_dyn_Data 0;
BA_ "GenSigAutoGenSnd" SG_ 762 TP_dyn_Data 0;
BA_ "GenSigSendType" SG_ 762 TP_dyn_Data 7;
BA_ "NWM-WakeupAllowed" SG_ 762 TP_dyn_Data 0;
BA_ "GenSigAutoGenDsp" SG_ 763 TP_dyn_Data 0;
BA_ "GenSigAutoGenSnd" SG_ 763 TP_dyn_Data 0;
BA_ "GenSigSendType" SG_ 763 TP_dyn_Data 7;
BA_ "NWM-WakeupAllowed" SG_ 763 TP_dyn_Data 0;
BA_ "GenSigAutoGenDsp" SG_ 814 TP_dyn_Data 0;
BA_ "GenSigAutoGenSnd" SG_ 814 TP_dyn_Data 0;
BA_ "GenSigSendType" SG_ 814 TP_dyn_Data 7;
BA_ "NWM-WakeupAllowed" SG_ 814 TP_dyn_Data 0;
BA_ "GenSigAutoGenDsp" SG_ 815 TP_dyn_Data 0;
BA_ "GenSigAutoGenSnd" SG_ 815 TP_dyn_Data 0;
BA_ "GenSigSendType" SG_ 815 TP_dyn_Data 7;
BA_ "NWM-WakeupAllowed" SG_ 815 TP_dyn_Data 0;
BA_ "GenSigAutoGenDsp" SG_ 1888 TP_dyn_Data 0;
BA_ "GenSigAutoGenSnd" SG_ 1888 TP_dyn_Data 0;
BA_ "GenSigSendType" SG_ 1888 TP_dyn_Data 7;
BA_ "NWM-WakeupAllowed" SG_ 1888 TP_dyn_Data 0;
BA_ "GenSigTimeoutMsg__6HP_C6" SG_ 1888 TP_dyn_Data 1888;
BA_ "GenSigAutoGenDsp" SG_ 1889 TP_dyn_Data 0;
BA_ "GenSigAutoGenSnd" SG_ 1889 TP_dyn_Data 0;
BA_ "GenSigSendType" SG_ 1889 TP_dyn_Data 7;
BA_ "NWM-WakeupAllowed" SG_ 1889 TP_dyn_Data 0;
BA_ "GenSigTimeoutMsg__6HP_C6" SG_ 1889 TP_dyn_Data 1889;
BA_ "GenSigAutoGenDsp" SG_ 756 TP_dyn_Data 0;
BA_ "GenSigAutoGenSnd" SG_ 756 TP_dyn_Data 0;
BA_ "GenSigSendType" SG_ 756 TP_dyn_Data 7;
BA_ "NWM-WakeupAllowed" SG_ 756 TP_dyn_Data 0;
BA_ "GenSigAutoGenDsp" SG_ 757 TP_dyn_Data 0;
BA_ "GenSigAutoGenSnd" SG_ 757 TP_dyn_Data 0;
BA_ "GenSigSendType" SG_ 757 TP_dyn_Data 7;
BA_ "NWM-WakeupAllowed" SG_ 757 TP_dyn_Data 0;
BA_ "GenSigAutoGenDsp" SG_ 808 TP_dyn_Data 0;
BA_ "GenSigAutoGenSnd" SG_ 808 TP_dyn_Data 0;
BA_ "GenSigSendType" SG_ 808 TP_dyn_Data 7;
BA_ "NWM-WakeupAllowed" SG_ 808 TP_dyn_Data 0;
BA_ "GenSigAutoGenDsp" SG_ 809 TP_dyn_Data 0;
BA_ "GenSigAutoGenSnd" SG_ 809 TP_dyn_Data 0;
BA_ "GenSigSendType" SG_ 809 TP_dyn_Data 7;
BA_ "NWM-WakeupAllowed" SG_ 809 TP_dyn_Data 0;
BA_ "GenSigAutoGenDsp" SG_ 824 TP_dyn_Data 0;
BA_ "GenSigAutoGenSnd" SG_ 824 TP_dyn_Data 0;
BA_ "GenSigSendType" SG_ 824 TP_dyn_Data 7;
BA_ "NWM-WakeupAllowed" SG_ 824 TP_dyn_Data 0;
BA_ "GenSigAutoGenDsp" SG_ 825 TP_dyn_Data 0;
BA_ "GenSigAutoGenSnd" SG_ 825 TP_dyn_Data 0;
BA_ "GenSigSendType" SG_ 825 TP_dyn_Data 7;
BA_ "NWM-WakeupAllowed" SG_ 825 TP_dyn_Data 0;
BA_ "GenSigAutoGenDsp" SG_ 760 TP_dyn_Data 0;
BA_ "GenSigAutoGenSnd" SG_ 760 TP_dyn_Data 0;
BA_ "GenSigSendType" SG_ 760 TP_dyn_Data 7;
BA_ "NWM-WakeupAllowed" SG_ 760 TP_dyn_Data 0;
BA_ "GenSigAutoGenDsp" SG_ 761 TP_dyn_Data 0;
BA_ "GenSigAutoGenSnd" SG_ 761 TP_dyn_Data 0;
BA_ "GenSigSendType" SG_ 761 TP_dyn_Data 7;
BA_ "NWM-WakeupAllowed" SG_ 761 TP_dyn_Data 0;
BA_ "GenSigAutoGenDsp" SG_ 828 TP_dyn_Data 0;
BA_ "GenSigAutoGenSnd" SG_ 828 TP_dyn_Data 0;
BA_ "GenSigSendType" SG_ 828 TP_dyn_Data 7;
BA_ "NWM-WakeupAllowed" SG_ 828 TP_dyn_Data 0;
BA_ "GenSigAutoGenDsp" SG_ 829 TP_dyn_Data 0;
BA_ "GenSigAutoGenSnd" SG_ 829 TP_dyn_Data 0;
BA_ "GenSigSendType" SG_ 829 TP_dyn_Data 7;
BA_ "NWM-WakeupAllowed" SG_ 829 TP_dyn_Data 0;
BA_ "GenSigAutoGenDsp" SG_ 830 TP_dyn_Data 0;
BA_ "GenSigAutoGenSnd" SG_ 830 TP_dyn_Data 0;
BA_ "GenSigSendType" SG_ 830 TP_dyn_Data 7;
BA_ "NWM-WakeupAllowed" SG_ 830 TP_dyn_Data 0;
BA_ "GenSigAutoGenDsp" SG_ 831 TP_dyn_Data 0;
BA_ "GenSigAutoGenSnd" SG_ 831 TP_dyn_Data 0;
BA_ "GenSigSendType" SG_ 831 TP_dyn_Data 7;
BA_ "NWM-WakeupAllowed" SG_ 831 TP_dyn_Data 0;
BA_ "GenSigAutoGenDsp" SG_ 1872 TP_dyn_Data 0;
BA_ "GenSigAutoGenSnd" SG_ 1872 TP_dyn_Data 0;
BA_ "GenSigSendType" SG_ 1872 TP_dyn_Data 7;
BA_ "NWM-WakeupAllowed" SG_ 1872 TP_dyn_Data 0;
BA_ "GenSigAutoGenDsp" SG_ 1873 TP_dyn_Data 0;
BA_ "GenSigAutoGenSnd" SG_ 1873 TP_dyn_Data 0;
BA_ "GenSigSendType" SG_ 1873 TP_dyn_Data 7;
BA_ "NWM-WakeupAllowed" SG_ 1873 TP_dyn_Data 0;
BA_ "GenSigAutoGenDsp" SG_ 1956 TP_dyn_Data 0;
BA_ "GenSigAutoGenSnd" SG_ 1956 TP_dyn_Data 0;
BA_ "GenSigSendType" SG_ 1956 TP_dyn_Data 7;
BA_ "NWM-WakeupAllowed" SG_ 1956 TP_dyn_Data 0;
BA_ "GenSigAutoGenDsp" SG_ 1957 TP_dyn_Data 0;
BA_ "GenSigAutoGenSnd" SG_ 1957 TP_dyn_Data 0;
BA_ "GenSigSendType" SG_ 1957 TP_dyn_Data 7;
BA_ "NWM-WakeupAllowed" SG_ 1957 TP_dyn_Data 0;
BA_ "GenSigAutoGenDsp" SG_ 794 TP_dyn_Data 0;
BA_ "GenSigAutoGenSnd" SG_ 794 TP_dyn_Data 0;
BA_ "GenSigSendType" SG_ 794 TP_dyn_Data 7;
BA_ "NWM-WakeupAllowed" SG_ 794 TP_dyn_Data 0;
BA_ "GenSigAutoGenDsp" SG_ 795 TP_dyn_Data 0;
BA_ "GenSigAutoGenSnd" SG_ 795 TP_dyn_Data 0;
BA_ "GenSigSendType" SG_ 795 TP_dyn_Data 7;
BA_ "NWM-WakeupAllowed" SG_ 795 TP_dyn_Data 0;
BA_ "GenSigAutoGenDsp" SG_ 792 TP_dyn_Data 0;
BA_ "GenSigAutoGenSnd" SG_ 792 TP_dyn_Data 0;
BA_ "GenSigSendType" SG_ 792 TP_dyn_Data 7;
BA_ "NWM-WakeupAllowed" SG_ 792 TP_dyn_Data 0;
BA_ "GenSigAutoGenDsp" SG_ 793 TP_dyn_Data 0;
BA_ "GenSigAutoGenSnd" SG_ 793 TP_dyn_Data 0;
BA_ "GenSigSendType" SG_ 793 TP_dyn_Data 7;
BA_ "NWM-WakeupAllowed" SG_ 793 TP_dyn_Data 0;
BA_ "GenSigAutoGenDsp" SG_ 766 TP_dyn_Data 0;
BA_ "GenSigAutoGenSnd" SG_ 766 TP_dyn_Data 0;
BA_ "GenSigSendType" SG_ 766 TP_dyn_Data 7;
BA_ "NWM-WakeupAllowed" SG_ 766 TP_dyn_Data 0;
BA_ "GenSigAutoGenDsp" SG_ 767 TP_dyn_Data 0;
BA_ "GenSigAutoGenSnd" SG_ 767 TP_dyn_Data 0;
BA_ "GenSigSendType" SG_ 767 TP_dyn_Data 7;
BA_ "NWM-WakeupAllowed" SG_ 767 TP_dyn_Data 0;
BA_ "GenSigAutoGenDsp" SG_ 1856 TP_dyn_Data 0;
BA_ "GenSigAutoGenSnd" SG_ 1856 TP_dyn_Data 0;
BA_ "GenSigSendType" SG_ 1856 TP_dyn_Data 7;
BA_ "NWM-WakeupAllowed" SG_ 1856 TP_dyn_Data 0;
BA_ "GenSigTimeoutMsg_DME_EDC16CP3000" SG_ 1856 TP_dyn_Data 1856;
BA_ "GenSigTimeoutMsg_DME_ME7_MED9_C6" SG_ 1856 TP_dyn_Data 1856;
BA_ "GenSigTimeoutMsg_DME_SIMOS6_C6" SG_ 1856 TP_dyn_Data 1856;
BA_ "GenSigAutoGenDsp" SG_ 1857 TP_dyn_Data 0;
BA_ "GenSigAutoGenSnd" SG_ 1857 TP_dyn_Data 0;
BA_ "GenSigSendType" SG_ 1857 TP_dyn_Data 7;
BA_ "NWM-WakeupAllowed" SG_ 1857 TP_dyn_Data 0;
BA_ "GenSigTimeoutMsg_DME_EDC16CP3000" SG_ 1857 TP_dyn_Data 1857;
BA_ "GenSigTimeoutMsg_DME_ME7_MED9_C6" SG_ 1857 TP_dyn_Data 1857;
BA_ "GenSigTimeoutMsg_DME_SIMOS6_C6" SG_ 1857 TP_dyn_Data 1857;
BA_ "GenSigAutoGenDsp" SG_ 1858 TP_dyn_Data 0;
BA_ "GenSigAutoGenSnd" SG_ 1858 TP_dyn_Data 0;
BA_ "GenSigSendType" SG_ 1858 TP_dyn_Data 7;
BA_ "NWM-WakeupAllowed" SG_ 1858 TP_dyn_Data 0;
BA_ "GenSigTimeoutMsg_DME_EDC16CP3000" SG_ 1858 TP_dyn_Data 1858;
BA_ "GenSigTimeoutMsg_DME_ME7_MED9_C6" SG_ 1858 TP_dyn_Data 1858;
BA_ "GenSigTimeoutMsg_DME_SIMOS6_C6" SG_ 1858 TP_dyn_Data 1858;
BA_ "GenSigAutoGenDsp" SG_ 1859 TP_dyn_Data 0;
BA_ "GenSigAutoGenSnd" SG_ 1859 TP_dyn_Data 0;
BA_ "GenSigSendType" SG_ 1859 TP_dyn_Data 7;
BA_ "NWM-WakeupAllowed" SG_ 1859 TP_dyn_Data 0;
BA_ "GenSigTimeoutMsg_DME_EDC16CP3000" SG_ 1859 TP_dyn_Data 1859;
BA_ "GenSigTimeoutMsg_DME_ME7_MED9_C6" SG_ 1859 TP_dyn_Data 1859;
BA_ "GenSigTimeoutMsg_DME_SIMOS6_C6" SG_ 1859 TP_dyn_Data 1859;
BA_ "GenSigAutoGenDsp" SG_ 1860 TP_dyn_Data 0;
BA_ "GenSigAutoGenSnd" SG_ 1860 TP_dyn_Data 0;
BA_ "GenSigSendType" SG_ 1860 TP_dyn_Data 7;
BA_ "NWM-WakeupAllowed" SG_ 1860 TP_dyn_Data 0;
BA_ "GenSigTimeoutMsg_DME_Slave" SG_ 1860 TP_dyn_Data 1860;
BA_ "GenSigAutoGenDsp" SG_ 1861 TP_dyn_Data 0;
BA_ "GenSigAutoGenSnd" SG_ 1861 TP_dyn_Data 0;
BA_ "GenSigSendType" SG_ 1861 TP_dyn_Data 7;
BA_ "NWM-WakeupAllowed" SG_ 1861 TP_dyn_Data 0;
BA_ "GenSigTimeoutMsg_DME_Slave" SG_ 1861 TP_dyn_Data 1861;
BA_ "GenSigAutoGenDsp" SG_ 1864 TP_dyn_Data 0;
BA_ "GenSigAutoGenSnd" SG_ 1864 TP_dyn_Data 0;
BA_ "GenSigSendType" SG_ 1864 TP_dyn_Data 7;
BA_ "NWM-WakeupAllowed" SG_ 1864 TP_dyn_Data 0;
BA_ "GenSigAutoGenDsp" SG_ 1865 TP_dyn_Data 0;
BA_ "GenSigAutoGenSnd" SG_ 1865 TP_dyn_Data 0;
BA_ "GenSigSendType" SG_ 1865 TP_dyn_Data 7;
BA_ "NWM-WakeupAllowed" SG_ 1865 TP_dyn_Data 0;
BA_ "GenSigAutoGenDsp" SG_ 1240 TP_dyn_Data 0;
BA_ "GenSigAutoGenSnd" SG_ 1240 TP_dyn_Data 0;
BA_ "GenSigSendType" SG_ 1240 TP_dyn_Data 7;
BA_ "NWM-WakeupAllowed" SG_ 1240 TP_dyn_Data 0;
BA_ "GenSigAutoGenDsp" SG_ 1241 TP_dyn_Data 0;
BA_ "GenSigAutoGenSnd" SG_ 1241 TP_dyn_Data 0;
BA_ "GenSigSendType" SG_ 1241 TP_dyn_Data 7;
BA_ "NWM-WakeupAllowed" SG_ 1241 TP_dyn_Data 0;
BA_ "GenSigAutoGenDsp" SG_ 1928 TP_dyn_Data 0;
BA_ "GenSigAutoGenSnd" SG_ 1928 TP_dyn_Data 0;
BA_ "GenSigSendType" SG_ 1928 TP_dyn_Data 7;
BA_ "NWM-WakeupAllowed" SG_ 1928 TP_dyn_Data 0;
BA_ "GenSigAutoGenDsp" SG_ 1929 TP_dyn_Data 0;
BA_ "GenSigAutoGenSnd" SG_ 1929 TP_dyn_Data 0;
BA_ "GenSigSendType" SG_ 1929 TP_dyn_Data 7;
BA_ "NWM-WakeupAllowed" SG_ 1929 TP_dyn_Data 0;
BA_ "GenSigAutoGenDsp" SG_ 802 TP_dyn_Data 0;
BA_ "GenSigAutoGenSnd" SG_ 802 TP_dyn_Data 0;
BA_ "GenSigSendType" SG_ 802 TP_dyn_Data 7;
BA_ "NWM-WakeupAllowed" SG_ 802 TP_dyn_Data 0;
BA_ "GenSigAutoGenDsp" SG_ 803 TP_dyn_Data 0;
BA_ "GenSigAutoGenSnd" SG_ 803 TP_dyn_Data 0;
BA_ "GenSigSendType" SG_ 803 TP_dyn_Data 7;
BA_ "NWM-WakeupAllowed" SG_ 803 TP_dyn_Data 0;
BA_ "GenSigAutoGenDsp" SG_ 764 TP_dyn_Data 0;
BA_ "GenSigAutoGenSnd" SG_ 764 TP_dyn_Data 0;
BA_ "GenSigSendType" SG_ 764 TP_dyn_Data 7;
BA_ "NWM-WakeupAllowed" SG_ 764 TP_dyn_Data 0;
BA_ "GenSigAutoGenDsp" SG_ 765 TP_dyn_Data 0;
BA_ "GenSigAutoGenSnd" SG_ 765 TP_dyn_Data 0;
BA_ "GenSigSendType" SG_ 765 TP_dyn_Data 7;
BA_ "NWM-WakeupAllowed" SG_ 765 TP_dyn_Data 0;
BA_ "GenSigAutoGenDsp" SG_ 804 TP_dyn_Data 0;
BA_ "GenSigAutoGenSnd" SG_ 804 TP_dyn_Data 0;
BA_ "GenSigSendType" SG_ 804 TP_dyn_Data 7;
BA_ "NWM-WakeupAllowed" SG_ 804 TP_dyn_Data 0;
BA_ "GenSigAutoGenDsp" SG_ 805 TP_dyn_Data 0;
BA_ "GenSigAutoGenSnd" SG_ 805 TP_dyn_Data 0;
BA_ "GenSigSendType" SG_ 805 TP_dyn_Data 7;
BA_ "NWM-WakeupAllowed" SG_ 805 TP_dyn_Data 0;
BA_ "GenSigAutoGenDsp" SG_ 1976 TP_dyn_Data 0;
BA_ "GenSigAutoGenSnd" SG_ 1976 TP_dyn_Data 0;
BA_ "GenSigSendType" SG_ 1976 TP_dyn_Data 7;
BA_ "NWM-WakeupAllowed" SG_ 1976 TP_dyn_Data 0;
BA_ "GenSigAutoGenDsp" SG_ 1977 TP_dyn_Data 0;
BA_ "GenSigAutoGenSnd" SG_ 1977 TP_dyn_Data 0;
BA_ "GenSigSendType" SG_ 1977 TP_dyn_Data 7;
BA_ "NWM-WakeupAllowed" SG_ 1977 TP_dyn_Data 0;
BA_ "GenSigAutoGenDsp" SG_ 1264 TP_dyn_Data 0;
BA_ "GenSigAutoGenSnd" SG_ 1264 TP_dyn_Data 0;
BA_ "GenSigSendType" SG_ 1264 TP_dyn_Data 7;
BA_ "NWM-WakeupAllowed" SG_ 1264 TP_dyn_Data 0;
BA_ "GenSigAutoGenDsp" SG_ 1265 TP_dyn_Data 0;
BA_ "GenSigAutoGenSnd" SG_ 1265 TP_dyn_Data 0;
BA_ "GenSigSendType" SG_ 1265 TP_dyn_Data 7;
BA_ "NWM-WakeupAllowed" SG_ 1265 TP_dyn_Data 0;
BA_ "GenSigAutoGenDsp" SG_ 1268 TP_dyn_Data 0;
BA_ "GenSigAutoGenSnd" SG_ 1268 TP_dyn_Data 0;
BA_ "GenSigSendType" SG_ 1268 TP_dyn_Data 7;
BA_ "NWM-WakeupAllowed" SG_ 1268 TP_dyn_Data 0;
BA_ "GenSigAutoGenDsp" SG_ 1269 TP_dyn_Data 0;
BA_ "GenSigAutoGenSnd" SG_ 1269 TP_dyn_Data 0;
BA_ "GenSigSendType" SG_ 1269 TP_dyn_Data 7;
BA_ "NWM-WakeupAllowed" SG_ 1269 TP_dyn_Data 0;
BA_ "GenSigAutoGenDsp" SG_ 768 TP_dyn_Data 0;
BA_ "GenSigAutoGenSnd" SG_ 768 TP_dyn_Data 0;
BA_ "GenSigSendType" SG_ 768 TP_dyn_Data 7;
BA_ "NWM-WakeupAllowed" SG_ 768 TP_dyn_Data 0;
BA_ "GenSigAutoGenDsp" SG_ 769 TP_dyn_Data 0;
BA_ "GenSigAutoGenSnd" SG_ 769 TP_dyn_Data 0;
BA_ "GenSigSendType" SG_ 769 TP_dyn_Data 7;
BA_ "NWM-WakeupAllowed" SG_ 769 TP_dyn_Data 0;
BA_ "GenSigAutoGenDsp" SG_ 786 TP_dyn_Data 0;
BA_ "GenSigAutoGenSnd" SG_ 786 TP_dyn_Data 0;
BA_ "GenSigSendType" SG_ 786 TP_dyn_Data 7;
BA_ "NWM-WakeupAllowed" SG_ 786 TP_dyn_Data 0;
BA_ "GenSigAutoGenDsp" SG_ 787 TP_dyn_Data 0;
BA_ "GenSigAutoGenSnd" SG_ 787 TP_dyn_Data 0;
BA_ "GenSigSendType" SG_ 787 TP_dyn_Data 7;
BA_ "NWM-WakeupAllowed" SG_ 787 TP_dyn_Data 0;
BA_ "GenSigAutoGenDsp" SG_ 784 TP_dyn_Data 0;
BA_ "GenSigAutoGenSnd" SG_ 784 TP_dyn_Data 0;
BA_ "GenSigSendType" SG_ 784 TP_dyn_Data 7;
BA_ "NWM-WakeupAllowed" SG_ 784 TP_dyn_Data 0;
BA_ "GenSigAutoGenDsp" SG_ 785 TP_dyn_Data 0;
BA_ "GenSigAutoGenSnd" SG_ 785 TP_dyn_Data 0;
BA_ "GenSigSendType" SG_ 785 TP_dyn_Data 7;
BA_ "NWM-WakeupAllowed" SG_ 785 TP_dyn_Data 0;
BA_ "GenSigAutoGenDsp" SG_ 788 TP_dyn_Data 0;
BA_ "GenSigAutoGenSnd" SG_ 788 TP_dyn_Data 0;
BA_ "GenSigSendType" SG_ 788 TP_dyn_Data 7;
BA_ "NWM-WakeupAllowed" SG_ 788 TP_dyn_Data 0;
BA_ "GenSigAutoGenDsp" SG_ 789 TP_dyn_Data 0;
BA_ "GenSigAutoGenSnd" SG_ 789 TP_dyn_Data 0;
BA_ "GenSigSendType" SG_ 789 TP_dyn_Data 7;
BA_ "NWM-WakeupAllowed" SG_ 789 TP_dyn_Data 0;
BA_ "GenSigAutoGenDsp" SG_ 790 TP_dyn_Data 0;
BA_ "GenSigAutoGenSnd" SG_ 790 TP_dyn_Data 0;
BA_ "GenSigSendType" SG_ 790 TP_dyn_Data 7;
BA_ "NWM-WakeupAllowed" SG_ 790 TP_dyn_Data 0;
BA_ "GenSigAutoGenDsp" SG_ 791 TP_dyn_Data 0;
BA_ "GenSigAutoGenSnd" SG_ 791 TP_dyn_Data 0;
BA_ "GenSigSendType" SG_ 791 TP_dyn_Data 7;
BA_ "NWM-WakeupAllowed" SG_ 791 TP_dyn_Data 0;
BA_ "GenSigAutoGenDsp" SG_ 515 TP_Er_Data 0;
BA_ "GenSigAutoGenSnd" SG_ 515 TP_Er_Data 0;
BA_ "GenSigSendType" SG_ 515 TP_Er_Data 7;
BA_ "NWM-WakeupAllowed" SG_ 515 TP_Er_Data 0;
BA_ "GenSigAutoGenDsp" SG_ 523 TP_Er_Data 0;
BA_ "GenSigAutoGenSnd" SG_ 523 TP_Er_Data 0;
BA_ "GenSigSendType" SG_ 523 TP_Er_Data 7;
BA_ "NWM-WakeupAllowed" SG_ 523 TP_Er_Data 0;
BA_ "GenSigAutoGenDsp" SG_ 517 TP_Er_Data 0;
BA_ "GenSigAutoGenSnd" SG_ 517 TP_Er_Data 0;
BA_ "GenSigSendType" SG_ 517 TP_Er_Data 7;
BA_ "NWM-WakeupAllowed" SG_ 517 TP_Er_Data 0;
BA_ "GenSigAutoGenDsp" SG_ 579 TP_Er_Data 0;
BA_ "GenSigAutoGenSnd" SG_ 579 TP_Er_Data 0;
BA_ "GenSigSendType" SG_ 579 TP_Er_Data 7;
BA_ "NWM-WakeupAllowed" SG_ 579 TP_Er_Data 0;
BA_ "GenSigAutoGenDsp" SG_ 563 TP_Er_Data 0;
BA_ "GenSigAutoGenSnd" SG_ 563 TP_Er_Data 0;
BA_ "GenSigSendType" SG_ 563 TP_Er_Data 7;
BA_ "NWM-WakeupAllowed" SG_ 563 TP_Er_Data 0;
BA_ "GenSigAutoGenDsp" SG_ 591 TP_Er_Data 0;
BA_ "GenSigAutoGenSnd" SG_ 591 TP_Er_Data 0;
BA_ "GenSigSendType" SG_ 591 TP_Er_Data 7;
BA_ "NWM-WakeupAllowed" SG_ 591 TP_Er_Data 0;
BA_ "GenSigAutoGenDsp" SG_ 595 TP_Er_Data 0;
BA_ "GenSigAutoGenSnd" SG_ 595 TP_Er_Data 0;
BA_ "GenSigSendType" SG_ 595 TP_Er_Data 7;
BA_ "NWM-WakeupAllowed" SG_ 595 TP_Er_Data 0;
BA_ "GenSigAutoGenDsp" SG_ 518 TP_Er_Data 0;
BA_ "GenSigAutoGenSnd" SG_ 518 TP_Er_Data 0;
BA_ "GenSigSendType" SG_ 518 TP_Er_Data 7;
BA_ "NWM-WakeupAllowed" SG_ 518 TP_Er_Data 0;
BA_ "GenSigAutoGenDsp" SG_ 557 TP_Er_Data 0;
BA_ "GenSigAutoGenSnd" SG_ 557 TP_Er_Data 0;
BA_ "GenSigSendType" SG_ 557 TP_Er_Data 7;
BA_ "NWM-WakeupAllowed" SG_ 557 TP_Er_Data 0;
BA_ "GenSigAutoGenDsp" SG_ 537 TP_Er_Data 0;
BA_ "GenSigAutoGenSnd" SG_ 537 TP_Er_Data 0;
BA_ "GenSigSendType" SG_ 537 TP_Er_Data 7;
BA_ "NWM-WakeupAllowed" SG_ 537 TP_Er_Data 0;
BA_ "GenSigAutoGenDsp" SG_ 561 TP_Er_Data 0;
BA_ "GenSigAutoGenSnd" SG_ 561 TP_Er_Data 0;
BA_ "GenSigSendType" SG_ 561 TP_Er_Data 7;
BA_ "NWM-WakeupAllowed" SG_ 561 TP_Er_Data 0;
BA_ "GenSigAutoGenDsp" SG_ 594 TP_Er_Data 0;
BA_ "GenSigAutoGenSnd" SG_ 594 TP_Er_Data 0;
BA_ "GenSigSendType" SG_ 594 TP_Er_Data 7;
BA_ "NWM-WakeupAllowed" SG_ 594 TP_Er_Data 0;
BA_ "GenSigAutoGenDsp" SG_ 514 TP_Er_Data 0;
BA_ "GenSigAutoGenSnd" SG_ 514 TP_Er_Data 0;
BA_ "GenSigSendType" SG_ 514 TP_Er_Data 7;
BA_ "NWM-WakeupAllowed" SG_ 514 TP_Er_Data 0;
BA_ "GenSigAutoGenDsp" SG_ 564 TP_Er_Data 0;
BA_ "GenSigAutoGenSnd" SG_ 564 TP_Er_Data 0;
BA_ "GenSigSendType" SG_ 564 TP_Er_Data 7;
BA_ "NWM-WakeupAllowed" SG_ 564 TP_Er_Data 0;
BA_ "GenSigAutoGenDsp" SG_ 606 TP_Er_Data 0;
BA_ "GenSigAutoGenSnd" SG_ 606 TP_Er_Data 0;
BA_ "GenSigSendType" SG_ 606 TP_Er_Data 7;
BA_ "NWM-WakeupAllowed" SG_ 606 TP_Er_Data 0;
BA_ "GenSigAutoGenDsp" SG_ 605 TP_Er_Data 0;
BA_ "GenSigAutoGenSnd" SG_ 605 TP_Er_Data 0;
BA_ "GenSigSendType" SG_ 605 TP_Er_Data 7;
BA_ "NWM-WakeupAllowed" SG_ 605 TP_Er_Data 0;
BA_ "GenSigAutoGenDsp" SG_ 545 TP_Er_Data 0;
BA_ "GenSigAutoGenSnd" SG_ 545 TP_Er_Data 0;
BA_ "GenSigSendType" SG_ 545 TP_Er_Data 7;
BA_ "NWM-WakeupAllowed" SG_ 545 TP_Er_Data 0;
BA_ "GenSigAutoGenDsp" SG_ 544 TP_Er_Data 0;
BA_ "GenSigAutoGenSnd" SG_ 544 TP_Er_Data 0;
BA_ "GenSigSendType" SG_ 544 TP_Er_Data 7;
BA_ "NWM-WakeupAllowed" SG_ 544 TP_Er_Data 0;
BA_ "GenSigAutoGenDsp" SG_ 552 TP_Er_Data 0;
BA_ "GenSigAutoGenSnd" SG_ 552 TP_Er_Data 0;
BA_ "GenSigSendType" SG_ 552 TP_Er_Data 7;
BA_ "NWM-WakeupAllowed" SG_ 552 TP_Er_Data 0;
BA_ "GenSigAutoGenDsp" SG_ 556 TP_Er_Data 0;
BA_ "GenSigAutoGenSnd" SG_ 556 TP_Er_Data 0;
BA_ "GenSigSendType" SG_ 556 TP_Er_Data 7;
BA_ "NWM-WakeupAllowed" SG_ 556 TP_Er_Data 0;
BA_ "GenSigAutoGenDsp" SG_ 581 TP_Er_Data 0;
BA_ "GenSigAutoGenSnd" SG_ 581 TP_Er_Data 0;
BA_ "GenSigSendType" SG_ 581 TP_Er_Data 7;
BA_ "NWM-WakeupAllowed" SG_ 581 TP_Er_Data 0;
BA_ "GenSigAutoGenDsp" SG_ 519 TP_Er_Data 0;
BA_ "GenSigAutoGenSnd" SG_ 519 TP_Er_Data 0;
BA_ "GenSigSendType" SG_ 519 TP_Er_Data 7;
BA_ "NWM-WakeupAllowed" SG_ 519 TP_Er_Data 0;
BA_ "GenSigAutoGenDsp" SG_ 584 TP_Er_Data 0;
BA_ "GenSigAutoGenSnd" SG_ 584 TP_Er_Data 0;
BA_ "GenSigSendType" SG_ 584 TP_Er_Data 7;
BA_ "NWM-WakeupAllowed" SG_ 584 TP_Er_Data 0;
BA_ "GenSigAutoGenDsp" SG_ 538 TP_Er_Data 0;
BA_ "GenSigAutoGenSnd" SG_ 538 TP_Er_Data 0;
BA_ "GenSigSendType" SG_ 538 TP_Er_Data 7;
BA_ "NWM-WakeupAllowed" SG_ 538 TP_Er_Data 0;
BA_ "GenSigAutoGenDsp" SG_ 531 TP_Er_Data 0;
BA_ "GenSigAutoGenSnd" SG_ 531 TP_Er_Data 0;
BA_ "GenSigSendType" SG_ 531 TP_Er_Data 7;
BA_ "NWM-WakeupAllowed" SG_ 531 TP_Er_Data 0;
BA_ "GenSigAutoGenDsp" SG_ 600 TP_Er_Data 0;
BA_ "GenSigAutoGenSnd" SG_ 600 TP_Er_Data 0;
BA_ "GenSigSendType" SG_ 600 TP_Er_Data 7;
BA_ "NWM-WakeupAllowed" SG_ 600 TP_Er_Data 0;
BA_ "GenSigAutoGenDsp" SG_ 592 TP_Er_Data 0;
BA_ "GenSigAutoGenSnd" SG_ 592 TP_Er_Data 0;
BA_ "GenSigSendType" SG_ 592 TP_Er_Data 7;
BA_ "NWM-WakeupAllowed" SG_ 592 TP_Er_Data 0;
BA_ "GenSigAutoGenDsp" SG_ 596 TP_Er_Data 0;
BA_ "GenSigAutoGenSnd" SG_ 596 TP_Er_Data 0;
BA_ "GenSigSendType" SG_ 596 TP_Er_Data 7;
BA_ "NWM-WakeupAllowed" SG_ 596 TP_Er_Data 0;
BA_ "GenSigAutoGenDsp" SG_ 610 TP_Er_Data 0;
BA_ "GenSigAutoGenSnd" SG_ 610 TP_Er_Data 0;
BA_ "GenSigSendType" SG_ 610 TP_Er_Data 7;
BA_ "NWM-WakeupAllowed" SG_ 610 TP_Er_Data 0;
BA_ "GenSigAutoGenDsp" SG_ 565 TP_Er_Data 0;
BA_ "GenSigAutoGenSnd" SG_ 565 TP_Er_Data 0;
BA_ "GenSigSendType" SG_ 565 TP_Er_Data 7;
BA_ "NWM-WakeupAllowed" SG_ 565 TP_Er_Data 0;
BA_ "GenSigAutoGenDsp" SG_ 550 TP_Er_Data 0;
BA_ "GenSigAutoGenSnd" SG_ 550 TP_Er_Data 0;
BA_ "GenSigSendType" SG_ 550 TP_Er_Data 7;
BA_ "NWM-WakeupAllowed" SG_ 550 TP_Er_Data 0;
BA_ "GenSigAutoGenDsp" SG_ 570 TP_Er_Data 0;
BA_ "GenSigAutoGenSnd" SG_ 570 TP_Er_Data 0;
BA_ "GenSigSendType" SG_ 570 TP_Er_Data 7;
BA_ "NWM-WakeupAllowed" SG_ 570 TP_Er_Data 0;
BA_ "GenSigAutoGenDsp" SG_ 575 TP_Er_Data 0;
BA_ "GenSigAutoGenSnd" SG_ 575 TP_Er_Data 0;
BA_ "GenSigSendType" SG_ 575 TP_Er_Data 7;
BA_ "NWM-WakeupAllowed" SG_ 575 TP_Er_Data 0;
BA_ "GenSigAutoGenDsp" SG_ 574 TP_Er_Data 0;
BA_ "GenSigAutoGenSnd" SG_ 574 TP_Er_Data 0;
BA_ "GenSigSendType" SG_ 574 TP_Er_Data 7;
BA_ "NWM-WakeupAllowed" SG_ 574 TP_Er_Data 0;
BA_ "GenSigAutoGenDsp" SG_ 513 TP_Er_Data 0;
BA_ "GenSigAutoGenSnd" SG_ 513 TP_Er_Data 0;
BA_ "GenSigSendType" SG_ 513 TP_Er_Data 7;
BA_ "NWM-WakeupAllowed" SG_ 513 TP_Er_Data 0;
BA_ "GenSigAutoGenDsp" SG_ 533 TP_Er_Data 0;
BA_ "GenSigAutoGenSnd" SG_ 533 TP_Er_Data 0;
BA_ "GenSigSendType" SG_ 533 TP_Er_Data 7;
BA_ "NWM-WakeupAllowed" SG_ 533 TP_Er_Data 0;
BA_ "GenSigAutoGenDsp" SG_ 534 TP_Er_Data 0;
BA_ "GenSigAutoGenSnd" SG_ 534 TP_Er_Data 0;
BA_ "GenSigSendType" SG_ 534 TP_Er_Data 7;
BA_ "NWM-WakeupAllowed" SG_ 534 TP_Er_Data 0;
BA_ "GenSigAutoGenDsp" SG_ 603 TP_Er_Data 0;
BA_ "GenSigAutoGenSnd" SG_ 603 TP_Er_Data 0;
BA_ "GenSigSendType" SG_ 603 TP_Er_Data 7;
BA_ "NWM-WakeupAllowed" SG_ 603 TP_Er_Data 0;
BA_ "GenSigAutoGenDsp" SG_ 516 TP_Er_Data 0;
BA_ "GenSigAutoGenSnd" SG_ 516 TP_Er_Data 0;
BA_ "GenSigSendType" SG_ 516 TP_Er_Data 7;
BA_ "NWM-WakeupAllowed" SG_ 516 TP_Er_Data 0;
BA_ "GenSigAutoGenDsp" SG_ 553 TP_Er_Data 0;
BA_ "GenSigAutoGenSnd" SG_ 553 TP_Er_Data 0;
BA_ "GenSigSendType" SG_ 553 TP_Er_Data 7;
BA_ "NWM-WakeupAllowed" SG_ 553 TP_Er_Data 0;
BA_ "GenSigAutoGenDsp" SG_ 607 TP_Er_Data 0;
BA_ "GenSigAutoGenSnd" SG_ 607 TP_Er_Data 0;
BA_ "GenSigSendType" SG_ 607 TP_Er_Data 7;
BA_ "NWM-WakeupAllowed" SG_ 607 TP_Er_Data 0;
BA_ "GenSigAutoGenDsp" SG_ 604 TP_Er_Data 0;
BA_ "GenSigAutoGenSnd" SG_ 604 TP_Er_Data 0;
BA_ "GenSigSendType" SG_ 604 TP_Er_Data 7;
BA_ "NWM-WakeupAllowed" SG_ 604 TP_Er_Data 0;
BA_ "GenSigAutoGenDsp" SG_ 554 TP_Er_Data 0;
BA_ "GenSigAutoGenSnd" SG_ 554 TP_Er_Data 0;
BA_ "GenSigSendType" SG_ 554 TP_Er_Data 7;
BA_ "NWM-WakeupAllowed" SG_ 554 TP_Er_Data 0;
BA_ "GenSigAutoGenDsp" SG_ 559 TP_Er_Data 0;
BA_ "GenSigAutoGenSnd" SG_ 559 TP_Er_Data 0;
BA_ "GenSigSendType" SG_ 559 TP_Er_Data 7;
BA_ "NWM-WakeupAllowed" SG_ 559 TP_Er_Data 0;
BA_ "GenSigAutoGenDsp" SG_ 540 TP_Er_Data 0;
BA_ "GenSigAutoGenSnd" SG_ 540 TP_Er_Data 0;
BA_ "GenSigSendType" SG_ 540 TP_Er_Data 7;
BA_ "NWM-WakeupAllowed" SG_ 540 TP_Er_Data 0;
BA_ "GenSigAutoGenDsp" SG_ 602 TP_Er_Data 0;
BA_ "GenSigAutoGenSnd" SG_ 602 TP_Er_Data 0;
BA_ "GenSigSendType" SG_ 602 TP_Er_Data 7;
BA_ "NWM-WakeupAllowed" SG_ 602 TP_Er_Data 0;
BA_ "GenSigAutoGenDsp" SG_ 597 TP_Er_Data 0;
BA_ "GenSigAutoGenSnd" SG_ 597 TP_Er_Data 0;
BA_ "GenSigSendType" SG_ 597 TP_Er_Data 7;
BA_ "NWM-WakeupAllowed" SG_ 597 TP_Er_Data 0;
BA_ "GenSigAutoGenDsp" SG_ 512 TP_Er_Data 0;
BA_ "GenSigAutoGenSnd" SG_ 512 TP_Er_Data 0;
BA_ "GenSigSendType" SG_ 512 TP_Er_Data 7;
BA_ "NWM-WakeupAllowed" SG_ 512 TP_Er_Data 0;
BA_ "GenSigAutoGenDsp" SG_ 527 TP_Er_Data 0;
BA_ "GenSigAutoGenSnd" SG_ 527 TP_Er_Data 0;
BA_ "GenSigSendType" SG_ 527 TP_Er_Data 7;
BA_ "NWM-WakeupAllowed" SG_ 527 TP_Er_Data 0;
BA_ "GenSigAutoGenDsp" SG_ 547 TP_Er_Data 0;
BA_ "GenSigAutoGenSnd" SG_ 547 TP_Er_Data 0;
BA_ "GenSigSendType" SG_ 547 TP_Er_Data 7;
BA_ "NWM-WakeupAllowed" SG_ 547 TP_Er_Data 0;
BA_ "GenSigAutoGenDsp" SG_ 546 TP_Er_Data 0;
BA_ "GenSigAutoGenSnd" SG_ 546 TP_Er_Data 0;
BA_ "GenSigSendType" SG_ 546 TP_Er_Data 7;
BA_ "NWM-WakeupAllowed" SG_ 546 TP_Er_Data 0;
BA_ "GenSigAutoGenDsp" SG_ 548 TP_Er_Data 0;
BA_ "GenSigAutoGenSnd" SG_ 548 TP_Er_Data 0;
BA_ "GenSigSendType" SG_ 548 TP_Er_Data 7;
BA_ "NWM-WakeupAllowed" SG_ 548 TP_Er_Data 0;
BA_ "GenSigAutoGenDsp" SG_ 549 TP_Er_Data 0;
BA_ "GenSigAutoGenSnd" SG_ 549 TP_Er_Data 0;
BA_ "GenSigSendType" SG_ 549 TP_Er_Data 7;
BA_ "NWM-WakeupAllowed" SG_ 549 TP_Er_Data 0;
BA_ "GenSigAutoGenDsp" SG_ 599 TP_Er_Data 0;
BA_ "GenSigAutoGenSnd" SG_ 599 TP_Er_Data 0;
BA_ "GenSigSendType" SG_ 599 TP_Er_Data 7;
BA_ "NWM-WakeupAllowed" SG_ 599 TP_Er_Data 0;
BA_ "GenSigAutoGenDsp" SG_ 588 TP_Er_Data 0;
BA_ "GenSigAutoGenSnd" SG_ 588 TP_Er_Data 0;
BA_ "GenSigSendType" SG_ 588 TP_Er_Data 7;
BA_ "NWM-WakeupAllowed" SG_ 588 TP_Er_Data 0;
BA_ "GenSigAutoGenDsp" SG_ 1394 CHK_ZAS 0;
BA_ "GenSigAutoGenSnd" SG_ 1394 CHK_ZAS 0;
BA_ "GenSigSendType" SG_ 1394 CHK_ZAS 7;
BA_ "NWM-WakeupAllowed" SG_ 1394 CHK_ZAS 0;
BA_ "GenSigTimeoutMsg__4CL_C6" SG_ 1394 CHK_ZAS 1394;
BA_ "GenSigTimeoutMsg_DME_SIMOS6_C6" SG_ 1394 CHK_ZAS 1394;
BA_ "GenSigTimeoutMsg_EPB_C6" SG_ 1394 CHK_ZAS 1394;
BA_ "GenSigAutoGenDsp" SG_ 1394 ZA1_KD_Fehler 0;
BA_ "GenSigAutoGenSnd" SG_ 1394 ZA1_KD_Fehler 0;
BA_ "GenSigSendType" SG_ 1394 ZA1_KD_Fehler 7;
BA_ "NWM-WakeupAllowed" SG_ 1394 ZA1_KD_Fehler 0;
BA_ "GenSigAutoGenDsp" SG_ 1394 ZA1_Klemme_L 0;
BA_ "GenSigAutoGenSnd" SG_ 1394 ZA1_Klemme_L 0;
BA_ "GenSigSendType" SG_ 1394 ZA1_Klemme_L 7;
BA_ "NWM-WakeupAllowed" SG_ 1394 ZA1_Klemme_L 0;
BA_ "GenSigAutoGenDsp" SG_ 1394 ZA1_ZAS_Kl_15 0;
BA_ "GenSigAutoGenSnd" SG_ 1394 ZA1_ZAS_Kl_15 0;
BA_ "GenSigSendType" SG_ 1394 ZA1_ZAS_Kl_15 7;
BA_ "NWM-WakeupAllowed" SG_ 1394 ZA1_ZAS_Kl_15 0;
BA_ "GenSigTimeoutMsg__4CL_C6" SG_ 1394 ZA1_ZAS_Kl_15 1394;
BA_ "GenSigTimeoutMsg_DME_SIMOS6_C6" SG_ 1394 ZA1_ZAS_Kl_15 1394;
BA_ "GenSigTimeoutMsg_EPB_C6" SG_ 1394 ZA1_ZAS_Kl_15 1394;
BA_ "GenSigAutoGenDsp" SG_ 1394 ZA1_ZAS_Kl_15SV 0;
BA_ "GenSigAutoGenSnd" SG_ 1394 ZA1_ZAS_Kl_15SV 0;
BA_ "GenSigSendType" SG_ 1394 ZA1_ZAS_Kl_15SV 7;
BA_ "NWM-WakeupAllowed" SG_ 1394 ZA1_ZAS_Kl_15SV 0;
BA_ "GenSigAutoGenDsp" SG_ 1394 ZA1_ZAS_Kl_50 0;
BA_ "GenSigAutoGenSnd" SG_ 1394 ZA1_ZAS_Kl_50 0;
BA_ "GenSigSendType" SG_ 1394 ZA1_ZAS_Kl_50 7;
BA_ "NWM-WakeupAllowed" SG_ 1394 ZA1_ZAS_Kl_50 0;
BA_ "GenSigTimeoutMsg_DME_SIMOS6_C6" SG_ 1394 ZA1_ZAS_Kl_50 1394;
BA_ "GenSigTimeoutMsg_EPB_C6" SG_ 1394 ZA1_ZAS_Kl_50 1394;
BA_ "GenSigTimeoutMsg_LWR_AFS_C6" SG_ 1394 ZA1_ZAS_Kl_50 1394;
BA_ "GenSigAutoGenDsp" SG_ 1394 ZA1_ZAS_Kl_50b 0;
BA_ "GenSigAutoGenSnd" SG_ 1394 ZA1_ZAS_Kl_50b 0;
BA_ "GenSigSendType" SG_ 1394 ZA1_ZAS_Kl_50b 7;
BA_ "NWM-WakeupAllowed" SG_ 1394 ZA1_ZAS_Kl_50b 0;
BA_ "GenSigAutoGenDsp" SG_ 1394 ZA1_ZAS_KL_P 0;
BA_ "GenSigAutoGenSnd" SG_ 1394 ZA1_ZAS_KL_P 0;
BA_ "GenSigSendType" SG_ 1394 ZA1_ZAS_KL_P 7;
BA_ "NWM-WakeupAllowed" SG_ 1394 ZA1_ZAS_KL_P 0;
BA_ "GenSigAutoGenDsp" SG_ 1394 ZA1_ZAS_Kl_S 0;
BA_ "GenSigAutoGenSnd" SG_ 1394 ZA1_ZAS_Kl_S 0;
BA_ "GenSigSendType" SG_ 1394 ZA1_ZAS_Kl_S 7;
BA_ "NWM-WakeupAllowed" SG_ 1394 ZA1_ZAS_Kl_S 0;
BA_ "GenSigTimeoutMsg_EPB_C6" SG_ 1394 ZA1_ZAS_Kl_S 1394;
BA_ "GenSigAutoGenDsp" SG_ 1394 ZA1_ZAS_Kl_X 0;
BA_ "GenSigAutoGenSnd" SG_ 1394 ZA1_ZAS_Kl_X 0;
BA_ "GenSigSendType" SG_ 1394 ZA1_ZAS_Kl_X 7;
BA_ "NWM-WakeupAllowed" SG_ 1394 ZA1_ZAS_Kl_X 0;
BA_ "GenSigTimeoutMsg__4CL_C6" SG_ 1394 ZA1_ZAS_Kl_X 1394;
BA_ "GenSigTimeoutMsg_LWR_AFS_C6" SG_ 1394 ZA1_ZAS_Kl_X 1394;
BA_ "GenSigAutoGenDsp" SG_ 1394 Zaehler_ZAS 0;
BA_ "GenSigAutoGenSnd" SG_ 1394 Zaehler_ZAS 0;
BA_ "GenSigSendType" SG_ 1394 Zaehler_ZAS 7;
BA_ "NWM-WakeupAllowed" SG_ 1394 Zaehler_ZAS 0;
BA_ "GenSigTimeoutMsg__4CL_C6" SG_ 1394 Zaehler_ZAS 1394;
BA_ "GenSigTimeoutMsg_DME_SIMOS6_C6" SG_ 1394 Zaehler_ZAS 1394;
BA_ "GenSigTimeoutMsg_EPB_C6" SG_ 1394 Zaehler_ZAS 1394;
VAL_ 1160 Istmoment_Getriebe 255 "Fehler" ;
VAL_ 1160 Oeltemperaturschutz 0 "keine_Anforderung" 1 "Schaltanforderung" ;
VAL_ 1160 Sollmoment_Getriebe 255 "Fehler" ;
VAL_ 1160 GRA_Bremseingrifffreigabe 0 "nicht_freigegeben" 1 "freigegeben" ;
VAL_ 1160 Luftpfad_aktiv 1 "Eingriff_Luftpfad" 0 "kein_Eingriff" ;
VAL_ 1160 Hoeheninfo 255 "Fehler" ;
VAL_ 1160 Partikelfilter_Regeneration 1 "Beeinflussung" 0 "keine_Beeinflussung" ;
VAL_ 1416 RLS_Stufe1 0 "nicht_angehoben" 1 "RLS_erste_Stufe" ;
VAL_ 1416 FSPE_Motor7 0 "kein_KD_Fehler_eingetr" 1 "KD_Fehler_eingetr" ;
VAL_ 1416 SIB_Motor 0 "CAN_wird_benoetigt" 1 "Sleep_bereit" ;
VAL_ 1416 Lastabwurf 1 "Stufe1" 2 "Stufe2" 3 "Stufe3" 0 "Stufe0" ;
VAL_ 1416 Ladedruck 255 "Fehler" ;
VAL_ 1416 Lastabwurf_Heizsysteme 0 "HLH_deaktiviert" 1 "HLH_aktiviert" ;
VAL_ 1416 Gluehkerzen_Brennr 15 "Fehler" ;
VAL_ 1416 Signum_MDG 0 "positiv" 1 "negativ" ;
VAL_ 1416 V_Begrenz_Aktivierbar 0 "vBegr_nicht_moeglich" 1 "vBegr_moeglich" ;
VAL_ 1416 Klemme_DFM 255 "Fehler" ;
VAL_ 1416 FStatus_Oeltemp_Motor 0 "Fstatus_iO" 1 "Fstatus_niO" ;
VAL_ 1416 RLS_Stufe2 0 "nicht_angehoben" 1 "RLS_Stufe2" ;
VAL_ 1416 Hoeheninfo 255 "Fehler" ;
VAL_ 1416 V_Begrenz_Aktiv 1 "vBegr_aktiv" 0 "vBegr_nicht_aktiv" ;
VAL_ 1416 Zusaetzliche_Kuehlung 1 "Anforderung" 0 "keine_Anforderung" ;
VAL_ 1416 Einschalten_Generator 1 "Generator_ein" 0 "Generator_aus" ;
VAL_ 1162 Avus_Motorschutz 1 "Drehzahlwarn_1" 2 "Drehzahlwarn_2" 0 "keine_Warnung" 3 "Drehzahlwarn_3" ;
VAL_ 1162 Oeldruck_Warn_Motor 1 "" 0 "Lampe_aus" ;
VAL_ 1162 Enable_Oeldr_Motor 0 "kein_Oeldrwarn_Motor" 1 "Oeldrwarn_Motor" ;
VAL_ 1408 Warm_Up_Cycle 0 "WCY_nicht_erkannt" 1 "WCY_erkannt" ;
VAL_ 1408 Verbrennungsart 1 "Otto" 0 "Diesel" ;
VAL_ 1408 Driving_Cycle 1 "DCY_erkannt" 0 "DCY_nicht_erkannt" ;
VAL_ 1408 Ansaugsystem 0 "Turbo" 1 "Sauger" ;
VAL_ 1408 Ansaugsystem 0 "Turbo" 1 "Sauger" ;
VAL_ 1408 Normed_Trip 1 "Normed_Trip_erkannt" 0 "Normed_Trip_nicht_erkannt" ;
VAL_ 1823 FSPE_Motorslave 1 "KD_Fehler_eingetr" 0 "kein_KD_Fehler_eingetr" ;
VAL_ 1424 FSPE_Niveau1 0 "kein_KD_Fehler_eingetr" 1 "KD_Fehler_eingetr" ;
VAL_ 1424 ESP_Beeinflussung 1 "ESP_angefordert" 0 "keine_ESP_Anf" ;
VAL_ 1424 MSG_Einschraenkung 0 "keine_Begr" 1 "Begr_angef" ;
VAL_ 1424 Verstellung_aktiv 1 "" 0 "inaktiv" ;
VAL_ 1424 Systemstatus 0 "nicht_funktionsfaehig" 1 "funktionsfaehig" ;
VAL_ 1424 Parkniveau 1 "aktiv" 0 "inaktiv" ;
VAL_ 1424 Verstellung_VL 1 "aktiv" 0 "inaktiv" ;
VAL_ 1424 Zwischenniveau 0 "kein_Zwischenniveau" 1 "Zwischenniveau" ;
VAL_ 1424 Niveaustati 4 "Hochniveau1" 5 "Hochniveau2" 1 "Untertiefniveau" 2 "Tiefniveau1" 3 "Normalniveau" 6 "Überhochniveau" 7 "Tiefniveau2" 9 "Verladeniveau(nur AU716)" 8 "Beladungniveau_(nur AU716)" ;
VAL_ 1424 Tiefniveaulampe 0 "Lampe_aus" 1 "Lampe_ein" ;
VAL_ 1424 Warnlampe 0 "Warnlampe_aus" 1 "Warnlampe_ein" ;
VAL_ 1424 Absenkung_Fahrzeug 0 "inaktiv" 1 "aktiv" ;
VAL_ 1424 Verstellung_in_Kuerze 0 "keine_Verstellung" 1 "Verstellung_erwartet" ;
VAL_ 1424 Anhebung_Fahrzeug 0 "inaktiv" 1 "aktiv" ;
VAL_ 1424 Verstellung_HR 1 "aktiv" 0 "inaktiv" ;
VAL_ 1424 Fehlerlampe_Niveau 1 "Lampe_ein" 0 "Lampe_aus" ;
VAL_ 1424 Taster_Niveau 0 "Taster_betaetigt" 1 "Taster_nicht_betaetigt" ;
VAL_ 1424 SIB_Niveau 0 "CAN_wird_benoetigt" 1 "Sleep_bereit" ;
VAL_ 1424 Fahrzeugart_Niveau 0 "beliebiges_Fahrzeug" 1 "Fzg_mit_Niveaureg" ;
VAL_ 1424 Verstellung_HL 1 "aktiv" 0 "inaktiv" ;
VAL_ 1424 Verstellung_VR 0 "inaktiv" 1 "aktiv" ;
VAL_ 1424 Kompressorlauf_in_Kuerze 1 "aktiv" 0 "inaktiv" ;
VAL_ 1424 Kompressor_laeuft 1 "Kompressor_laeuft" 0 "Kompressor_aus" ;
VAL_ 1428 Hoehenwert_HR 254 "Nicht_Initialisiert" 255 "Fehler" ;
VAL_ 1428 Hoehenwert_VL 254 "Nicht_initialisiert" 255 "Fehler" ;
VAL_ 1428 Hoehenwert_HL 254 "Nicht_Initialisiert" 255 "Fehler" ;
VAL_ 1428 Hoehenwert_VR 254 "Nicht_initialisiert" 255 "Fehler" ;
VAL_ 1434 Textbit4 1 "Textausgabe" 0 "kein_Text" ;
VAL_ 1434 Textbit2 1 "Textausgabe" 0 "kein_Text" ;
VAL_ 1434 Textbit3 1 "Textausgabe" 0 "kein_Text" ;
VAL_ 1434 Textbit1 1 "Textausgabe" 0 "kein_Text" ;
VAL_ 1434 Verfuegbarkeit_FIS 0 "FIS_nicht_verfuegbar" 1 "FIS_verfuegbar" ;
VAL_ 1434 Priorisierung_FIS 1 "FIS_oberste_Ebene" 0 "inaktiv" ;
VAL_ 1434 Anzeigebit21 1 "Anzeige" 0 "keine_Anzeige" ;
VAL_ 1434 Anzeigebit10 0 "keine_Anzeige" 1 "Anzeige" ;
VAL_ 1434 Anzeigebit18 0 "keine_Anzeige" 1 "Anzeige" ;
VAL_ 1434 Anzeigebit19 1 "Anzeige" 0 "keine_Anzeige" ;
VAL_ 1434 Anzeigebit9 1 "Anzeige" 0 "keine_Anzeige" ;
VAL_ 1434 Anzeigebit17 1 "Anzeige" 0 "keine_Anzeige" ;
VAL_ 1434 Anzeigebit20 0 "keine_Anzeige" 1 "Anzeige" ;
VAL_ 1434 Anzeigebit25 0 "keine_Anzeige" 1 "Anzeige" ;
VAL_ 1434 Anzeigebit24 0 "keine_Anzeige" 1 "Anzeige" ;
VAL_ 1434 Anzeigebit26 0 "keine_Anzeige" 1 "Anzeige" ;
VAL_ 1434 Anzeigebit22 0 "keine_Anzeige" 1 "Anzeige" ;
VAL_ 1434 Anzeigebit23 0 "keine_Anzeige" 1 "Anzeige" ;
VAL_ 2004 Einheit_Geschw_klasse 1 "" 0 "kmh" ;
VAL_ 2004 Alter_der_Daten 31 "Daten_veraltet" ;
VAL_ 2004 Signum_Startkruemmung_1 0 "positiv" 1 "negativ" ;
VAL_ 2004 Strassenklasse_3 0 "Dorfstrasse" 3 "Auf_Abfahrt_Rampe" 2 "Autobahn" 1 "Bundes_Landstrasse" ;
VAL_ 2004 Signum_Endkruemmung_3 1 "negativ" 0 "positiv" ;
VAL_ 2004 Endkruemmung_3 0 "Kruemmung_0" ;
VAL_ 2004 Endkruemmung_5 0 "Kruemmung_0" ;
VAL_ 2004 Signum_Endkruemmung_6 0 "positiv" 1 "negativ" ;
VAL_ 2004 Signum_Endkruemmung_4 0 "positiv" 1 "negativ" ;
VAL_ 2004 Signum_Endkruemmung_5 0 "positiv" 1 "negativ" ;
VAL_ 2004 Bes_Geschw_klasse_4 0 "normal" 1 "besonders" ;
VAL_ 2004 Bes_Geschw_klasse_6 1 "besonders" 0 "normal" ;
VAL_ 2004 Bes_Geschw_klasse_5 0 "normal" 1 "besonders" ;
VAL_ 2004 Bes_Geschw_klasse_3 0 "normal" 1 "besonders" ;
VAL_ 2004 Strassenklasse_4 1 "Bundes_Landstrasse" 2 "Autobahn" 0 "Dorfstrasse" 3 "Auf_Abfahrt_Rampe" ;
VAL_ 2004 Strassenklasse_6 2 "Autobahn" 1 "Bundes_Landstrasse" 0 "Dorfstrasse" 3 "Auf_Abfahrt_Rampe" ;
VAL_ 2004 Status_Unterfuehrung 1 "Unterfuehrung" 0 "keine_Unterfuehrung" ;
VAL_ 2004 Status_Innerorts 0 "Ausserorts" 1 "Innerorts" ;
VAL_ 2004 Aenderung_Innerorts 3 "nach_Segment3" 7 "nicht_definiert" 5 "nach_Segment5" 1 "nach_Segment1" 2 "nach_Segment2" 6 "nach_Segment6" 4 "nach_Segment4" 0 "keine_Veraenderung" ;
VAL_ 2004 Aenderung_Unterfuehrung 2 "nach_Segment2" 3 "nach_Segment3" 4 "nach_Segment4" 1 "nach_Segment1" 0 "keine_Veraenderung" 6 "nach_Segment6" 5 "nach_Segment5" ;
VAL_ 2004 Kreuzung 2 "nach_Segment2" 3 "nach_Segment3" 4 "nach_Segment4" 1 "nach_Segment1" 6 "nach_Segment6" 0 "keine_Kreuzung" 5 "nach_Segment5" 7 "nicht_definiert" ;
VAL_ 2004 Standort 1 "Eindeutiger_Standort" 2 "Route" 3 "nicht_erlaubt" 0 "Mehrdeutiger_Standort" ;
VAL_ 2004 Laengsfehler 3 "kleiner_20m" 1 "kleiner_5m" 6 "nicht_erlaubt" 0 "keine_Praediktion" 5 "groesser_50m" 4 "kleiner_50m" 2 "kleiner_10m" 7 "nicht_erlaubt" ;
VAL_ 2004 Verkehrsrichtung 0 "Rechtsverkehr" 1 "Linksverkehr" ;
VAL_ 2004 Digitalisierung 0 "Teildigitalisiert" 1 "Volldigitalisiert" ;
VAL_ 2004 Einbahnstrasse 1 "Einbahnstrasse" 0 "keine_Einbahnstrasse" ;
VAL_ 2004 Mux_Code_PSD 3 "Botschaft_verwerfen" ;
VAL_ 2004 Strassenklasse_1 2 "Autobahn" 0 "Dorfstrasse" 3 "Auf_Abfahrt_Rampe" 1 "Bundes_Landstrasse" ;
VAL_ 2004 Strassenklasse_2 3 "Auf_Abfahrt_Rampe" 1 "Bundes_Landstrasse" 2 "Autobahn" 0 "Dorfstrasse" ;
VAL_ 2004 Segmentlaenge_1 0 "Segment_nicht_vorhanden" ;
VAL_ 2004 Signum_Endkruemmung_1 1 "negativ" 0 "positiv" ;
VAL_ 2004 Endkruemmung_1 0 "Kruemmung_0" ;
VAL_ 2004 Bes_Geschw_klasse_1 0 "normal" 1 "besonders" ;
VAL_ 2004 Bes_Geschw_klasse_2 1 "besonders" 0 "normal" ;
VAL_ 2004 Signum_Endkruemmung_2 0 "positiv" 1 "negativ" ;
VAL_ 2004 Qualitaet 1 "ADAS_Qualitaet" 0 "keine_ADAS_Qualitaet" ;
VAL_ 1306 Fuellstandszeit_2 0 "kein_Wert" 1 "ung_Wert_Ueberlauf" ;
VAL_ 1306 Fuellstandszeit_1 2047 "ung_Wert_Ueberlauf" 0 "kein_Wert" ;
VAL_ 1306 Oeltemperaturzeit 0 "kein_Wert" 1023 "Bereichsueberlauf" ;
VAL_ 1306 Oelwarnschwelle 1 "Schwelle_ueberschritten" 0 "Schwelle_nicht_ueberschritten" ;
VAL_ 1306 Fuellstandszeit_3 0 "kein_Wert" 1 "ung_Wert_Ueberlauf" ;
VAL_ 1306 Oelwarnschwelle_pOue 0 "Schwelle_nicht_ueberschritten" 1 "Schwelle_ueberschritten" ;
VAL_ 1306 Fuellstandszeit_4 1 "ung_Wert_Ueberlauf" 0 "kein_Wert" ;
VAL_ 1306 Sensorfehler 1 "Fehler" 0 "Sensor_iO" ;
VAL_ 1306 Oelfuellstand_max_pO 1 "Schwelle_ueberschritten" 0 "Schwelle_nicht_ueberschritten" ;
VAL_ 1306 Oelfuellstand_max 1 "Schwelle_ueberschritten" 0 "Schwelle_nicht_ueberschritten" ;
